VERSION ""

NS_ :

BS_:

BU_: MCTM_LS TIM_LS EOCM2cp_K2_LS EOCM2cp_K1_LS ADIMa_LS BCM_LS SAM_SR_LS SAM_SL_LS SAM_PR_LS SAM_PL_LS CGM3a_LS Dummy_LS VICM_LS ECC_LS PEPS_LS AOS_LS SDM_PR_LS AOS2_LS DLM_LS SCCM_2_LS SCCM_1_LS UPA_LS ADIMb_LS

BO_ 2150760448 Airbag_Impact_Data: 8 SDM_PR_LS
 SG_ NotiFrntLfPasSeatOccSta : 20|3@0+ (1,0) [0|7] ""  MCTM_LS,EOCM2cp_K2_LS,CGM3a_LS,ADIMa_LS,ADIMb_LS
 SG_ NotSndRwRtSeatStat : 13|2@0+ (1,0) [0|3] ""  ADIMa_LS,ADIMb_LS,CGM3a_LS,EOCM2cp_K2_LS
 SG_ NotSndRwMdlSeatStat : 11|2@0+ (1,0) [0|3] ""  ADIMa_LS,ADIMb_LS,CGM3a_LS,EOCM2cp_K2_LS
 SG_ NotSndRwLtSeatStat : 15|2@0+ (1,0) [0|3] ""  ADIMa_LS,ADIMb_LS,CGM3a_LS,EOCM2cp_K2_LS
 SG_ NotPsSeatStat : 5|2@0+ (1,0) [0|3] ""  ADIMa_LS,ADIMb_LS,CGM3a_LS,EOCM2cp_K2_LS
 SG_ NotDrvSeatStat : 7|2@0+ (1,0) [0|3] ""  ADIMa_LS,ADIMb_LS,CGM3a_LS,EOCM2cp_K2_LS
 SG_ NotSecRowRtSeaOccStat : 9|2@0+ (1,0) [0|3] ""  ADIMa_LS,ADIMb_LS,CGM3a_LS,EOCM2cp_K2_LS
 SG_ NotSecRowLeSeaOccStat : 25|2@0+ (1,0) [0|3] ""  ADIMa_LS,ADIMb_LS,CGM3a_LS,EOCM2cp_K2_LS
 SG_ NotSecRowCtSeaOccStat : 27|2@0+ (1,0) [0|3] ""  ADIMa_LS,ADIMb_LS,CGM3a_LS,EOCM2cp_K2_LS
 SG_ NotiFrntPasSeatOccSta : 34|3@0+ (1,0) [0|7] ""  ADIMa_LS,ADIMb_LS,CGM3a_LS,EOCM2cp_K2_LS
 SG_ NotEventStat : 17|2@0+ (1,0) [0|3] ""  ADIMa_LS,ADIMb_LS,CGM3a_LS,EOCM2cp_K2_LS,ECC_LS,BCM_LS
 SG_ NotiEventCount : 63|8@0+ (1,0) [0|255] ""  AOS2_LS,ADIMa_LS,ADIMb_LS,CGM3a_LS,EOCM2cp_K2_LS,AOS_LS
 SG_ NESSRoSevSt : 48|1@0+ (1,0) [0|1] ""  AOS2_LS,ADIMa_LS,ADIMb_LS,CGM3a_LS,EOCM2cp_K2_LS,ECC_LS,VICM_LS,BCM_LS,AOS_LS
 SG_ NESSRiSiSevSt : 49|1@0+ (1,0) [0|1] ""  AOS2_LS,ADIMa_LS,ADIMb_LS,CGM3a_LS,EOCM2cp_K2_LS,ECC_LS,VICM_LS,BCM_LS,AOS_LS
 SG_ NESSReImpSevSt : 50|1@0+ (1,0) [0|1] ""  AOS2_LS,ADIMa_LS,ADIMb_LS,CGM3a_LS,EOCM2cp_K2_LS,ECC_LS,VICM_LS,BCM_LS,AOS_LS
 SG_ NESSLeSiSevSt : 51|1@0+ (1,0) [0|1] ""  AOS2_LS,ADIMa_LS,ADIMb_LS,CGM3a_LS,EOCM2cp_K2_LS,ECC_LS,VICM_LS,BCM_LS,AOS_LS
 SG_ NESSFrImpSt2SevSt : 52|1@0+ (1,0) [0|1] ""  AOS2_LS,ADIMa_LS,ADIMb_LS,CGM3a_LS,EOCM2cp_K2_LS,ECC_LS,VICM_LS,BCM_LS,AOS_LS
 SG_ NESSFrImpSt1SevSt : 53|1@0+ (1,0) [0|1] ""  AOS2_LS,ADIMa_LS,ADIMb_LS,CGM3a_LS,EOCM2cp_K2_LS,ECC_LS,VICM_LS,BCM_LS,AOS_LS
 SG_ NESSFrImpPreSevSt : 54|1@0+ (1,0) [0|1] ""  AOS2_LS,ADIMa_LS,ADIMb_LS,CGM3a_LS,EOCM2cp_K2_LS,ECC_LS,VICM_LS,BCM_LS,AOS_LS
 SG_ NEDLSRtSdArbgDld : 41|1@0+ (1,0) [0|1] ""  ADIMa_LS,ADIMb_LS,CGM3a_LS,EOCM2cp_K2_LS
 SG_ NEDLSLtSdArbgDld : 42|1@0+ (1,0) [0|1] ""  ADIMa_LS,ADIMb_LS,CGM3a_LS,EOCM2cp_K2_LS
 SG_ NEDLSSdCrtnArbgDpld : 40|1@0+ (1,0) [0|1] ""  ADIMa_LS,ADIMb_LS,CGM3a_LS,EOCM2cp_K2_LS
 SG_ NEDLSPaFrSt2De : 43|1@0+ (1,0) [0|1] ""  ADIMa_LS,ADIMb_LS,CGM3a_LS,EOCM2cp_K2_LS
 SG_ NEDLSPaFrSt1De : 44|1@0+ (1,0) [0|1] ""  ADIMa_LS,ADIMb_LS,CGM3a_LS,EOCM2cp_K2_LS
 SG_ NEDLSDrFrSt2De : 45|1@0+ (1,0) [0|1] ""  ADIMa_LS,ADIMb_LS,CGM3a_LS,EOCM2cp_K2_LS
 SG_ NEDLSDrFrSt1De : 46|1@0+ (1,0) [0|1] ""  ADIMa_LS,ADIMb_LS,CGM3a_LS,EOCM2cp_K2_LS
 SG_ SIRDpl : 1|1@0+ (1,0) [0|1] ""  ADIMa_LS,ADIMb_LS,CGM3a_LS,EOCM2cp_K2_LS,VICM_LS,MCTM_LS,PEPS_LS,BCM_LS,ECC_LS

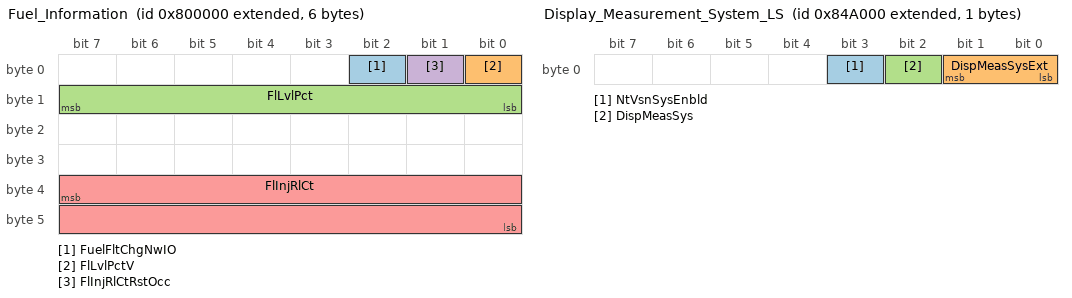
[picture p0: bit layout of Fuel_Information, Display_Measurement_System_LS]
BO_ 2155872256 Fuel_Information: 6 BCM_LS
 SG_ FuelFltChgNwIO : 2|1@0+ (1,0) [0|1] ""  CGM3a_LS
 SG_ FlLvlPctV : 0|1@0+ (1,0) [0|1] ""  CGM3a_LS
 SG_ FlLvlPct : 15|8@0+ (0.392157,0) [0|100.000035] "%"  CGM3a_LS
 SG_ FlInjRlCtRstOcc : 1|1@0+ (1,0) [0|1] ""  CGM3a_LS
 SG_ FlInjRlCt : 39|16@0+ (3.05176E-005,0) [0|1.999970916] "liters"  CGM3a_LS

BO_ 2156175360 Display_Measurement_System_LS: 1 CGM3a_LS
 SG_ NtVsnSysEnbld : 3|1@0+ (1,0) [0|1] ""  EOCM2cp_K1_LS
 SG_ DispMeasSysExt : 1|2@0+ (1,0) [0|3] ""  EOCM2cp_K1_LS,VICM_LS,ECC_LS
 SG_ DispMeasSys : 2|1@0+ (1,0) [0|1] ""  EOCM2cp_K1_LS,BCM_LS

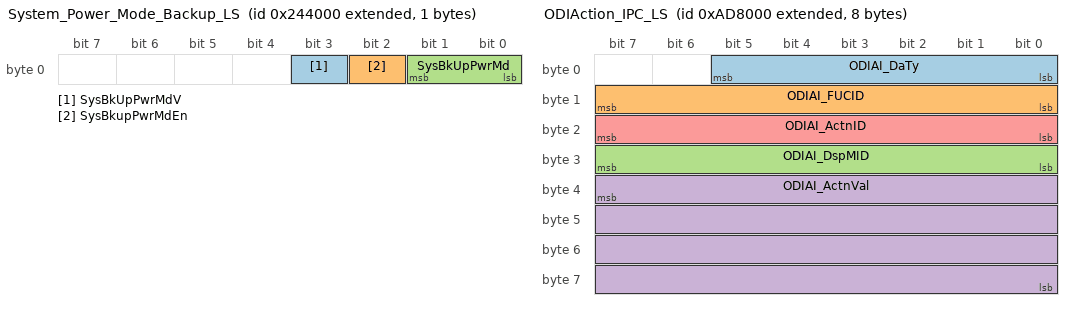
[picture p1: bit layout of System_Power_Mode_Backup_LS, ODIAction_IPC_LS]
BO_ 2149859328 System_Power_Mode_Backup_LS: 1 CGM3a_LS
 SG_ SysBkUpPwrMdV : 3|1@0+ (1,0) [0|1] ""  SAM_SR_LS,SAM_SL_LS,SAM_PR_LS,SAM_PL_LS,AOS2_LS,SCCM_2_LS,SCCM_1_LS,EOCM2cp_K2_LS,VICM_LS,TIM_LS,ECC_LS,PEPS_LS,AOS_LS,SDM_PR_LS,UPA_LS,BCM_LS
 SG_ SysBkupPwrMdEn : 2|1@0+ (1,0) [0|1] ""  SAM_SR_LS,SAM_SL_LS,SAM_PR_LS,SAM_PL_LS,AOS2_LS,SCCM_2_LS,SCCM_1_LS,MCTM_LS,EOCM2cp_K2_LS,VICM_LS,TIM_LS,ECC_LS,PEPS_LS,AOS_LS,SDM_PR_LS,UPA_LS,BCM_LS
 SG_ SysBkUpPwrMd : 1|2@0+ (1,0) [0|3] ""  SAM_SR_LS,SAM_SL_LS,SAM_PR_LS,SAM_PL_LS,AOS2_LS,SCCM_2_LS,SCCM_1_LS,MCTM_LS,EOCM2cp_K2_LS,VICM_LS,TIM_LS,ECC_LS,PEPS_LS,AOS_LS,SDM_PR_LS,UPA_LS,BCM_LS

BO_ 2158854144 ODIAction_IPC_LS: 8 CGM3a_LS
 SG_ ODIAI_DaTy : 5|6@0+ (1,0) [0|63] ""  EOCM2cp_K2_LS,UPA_LS,BCM_LS,ECC_LS
 SG_ ODIAI_FUCID : 15|8@0+ (1,0) [0|255] ""  EOCM2cp_K2_LS,UPA_LS,BCM_LS,ECC_LS
 SG_ ODIAI_DspMID : 31|8@0+ (1,0) [0|255] ""  EOCM2cp_K2_LS,UPA_LS,BCM_LS,ECC_LS
 SG_ ODIAI_ActnVal : 39|32@0+ (1,0) [0|4294967295] ""  EOCM2cp_K2_LS,UPA_LS,BCM_LS,ECC_LS
 SG_ ODIAI_ActnID : 23|8@0+ (1,0) [0|255] ""  EOCM2cp_K2_LS,UPA_LS,BCM_LS,ECC_LS

BO_ 2154561536 Vehicle_Odo_LS: 5 BCM_LS
 SG_ VehOdoV : 32|1@0+ (1,0) [0|1] ""  CGM3a_LS,VICM_LS
 SG_ VehOdo : 7|32@0+ (0.015625,0) [0|67108863.984375] "km"  CGM3a_LS,VICM_LS

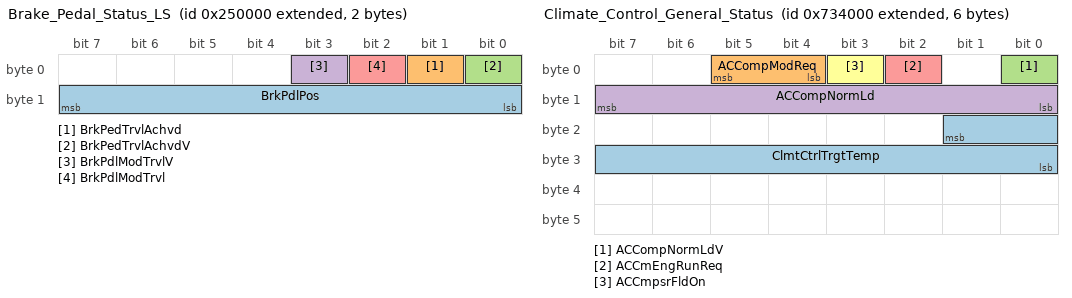
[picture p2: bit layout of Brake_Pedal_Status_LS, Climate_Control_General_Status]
BO_ 2149908480 Brake_Pedal_Status_LS: 2 BCM_LS
 SG_ BrkPdlPos : 15|8@0+ (0.392157,0) [0|100.000035] "% full"  CGM3a_LS
 SG_ BrkPedTrvlAchvd : 1|1@0+ (1,0) [0|1] ""  CGM3a_LS,SDM_PR_LS
 SG_ BrkPedTrvlAchvdV : 0|1@0+ (1,0) [0|1] ""  CGM3a_LS,SDM_PR_LS
 SG_ BrkPdlModTrvlV : 3|1@0+ (1,0) [0|1] ""  CGM3a_LS
 SG_ BrkPdlModTrvl : 2|1@0+ (1,0) [0|1] ""  CGM3a_LS

BO_ 2151268352 Column_Lock_Status: 1 BCM_LS
 SG_ ClmnLckTT : 1|2@0+ (1,0) [0|3] ""  CGM3a_LS

BO_ 2156920832 PassPhrase_Digits_1_to_8_LS: 8 CGM3a_LS
 SG_ WiFiPssPhrsDgts1to8 : 7|64@0+ (1,0) [0|0] ""  MCTM_LS

BO_ 2156937216 PassPhrase_Digits_17_to_24_LS: 8 CGM3a_LS
 SG_ WiFiPssPhrsDgts17to24 : 7|64@0+ (1,0) [0|0] ""  MCTM_LS

BO_ 2150604800 Right_Rear_Door_Status: 1 BCM_LS
 SG_ RRDoorAjarSwAct : 0|1@0+ (1,0) [0|1] ""  CGM3a_LS,MCTM_LS,BCM_LS,PEPS_LS,SDM_PR_LS

BO_ 2150588416 Passenger_Door_Status_LS: 1 BCM_LS
 SG_ PDAjrSwAtv : 0|1@0+ (1,0) [0|1] ""  MCTM_LS,CGM3a_LS,AOS_LS,PEPS_LS,SDM_PR_LS

BO_ 2150596608 Left_Rear_Door_Status: 1 BCM_LS
 SG_ RLDoorAjarSwAct : 0|1@0+ (1,0) [0|1] ""  CGM3a_LS,MCTM_LS,BCM_LS,PEPS_LS,SDM_PR_LS

BO_ 2155036672 Climate_Control_General_Status: 6 ECC_LS
 SG_ ClmtCtrlTrgtTemp : 17|10@0+ (0.1,-10) [-10|92.3] "deg C"  DLM_LS,CGM3a_LS,VICM_LS
 SG_ ACCompModReq : 5|2@0+ (1,0) [0|3] ""  CGM3a_LS,VICM_LS,BCM_LS
 SG_ ACCompNormLdV : 0|1@0+ (1,0) [0|1] ""  CGM3a_LS,BCM_LS
 SG_ ACCompNormLd : 15|8@0+ (0.1,0) [0|25.5] "l/min"  CGM3a_LS,BCM_LS
 SG_ ACCmEngRunReq : 2|1@0+ (1,0) [0|1] ""  CGM3a_LS,BCM_LS
 SG_ ACCmpsrFldOn : 3|1@0+ (1,0) [0|1] ""  CGM3a_LS,BCM_LS

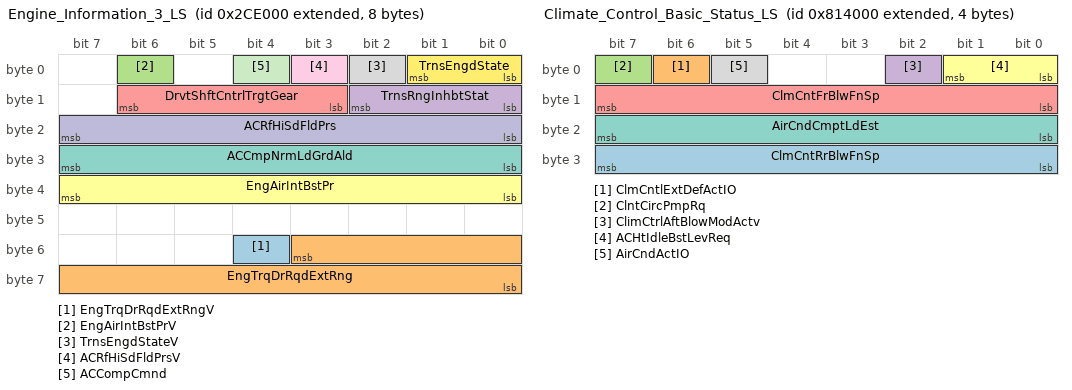
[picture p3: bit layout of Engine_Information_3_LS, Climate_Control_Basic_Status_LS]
BO_ 2150424576 Engine_Information_3_LS: 8 BCM_LS
 SG_ EngTrqDrRqdExtRngV : 52|1@0+ (1,0) [0|1] ""  CGM3a_LS
 SG_ EngTrqDrRqdExtRng : 51|12@0+ (0.5,-848) [-848|1199.5] "Nm"  CGM3a_LS
 SG_ EngAirIntBstPrV : 6|1@0+ (1,0) [0|1] ""  CGM3a_LS
 SG_ TrnsRngInhbtStat : 10|3@0+ (1,0) [0|7] ""  CGM3a_LS
 SG_ DrvtShftCntrlTrgtGear : 14|4@0+ (1,0) [0|15] ""  CGM3a_LS
 SG_ EngAirIntBstPr : 39|8@0- (1,0) [-128|127] "kPaG"  CGM3a_LS
 SG_ ACCmpNrmLdGrdAld : 31|8@0+ (0.1,0) [0|25.5] "dm3/m/s"  CGM3a_LS,ECC_LS
 SG_ TrnsEngdStateV : 2|1@0+ (1,0) [0|1] ""  CGM3a_LS
 SG_ ACRfHiSdFldPrsV : 3|1@0+ (1,0) [0|1] ""  CGM3a_LS,ECC_LS
 SG_ ACRfHiSdFldPrs : 23|8@0+ (14,0) [0|3570] "kPaG"  CGM3a_LS,ECC_LS
 SG_ ACCompCmnd : 4|1@0+ (1,0) [0|1] ""  CGM3a_LS,ECC_LS
 SG_ TrnsEngdState : 1|2@0+ (1,0) [0|3] ""  CGM3a_LS

BO_ 2150416384 Engine_Information_2_LS: 8 BCM_LS
 SG_ PTWrmgWtToShftIO : 5|1@0+ (1,0) [0|1] ""  SAM_SR_LS,SAM_SL_LS,SAM_PR_LS,SAM_PL_LS,CGM3a_LS
 SG_ EngTrqActExtRngV : 21|1@0+ (1,0) [0|1] ""  SAM_SR_LS,SAM_SL_LS,SAM_PR_LS,SAM_PL_LS,CGM3a_LS,SDM_PR_LS
 SG_ VehTopSpdLmtMdAct : 13|1@0+ (1,0) [0|1] ""  SAM_SR_LS,SAM_SL_LS,SAM_PR_LS,SAM_PL_LS,CGM3a_LS
 SG_ EngTrqActExtRng : 51|12@0+ (0.5,-848) [-848|1199.5] "Nm"  SAM_SR_LS,SAM_SL_LS,SAM_PR_LS,SAM_PL_LS,CGM3a_LS,SDM_PR_LS
 SG_ EngRunAtv : 8|1@0+ (1,0) [0|1] ""  SAM_SR_LS,SAM_SL_LS,SAM_PR_LS,SAM_PL_LS,AOS2_LS,SCCM_2_LS,SCCM_1_LS,CGM3a_LS,TIM_LS,AOS_LS,ECC_LS,SDM_PR_LS
 SG_ EngIdlAtv : 11|1@0+ (1,0) [0|1] ""  SAM_SR_LS,SAM_SL_LS,SAM_PR_LS,SAM_PL_LS,CGM3a_LS
 SG_ EngSpdStat : 53|2@0+ (1,0) [0|3] ""  SAM_SR_LS,SAM_SL_LS,SAM_PR_LS,SAM_PL_LS,CGM3a_LS,SDM_PR_LS
 SG_ VaccBoostFailure : 2|1@0+ (1,0) [0|1] ""  SAM_SR_LS,SAM_SL_LS,SAM_PR_LS,SAM_PL_LS,CGM3a_LS
 SG_ RmVhStrtEngRng : 54|1@0+ (1,0) [0|1] ""  SAM_SR_LS,SAM_SL_LS,SAM_PR_LS,SAM_PL_LS,CGM3a_LS,ECC_LS
 SG_ EngCoolFanSpd : 31|8@0+ (0.392157,0) [0|100.000035] "%"  SAM_SR_LS,SAM_SL_LS,SAM_PR_LS,SAM_PL_LS,CGM3a_LS,ECC_LS
 SG_ TrnsVDA : 23|1@0+ (1,0) [0|1] ""  SAM_SR_LS,SAM_SL_LS,SAM_PR_LS,SAM_PL_LS,CGM3a_LS,PEPS_LS,UPA_LS,ECC_LS,SDM_PR_LS
 SG_ GenFld : 3|1@0+ (1,0) [0|1] ""  SAM_SR_LS,SAM_SL_LS,SAM_PR_LS,SAM_PL_LS,CGM3a_LS
 SG_ EngSpdLmtnMdAct : 4|1@0+ (1,0) [0|1] ""  SAM_SR_LS,SAM_SL_LS,SAM_PR_LS,SAM_PL_LS,CGM3a_LS
 SG_ EngNEmsnsRelMalfAct : 6|1@0+ (1,0) [0|1] ""  SAM_SR_LS,SAM_SL_LS,SAM_PR_LS,SAM_PL_LS,CGM3a_LS
 SG_ EngCstFlCutAct : 7|1@0+ (1,0) [0|1] ""  SAM_SR_LS,SAM_SL_LS,SAM_PR_LS,SAM_PL_LS,CGM3a_LS,ECC_LS
 SG_ EngCylDeactMd : 15|2@0+ (1,0) [0|3] ""  SAM_SR_LS,SAM_SL_LS,SAM_PR_LS,SAM_PL_LS,CGM3a_LS
 SG_ EngBstPrsIndV : 0|1@0+ (1,0) [0|1] ""  SAM_SR_LS,SAM_SL_LS,SAM_PR_LS,SAM_PL_LS,CGM3a_LS
 SG_ EngBstPrsInd : 39|8@0+ (0.392157,0) [0|100.000035] "%"  SAM_SR_LS,SAM_SL_LS,SAM_PR_LS,SAM_PL_LS,CGM3a_LS
 SG_ TransEstGear : 19|4@0+ (1,0) [0|15] ""  SAM_SR_LS,SAM_SL_LS,SAM_PR_LS,SAM_PL_LS,SDM_PR_LS,CGM3a_LS,UPA_LS
 SG_ TransEstGearV : 20|1@0+ (1,0) [0|1] ""  SAM_SR_LS,SAM_SL_LS,SAM_PR_LS,SAM_PL_LS,SDM_PR_LS,CGM3a_LS,UPA_LS
 SG_ EngVDA : 22|1@0+ (1,0) [0|1] ""  SAM_SR_LS,SAM_SL_LS,SAM_PR_LS,SAM_PL_LS,CGM3a_LS,UPA_LS,PEPS_LS,SDM_PR_LS,ECC_LS
 SG_ TrnCrpMdAtv : 55|1@0+ (1,0) [0|1] ""  SAM_SR_LS,SAM_SL_LS,SAM_PR_LS,SAM_PL_LS,CGM3a_LS
 SG_ VehTopSpdLmtArbVal : 47|8@0+ (2,0) [0|510] "km / h"  SAM_SR_LS,SAM_SL_LS,SAM_PR_LS,SAM_PL_LS,CGM3a_LS

BO_ 2150408192 Engine_Information_1_LS: 8 BCM_LS
 SG_ ElcRngSelDrvAct : 5|1@0+ (1,0) [0|1] ""  SAM_SR_LS,SAM_SL_LS,SAM_PR_LS,SAM_PL_LS,CGM3a_LS
 SG_ TmpDrvrShftCtlAct : 6|1@0+ (1,0) [0|1] ""  SAM_SR_LS,SAM_SL_LS,SAM_PR_LS,SAM_PL_LS,CGM3a_LS
 SG_ EngRunng : 14|1@0+ (1,0) [0|1] ""  SAM_SR_LS,SAM_SL_LS,SAM_PR_LS,SAM_PL_LS,CGM3a_LS
 SG_ Eng12vStrtrMtrCmmdOn : 13|1@0+ (1,0) [0|1] ""  SAM_SR_LS,SAM_SL_LS,SAM_PR_LS,SAM_PL_LS,CGM3a_LS
 SG_ AccPdlOvrrdAtv : 7|1@0+ (1,0) [0|1] ""  SAM_SR_LS,SAM_SL_LS,SAM_PR_LS,SAM_PL_LS,CGM3a_LS
 SG_ TopTrvlCltchSwActV : 60|1@0+ (1,0) [0|1] ""  SAM_SR_LS,SAM_SL_LS,SAM_PR_LS,SAM_PL_LS,CGM3a_LS
 SG_ TopTrvlCltchSwAct : 59|1@0+ (1,0) [0|1] ""  SAM_SR_LS,SAM_SL_LS,SAM_PR_LS,SAM_PL_LS,CGM3a_LS
 SG_ CltStartSwAtvV : 58|1@0+ (1,0) [0|1] ""  SAM_SR_LS,SAM_SL_LS,SAM_PR_LS,SAM_PL_LS,CGM3a_LS
 SG_ CltStartSwAtv : 57|1@0+ (1,0) [0|1] ""  SAM_SR_LS,SAM_SL_LS,SAM_PR_LS,SAM_PL_LS,CGM3a_LS
 SG_ CrsCntEnbld : 56|1@0+ (1,0) [0|1] ""  SAM_SR_LS,SAM_SL_LS,SAM_PR_LS,SAM_PL_LS,CGM3a_LS
 SG_ AccActPosV : 4|1@0+ (1,0) [0|1] ""  SAM_SR_LS,SAM_SL_LS,SAM_PR_LS,SAM_PL_LS,CGM3a_LS,SDM_PR_LS
 SG_ TrnsShftLvrPosV : 15|1@0+ (1,0) [0|1] ""  SAM_SR_LS,SAM_SL_LS,SAM_PR_LS,SAM_PL_LS,CGM3a_LS,SDM_PR_LS,UPA_LS
 SG_ TrnsSftMdStat : 2|3@0+ (1,0) [0|7] ""  SAM_SR_LS,SAM_SL_LS,SAM_PR_LS,SAM_PL_LS,CGM3a_LS
 SG_ EngSpd : 23|16@0+ (0.25,0) [0|16383.75] "rpm"  SAM_SR_LS,SAM_SL_LS,SAM_PR_LS,SAM_PL_LS,CGM3a_LS,SDM_PR_LS,ECC_LS
 SG_ AutoTransComndGear : 55|4@0+ (1,0) [0|15] ""  SAM_SR_LS,SAM_SL_LS,SAM_PR_LS,SAM_PL_LS,CGM3a_LS
 SG_ TrnShftPtrnActStat : 10|3@0+ (1,0) [0|7] ""  SAM_SR_LS,SAM_SL_LS,SAM_PR_LS,SAM_PL_LS,CGM3a_LS
 SG_ TrnsShftLvrPos : 51|4@0+ (1,0) [0|15] ""  SAM_SR_LS,SAM_SL_LS,SAM_PR_LS,SAM_PL_LS,CGM3a_LS,SDM_PR_LS,UPA_LS
 SG_ AccActPos : 47|8@0+ (0.392157,0) [0|100.000035] "%"  SAM_SR_LS,SAM_SL_LS,SAM_PR_LS,SAM_PL_LS,CGM3a_LS,SDM_PR_LS
 SG_ ThrPosV : 3|1@0+ (1,0) [0|1] ""  SAM_SR_LS,SAM_SL_LS,SAM_PR_LS,SAM_PL_LS,CGM3a_LS,SDM_PR_LS
 SG_ TransTUDMdStat : 12|2@0+ (1,0) [0|3] ""  SAM_SR_LS,SAM_SL_LS,SAM_PR_LS,SAM_PL_LS,CGM3a_LS
 SG_ ThrPos : 39|8@0+ (0.392157,0) [0|100.000035] "%"  SAM_SR_LS,SAM_SL_LS,SAM_PR_LS,SAM_PL_LS,CGM3a_LS,SDM_PR_LS

BO_ 2155954176 Climate_Control_Basic_Status_LS: 4 ECC_LS
 SG_ ClmCntRrBlwFnSp : 31|8@0+ (0.392157,0) [0|100.000035] "%"  SAM_SR_LS,SAM_SL_LS,SAM_PR_LS,SAM_PL_LS,CGM3a_LS
 SG_ ClmCntlExtDefActIO : 6|1@0+ (1,0) [0|1] ""  SAM_SR_LS,SAM_SL_LS,SAM_PR_LS,SAM_PL_LS,CGM3a_LS
 SG_ ClntCircPmpRq : 7|1@0+ (1,0) [0|1] ""  SAM_SR_LS,SAM_SL_LS,SAM_PR_LS,SAM_PL_LS,CGM3a_LS,BCM_LS
 SG_ ClimCtrlAftBlowModActv : 2|1@0+ (1,0) [0|1] ""  SAM_SR_LS,SAM_SL_LS,SAM_PR_LS,SAM_PL_LS,CGM3a_LS,BCM_LS
 SG_ ClmCntFrBlwFnSp : 15|8@0+ (0.392157,0) [0|100.000035] "%"  SAM_SR_LS,SAM_SL_LS,SAM_PR_LS,SAM_PL_LS,DLM_LS,CGM3a_LS,VICM_LS,BCM_LS
 SG_ ACHtIdleBstLevReq : 1|2@0+ (1,0) [0|3] ""  SAM_SR_LS,SAM_SL_LS,SAM_PR_LS,SAM_PL_LS,CGM3a_LS,BCM_LS
 SG_ AirCndCmptLdEst : 23|8@0+ (0.392157,0) [0|100.000035] "%"  SAM_SR_LS,SAM_SL_LS,SAM_PR_LS,SAM_PL_LS,CGM3a_LS
 SG_ AirCndActIO : 5|1@0+ (1,0) [0|1] ""  SAM_SR_LS,SAM_SL_LS,SAM_PR_LS,SAM_PL_LS,CGM3a_LS

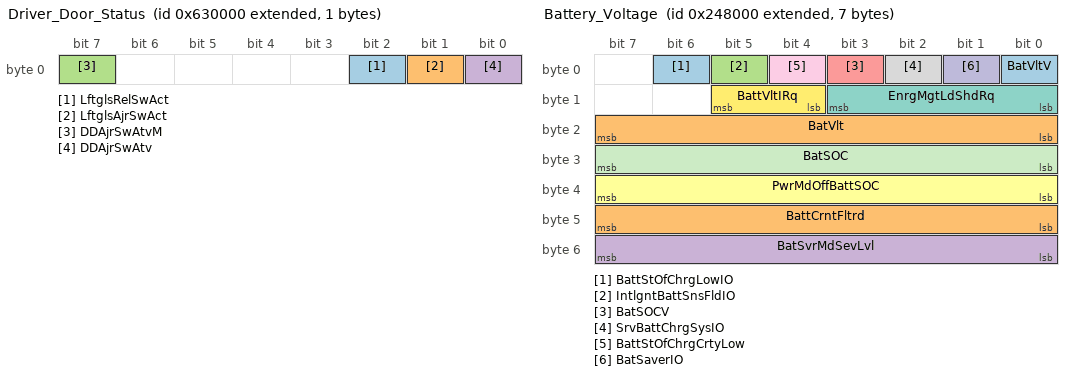
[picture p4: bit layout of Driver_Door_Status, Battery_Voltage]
BO_ 2153971712 Driver_Door_Status: 1 BCM_LS
 SG_ LftglsRelSwAct : 2|1@0+ (1,0) [0|1] ""  CGM3a_LS,PEPS_LS
 SG_ LftglsAjrSwAct : 1|1@0+ (1,0) [0|1] ""  CGM3a_LS
 SG_ DDAjrSwAtvM : 7|1@0+ (1,0) [0|1] ""  MCTM_LS,CGM3a_LS
 SG_ DDAjrSwAtv : 0|1@0+ (1,0) [0|1] ""  AOS2_LS,MCTM_LS,CGM3a_LS,VICM_LS,PEPS_LS,SDM_PR_LS

BO_ 2149875712 Battery_Voltage: 7 BCM_LS
 SG_ BattStOfChrgLowIO : 6|1@0+ (1,0) [0|1] ""  CGM3a_LS
 SG_ BattCrntFltrd : 47|8@0- (0.5,0) [-64|63.5] "A"  VICM_LS,CGM3a_LS,ECC_LS
 SG_ IntlgntBattSnsFldIO : 5|1@0+ (1,0) [0|1] ""  CGM3a_LS
 SG_ BatSvrMdSevLvl : 55|8@0+ (1,0) [0|255] ""  CGM3a_LS
 SG_ BatSOCV : 3|1@0+ (1,0) [0|1] ""  CGM3a_LS,ECC_LS
 SG_ PwrMdOffBattSOC : 39|8@0+ (0.392157,0) [0|100.000035] "%"  CGM3a_LS
 SG_ EnrgMgtLdShdRq : 11|4@0+ (1,0) [0|15] ""  SCCM_2_LS,SCCM_1_LS,CGM3a_LS,ECC_LS
 SG_ SrvBattChrgSysIO : 2|1@0+ (1,0) [0|1] ""  CGM3a_LS
 SG_ BattStOfChrgCrtyLow : 4|1@0+ (1,0) [0|1] ""  CGM3a_LS,ECC_LS
 SG_ BatSaverIO : 1|1@0+ (1,0) [0|1] ""  CGM3a_LS
 SG_ BatSOC : 31|8@0+ (0.392157,0) [0|100.000035] "%"  PEPS_LS,CGM3a_LS,ECC_LS
 SG_ BattVltIRq : 13|2@0+ (1,0) [0|3] ""  CGM3a_LS
 SG_ BatVltV : 0|1@0+ (1,0) [0|1] ""  SCCM_2_LS,SCCM_1_LS,CGM3a_LS,ECC_LS
 SG_ BatVlt : 23|8@0+ (0.1,3) [3|28.5] "volts"  SCCM_2_LS,SCCM_1_LS,CGM3a_LS,PEPS_LS,ECC_LS

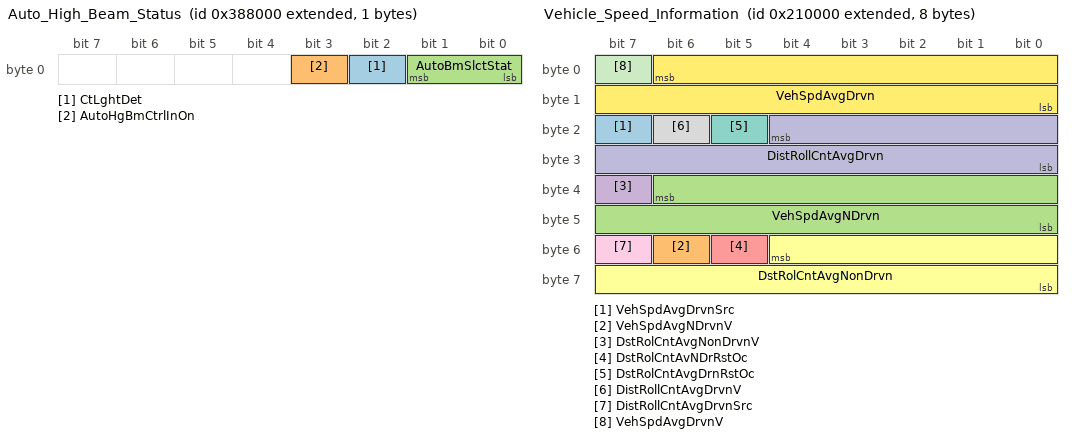
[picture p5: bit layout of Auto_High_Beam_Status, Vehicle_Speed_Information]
BO_ 2151186432 Auto_High_Beam_Status: 1 EOCM2cp_K2_LS
 SG_ CtLghtDet : 2|1@0+ (1,0) [0|1] ""  CGM3a_LS,BCM_LS
 SG_ AutoHgBmCtrlInOn : 3|1@0+ (1,0) [0|1] ""  CGM3a_LS
 SG_ AutoBmSlctStat : 1|2@0+ (1,0) [0|3] ""  CGM3a_LS,BCM_LS

BO_ 2149629952 Lighting_Status_LS: 5 BCM_LS
 SG_ FrFogLmpsAct : 7|1@0+ (1,0) [0|1] ""  ADIMa_LS,ADIMb_LS,CGM3a_LS,EOCM2cp_K1_LS
 SG_ HiBmReqd : 20|1@0+ (1,0) [0|1] ""  ADIMa_LS,ADIMb_LS,CGM3a_LS,EOCM2cp_K1_LS
 SG_ PrkLtRightOn : 22|1@0+ (1,0) [0|1] ""  ADIMa_LS,ADIMb_LS,CGM3a_LS,TIM_LS
 SG_ PrkLtLeftOn : 8|1@0+ (1,0) [0|1] ""  ADIMa_LS,ADIMb_LS,CGM3a_LS,TIM_LS
 SG_ TrnSwAct : 6|2@0+ (1,0) [0|3] ""  ADIMa_LS,ADIMb_LS,CGM3a_LS,EOCM2cp_K2_LS,EOCM2cp_K1_LS,UPA_LS
 SG_ PrkLtRightIO : 4|1@0+ (1,0) [0|1] ""  ADIMa_LS,ADIMb_LS,CGM3a_LS
 SG_ MainLghtSw : 31|2@0+ (1,0) [0|3] "N/A"  ADIMa_LS,ADIMb_LS,CGM3a_LS,EOCM2cp_K1_LS
 SG_ PrkLtLeftIO : 3|1@0+ (1,0) [0|1] ""  ADIMa_LS,ADIMb_LS,CGM3a_LS
 SG_ HazSwAtv : 2|1@0+ (1,0) [0|1] ""  ADIMa_LS,ADIMb_LS,CGM3a_LS,TIM_LS
 SG_ HiBmIO : 13|1@0+ (1,0) [0|1] ""  ADIMa_LS,ADIMb_LS,CGM3a_LS
 SG_ FrFgLtIO : 9|1@0+ (1,0) [0|1] ""  ADIMa_LS,ADIMb_LS,CGM3a_LS
 SG_ AutoLtsInactIO : 10|1@0+ (1,0) [0|1] ""  ADIMa_LS,ADIMb_LS,CGM3a_LS
 SG_ AutoLtsActIO : 11|1@0+ (1,0) [0|1] ""  ADIMa_LS,ADIMb_LS,CGM3a_LS
 SG_ LftTrnLmpAtv : 29|2@0+ (1,0) [0|3] ""  ADIMa_LS,ADIMb_LS,CGM3a_LS,EOCM2cp_K2_LS,EOCM2cp_K1_LS,UPA_LS,TIM_LS
 SG_ RtTrnLmpAtv : 25|2@0+ (1,0) [0|3] ""  ADIMa_LS,ADIMb_LS,CGM3a_LS,EOCM2cp_K2_LS,EOCM2cp_K1_LS,UPA_LS,TIM_LS
 SG_ RevLmpAtv : 17|1@0+ (1,0) [0|1] "N/A"  ADIMa_LS,ADIMb_LS,CGM3a_LS,TIM_LS
 SG_ HdlmpBmSelectStat : 33|2@0+ (1,0) [0|3] ""  ADIMa_LS,ADIMb_LS,CGM3a_LS,EOCM2cp_K1_LS
 SG_ SrvlnceMdAct : 23|1@0+ (1,0) [0|1] ""  ADIMa_LS,ADIMb_LS,CGM3a_LS,EOCM2cp_K1_LS
 SG_ RrFgLtIO : 12|1@0+ (1,0) [0|1] ""  ADIMa_LS,ADIMb_LS,CGM3a_LS
 SG_ PrkLtIO : 14|1@0+ (1,0) [0|1] ""  ADIMa_LS,ADIMb_LS,CGM3a_LS
 SG_ OtsdAmbtLtLvlStatV : 0|1@0+ (1,0) [0|1] ""  ADIMa_LS,ADIMb_LS,CGM3a_LS,EOCM2cp_K2_LS,EOCM2cp_K1_LS,UPA_LS
 SG_ OtsdAmbtLtLvlStat : 27|2@0+ (1,0) [0|3] ""  ADIMa_LS,ADIMb_LS,CGM3a_LS,EOCM2cp_K2_LS,EOCM2cp_K1_LS,UPA_LS
 SG_ RrFogLmpsAct : 19|1@0+ (1,0) [0|1] ""  ADIMa_LS,ADIMb_LS,CGM3a_LS,EOCM2cp_K1_LS,TIM_LS
 SG_ PrkngLtsAct : 18|1@0+ (1,0) [0|1] ""  ADIMa_LS,ADIMb_LS,CGM3a_LS,TIM_LS
 SG_ BrkLtsAtv : 15|1@0+ (1,0) [0|1] ""  ADIMa_LS,ADIMb_LS,CGM3a_LS,TIM_LS
 SG_ AutoBmSlctAllwd : 21|1@0+ (1,0) [0|1] ""  ADIMa_LS,ADIMb_LS,CGM3a_LS,EOCM2cp_K1_LS
 SG_ FlToPsSwAtv : 16|1@0+ (1,0) [0|1] ""  ADIMa_LS,ADIMb_LS,CGM3a_LS,EOCM2cp_K1_LS
 SG_ DRLAct : 1|1@0+ (1,0) [0|1] ""  ADIMa_LS,ADIMb_LS,CGM3a_LS

BO_ 2149646336 Vehicle_Speed_Information: 8 BCM_LS
 SG_ VehSpdAvgDrvnSrc : 23|1@0+ (1,0) [0|1] ""  SAM_SR_LS,SAM_SL_LS,SAM_PR_LS,SAM_PL_LS,CGM3a_LS
 SG_ VehSpdAvgNDrvnV : 54|1@0+ (1,0) [0|1] ""  SAM_SR_LS,SAM_SL_LS,SAM_PR_LS,SAM_PL_LS,CGM3a_LS,SDM_PR_LS,MCTM_LS,UPA_LS
 SG_ VehSpdAvgNDrvn : 38|15@0+ (0.015625,0) [0|511.984375] "km / h"  SAM_SR_LS,SAM_SL_LS,SAM_PR_LS,SAM_PL_LS,CGM3a_LS,SDM_PR_LS,MCTM_LS,UPA_LS
 SG_ DstRolCntAvgNonDrvnV : 39|1@0+ (1,0) [0|1] ""  SAM_SR_LS,SAM_SL_LS,SAM_PR_LS,SAM_PL_LS,CGM3a_LS
 SG_ DstRolCntAvNDrRstOc : 53|1@0+ (1,0) [0|1] ""  SAM_SR_LS,SAM_SL_LS,SAM_PR_LS,SAM_PL_LS,CGM3a_LS
 SG_ DstRolCntAvgNonDrvn : 52|13@0+ (0.125,0) [0|1023.875] "m"  SAM_SR_LS,SAM_SL_LS,SAM_PR_LS,SAM_PL_LS,CGM3a_LS
 SG_ DstRolCntAvgDrnRstOc : 21|1@0+ (1,0) [0|1] ""  SAM_SR_LS,SAM_SL_LS,SAM_PR_LS,SAM_PL_LS,CGM3a_LS
 SG_ DistRollCntAvgDrvnV : 22|1@0+ (1,0) [0|1] ""  SAM_SR_LS,SAM_SL_LS,SAM_PR_LS,SAM_PL_LS,CGM3a_LS,SDM_PR_LS
 SG_ DistRollCntAvgDrvnSrc : 55|1@0+ (1,0) [0|1] ""  SAM_SR_LS,SAM_SL_LS,SAM_PR_LS,SAM_PL_LS,CGM3a_LS
 SG_ DistRollCntAvgDrvn : 20|13@0+ (0.125,0) [0|1023.875] "m"  SAM_SR_LS,SAM_SL_LS,SAM_PR_LS,SAM_PL_LS,CGM3a_LS,SDM_PR_LS
 SG_ VehSpdAvgDrvnV : 7|1@0+ (1,0) [0|1] ""  SAM_SR_LS,SAM_SL_LS,SAM_PR_LS,SAM_PL_LS,SCCM_2_LS,SCCM_1_LS,CGM3a_LS,AOS2_LS,UPA_LS,TIM_LS,PEPS_LS,AOS_LS,SDM_PR_LS,ECC_LS
 SG_ VehSpdAvgDrvn : 6|15@0+ (0.015625,0) [0|511.984375] "km / h"  SAM_SR_LS,SAM_SL_LS,SAM_PR_LS,SAM_PL_LS,SCCM_2_LS,SCCM_1_LS,CGM3a_LS,AOS2_LS,TIM_LS,UPA_LS,PEPS_LS,AOS_LS,SDM_PR_LS,ECC_LS

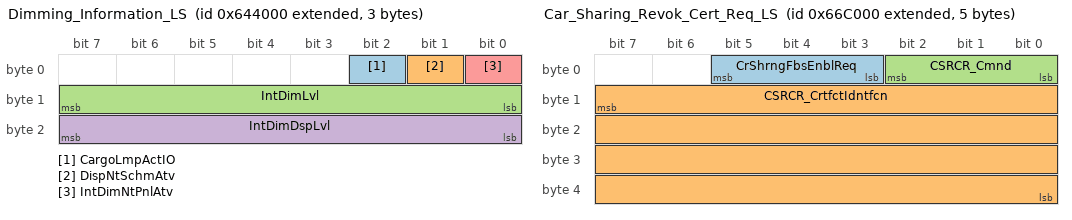
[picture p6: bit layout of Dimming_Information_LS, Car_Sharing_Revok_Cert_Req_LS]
BO_ 2154053632 Dimming_Information_LS: 3 BCM_LS
 SG_ CargoLmpActIO : 2|1@0+ (1,0) [0|1] ""  CGM3a_LS,EOCM2cp_K2_LS
 SG_ DispNtSchmAtv : 1|1@0+ (1,0) [0|1] ""  MCTM_LS,CGM3a_LS,EOCM2cp_K2_LS,ECC_LS,SDM_PR_LS
 SG_ IntDimLvl : 15|8@0+ (0.392157,0) [0|100.000035] "%"  CGM3a_LS,EOCM2cp_K2_LS,ECC_LS
 SG_ IntDimDspLvl : 23|8@0+ (0.392157,0) [0|100.000035] "%"  CGM3a_LS,EOCM2cp_K2_LS,SDM_PR_LS,ECC_LS
 SG_ IntDimNtPnlAtv : 0|1@0+ (1,0) [0|1] ""  CGM3a_LS,EOCM2cp_K2_LS,ECC_LS

BO_ 1623 USDT_Resp_From_ADIMa_LS: 8 ADIMa_LS
 SG_ DgnInf : 7|64@0+ (1,0) [0|1.84467440737096E+019] ""  CGM3a_LS

BO_ 2154217472 Car_Sharing_Revok_Cert_Req_LS: 5 CGM3a_LS
 SG_ CrShrngFbsEnblReq : 5|3@0+ (1,0) [0|7] ""  BCM_LS
 SG_ CSRCR_CrtfctIdntfcn : 15|32@0+ (1,0) [0|4294967295] ""  BCM_LS
 SG_ CSRCR_Cmnd : 2|3@0+ (1,0) [0|7] ""  BCM_LS

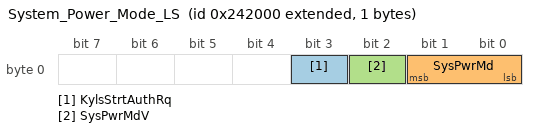
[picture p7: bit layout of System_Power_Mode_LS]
BO_ 2149851136 System_Power_Mode_LS: 1 BCM_LS
 SG_ KylsStrtAuthRq : 3|1@0+ (1,0) [0|1] ""  SAM_SR_LS,SAM_SL_LS,SAM_PR_LS,SAM_PL_LS,CGM3a_LS,PEPS_LS
 SG_ SysPwrMd : 1|2@0+ (1,0) [0|3] ""  SAM_SR_LS,SAM_SL_LS,SAM_PR_LS,SAM_PL_LS,SCCM_2_LS,SCCM_1_LS,AOS2_LS,CGM3a_LS,TIM_LS,ECC_LS,PEPS_LS,AOS_LS,SDM_PR_LS,UPA_LS,MCTM_LS
 SG_ SysPwrMdV : 2|1@0+ (1,0) [0|1] ""  SAM_SR_LS,SAM_SL_LS,SAM_PR_LS,SAM_PL_LS,SCCM_2_LS,SCCM_1_LS,AOS2_LS,CGM3a_LS,TIM_LS,ECC_LS,PEPS_LS,AOS_LS,SDM_PR_LS,UPA_LS

BO_ 2033 PCU_Req_to_SDM_LS: 8 BCM_LS
 SG_ PCUInfo : 7|64@0+ (1,0) [0|1.84467440737096E+019] ""  SDM_PR_LS

BO_ 587 USDT_Req_to_EOCM2cp_K2_LS: 8 CGM3a_LS
 SG_ DgnInf : 7|64@0+ (1,0) [0|1.84467440737096E+019] ""  CGM3a_LS,EOCM2cp_K2_LS

BO_ 2151530496 TPM_Display_Commands: 6 BCM_LS
 SG_ OfBrdHVCVhCsChRqRmt1 : 23|1@0+ (1,0) [0|1] ""  ADIMa_LS,ADIMb_LS,VICM_LS,CGM3a_LS
 SG_ PrtyChrgRqRmt1 : 22|2@0+ (1,0) [0|3] ""  ADIMa_LS,ADIMb_LS,CGM3a_LS,VICM_LS
 SG_ StTODChrgTmpOvrdRmt1 : 20|2@0+ (1,0) [0|3] ""  ADIMa_LS,ADIMb_LS,CGM3a_LS,VICM_LS
 SG_ HVChgSyChgLvPfStRmt1 : 18|3@0+ (1,0) [0|7] ""  ADIMa_LS,ADIMb_LS,VICM_LS,CGM3a_LS
 SG_ HVBatTmBsChgMdRqRmt1 : 31|3@0+ (1,0) [0|7] ""  ADIMa_LS,ADIMb_LS,VICM_LS,CGM3a_LS
 SG_ HVBTBDCSRR1_DChMHSRq : 45|6@0+ (1,0) [0|63] "min"  ADIMa_LS,ADIMb_LS,VICM_LS,CGM3a_LS
 SG_ HVBTBDCSRR1_DChSnSRq : 47|2@0+ (1,0) [0|3] ""  ADIMa_LS,ADIMb_LS,VICM_LS,CGM3a_LS
 SG_ HVBTBDCSRR1_DChSlSRq : 35|4@0+ (1,0) [0|15] ""  ADIMa_LS,ADIMb_LS,VICM_LS,CGM3a_LS
 SG_ HVBTBDCSRR1_DChDStRq : 39|4@0+ (1,0) [0|15] ""  ADIMa_LS,ADIMb_LS,VICM_LS,CGM3a_LS
 SG_ HVBTBDCSRR1_DChHStRq : 28|5@0+ (1,0) [0|31] "hr"  ADIMa_LS,ADIMb_LS,VICM_LS,CGM3a_LS
 SG_ TrPrsMntrTrLdStat : 3|2@0+ (1,0) [0|3] ""  ADIMa_LS,ADIMb_LS,CGM3a_LS
 SG_ TrPrsMntrAtLocFld : 1|1@0+ (1,0) [0|1] ""  ADIMa_LS,ADIMb_LS,CGM3a_LS
 SG_ TireLocatnWarnEn : 15|1@0+ (1,0) [0|1] ""  ADIMa_LS,ADIMb_LS,CGM3a_LS
 SG_ WintTrRecIndOn : 12|1@0+ (1,0) [0|1] ""  ADIMa_LS,ADIMb_LS,CGM3a_LS
 SG_ TrPrsMntrFld : 13|1@0+ (1,0) [0|1] ""  ADIMa_LS,ADIMb_LS,CGM3a_LS
 SG_ TrRrAxlPresStat : 11|2@0+ (1,0) [0|3] ""  ADIMa_LS,ADIMb_LS,CGM3a_LS
 SG_ TrFrntAxlPresStat : 9|2@0+ (1,0) [0|3] ""  ADIMa_LS,ADIMb_LS,CGM3a_LS
 SG_ TPMTrLrnMdCmplt : 0|1@0+ (1,0) [0|1] ""  ADIMa_LS,ADIMb_LS,CGM3a_LS

BO_ 1625 USDT_Resp_From_UPA_LS: 8 UPA_LS
 SG_ DgnInf : 7|64@0+ (1,0) [0|1.84467440737096E+019] ""  CGM3a_LS

BO_ 1349 UUDT_Resp_From_AOS_LS: 8 AOS_LS
 SG_ DgnInf_LS545 : 7|64@0+ (1,0) [0|1.84467440737096E+019] ""  CGM3a_LS

BO_ 1605 USDT_Resp_From_AOS_LS: 8 AOS_LS
 SG_ DgnInf : 7|64@0+ (1,0) [0|1.84467440737096E+019] ""  CGM3a_LS

BO_ 581 USDT_Req_to_AOS_LS: 8 CGM3a_LS
 SG_ DgnInf : 7|64@0+ (1,0) [0|1.84467440737096E+019] ""  CGM3a_LS,AOS_LS

BO_TX_BU_ 2155954176 : BCM_LS,ECC_LS;
CM_ BO_ 2158854144 "LAP: Signalerna är inte riktigt kodade!!!        ODI";
CM_ SG_ 2158854144 ODIAI_FUCID "ODI - Primary ID of Functional Unit in FU Database";
CM_ SG_ 2158854144 ODIAI_DspMID "ODI - ID that identifies the display requesting the data.  See detailed requirements in ODI GMLAN Protocol.";
CM_ SG_ 2158854144 ODIAI_ActnVal "ODI-Integer value for Actions with values.
FUDatabase definition of Action includes ActionDataType that defines whether or not Action has a value. 
For Actions without a value, this field is always sent as 0.";
CM_ SG_ 2158854144 ODIAI_ActnID "ODI-ActionId within the FUClass";
CM_ SG_ 2149908480 BrkPdlModTrvlV "Indicates that the brake pedal position has passed a threshold for brake torque management and some 2 channel Vehicle Dynamics Control systems.";
CM_ SG_ 2149908480 BrkPdlModTrvl "Indicates that the brake pedal position has passed a threshold for brake torque management and some 2 channel Vehicle Dynamics Control systems.";
CM_ SG_ 2150424576 ACCmpNrmLdGrdAld "dm3/m/s = dm3/minute/second";
CM_ SG_ 2150416384 EngRunAtv "Indication from powertrain that the engine is running (Has RPM > 0)";
CM_ SG_ 2150408192 TrnShftPtrnActStat "(PT = Powertrain)";
CM_ SG_ 2149629952 MainLghtSw "Operator selection for the main lighting switch";
CM_ SG_ 2149629952 RevLmpAtv "Indicates if backup lamps are active - Changed name to Reversing Lamps Active";
CM_ BO_ 2151530496 "LAP: Kolla oxå 0x3BA.         Imported from CA8.50 (5501)";
CM_ SG_ 2151530496 TrRrAxlPresStat "Not required for C100 DIC";
CM_ SG_ 2151530496 TrFrntAxlPresStat "Not required for C100 DIC";
BA_DEF_ SG_  "VNSigPrimaryTriggering" ENUM  "No","Yes";
BA_DEF_ SG_  "VNSigRemoteDiagnostics" ENUM  "No","Yes";
BA_DEF_ SG_  "VNSigInfotainment" ENUM  "No","Yes";
BA_DEF_ SG_  "VNSigParkedVehicle" ENUM  "No","Yes";
BA_DEF_ SG_  "VNSigIntermediate" ENUM  "No","Yes";
BA_DEF_ SG_  "VNSigUnused_4" ENUM  "No","Yes";
BA_DEF_ SG_  "SignalType" STRING ;
BA_DEF_ SG_  "PacketOrder" INT 0 65535;
BA_DEF_ SG_  "SignalLongName" STRING ;
BA_DEF_ SG_  "GenSigStartValue" INT 0 65535;
BA_DEF_ SG_  "VNSigDiagnostic" ENUM  "No","Yes";
BA_DEF_ SG_  "VNSigAllNodes" ENUM  "No","Yes";
BA_DEF_ SG_  "GenSigDeltaValue" INT 0 0;
BA_DEF_ SG_  "GenSigSendType" ENUM  "not used","not used","not used","not used","not used","not used","not used","NoSigSendType","not used","not used","OnAnyChange","OnChangeIfActive","OnDelta";
BA_DEF_ SG_  "GenSigSendOnInit" ENUM  "Not Initialized","Application","Handler";
BA_DEF_ BO_  "AppGenMsgCycleTime" INT 0 0;
BA_DEF_ BO_  "TpTxIndex" INT 0 99;
BA_DEF_ BO_  "GenMsgILSupport" ENUM  "No","Yes";
BA_DEF_ BO_  "TpApplType" STRING ;
BA_DEF_ BO_  "Prio" INT 0 7;
BA_DEF_ BO_  "MessageSubnet" ENUM  "LS","HS","CE","PE","HV","FO","LE","HE2","PHS","PCE","DLCLS","DLCHS","DLCCE","DLCFO";
BA_DEF_ BO_  "GenMsgMandatoryToSupervision" ENUM  "No","Yes";
BA_DEF_ BO_  "DiagState" ENUM  "No","Yes";
BA_DEF_ BO_  "GenMsgStartDelayTime" INT 0 100000;
BA_DEF_ BO_  "GenMsgDelayTime" INT 0 100000;
BA_DEF_ BO_  "GenMsgCycleTime" INT 0 100000;
BA_DEF_ BO_  "GenMsgCycleTimeFast" INT 0 100000;
BA_DEF_ BO_  "GenMsgSendType" ENUM  "cyclicX","spontanX","cyclicIfActiveX","spontanWithDelay","cyclicAndSpontanX","cyclicAndSpontanWithDelay","spontanWithRepitition","cyclicIfActiveAndSpontanWD";
BA_DEF_ BO_  "DiagResponse" ENUM  "No","Yes";
BA_DEF_ BO_  "DiagRequest" ENUM  "No","Yes";
BA_DEF_ BO_  "NmMessage" ENUM  "No","Yes";
BA_DEF_REL_ BU_SG_REL_  "GenSigSuprvRespComment" STRING ;
BA_DEF_REL_ BU_SG_REL_  "GenSigVBitResp" ENUM  "No","Yes";
BA_DEF_REL_ BU_SG_REL_  "GenSigVBitRespComment" STRING ;
BA_DEF_REL_ BU_SG_REL_  "GenSigVDAFailComment" STRING ;
BA_DEF_REL_ BU_SG_REL_  "GenSigVDAFailResp" ENUM  "No","Yes";
BA_DEF_REL_ BU_SG_REL_  "GenSigRxStartValue" STRING ;
BA_DEF_REL_ BU_SG_REL_  "GenSigSuprvRespSubValue" INT 0 65535;
BA_DEF_REL_ BU_SG_REL_  "GenSigSuprvResp" ENUM  "None","Notify App","Substitute Default";
BA_DEF_REL_ BU_SG_REL_  "GenSigTimeoutMsg" HEX 0 268435455;
BA_DEF_REL_ BU_SG_REL_  "GenSigTimeoutTime" INT 0 15000;
BA_DEF_DEF_  "VNSigPrimaryTriggering" "No";
BA_DEF_DEF_  "VNSigRemoteDiagnostics" "No";
BA_DEF_DEF_  "VNSigInfotainment" "No";
BA_DEF_DEF_  "VNSigParkedVehicle" "No";
BA_DEF_DEF_  "VNSigIntermediate" "No";
BA_DEF_DEF_  "VNSigUnused_4" "No";
BA_DEF_DEF_  "SignalType" "";
BA_DEF_DEF_  "PacketOrder" 0;
BA_DEF_DEF_  "SignalLongName" "";
BA_DEF_DEF_  "GenSigStartValue" 0;
BA_DEF_DEF_  "VNSigDiagnostic" "No";
BA_DEF_DEF_  "VNSigAllNodes" "No";
BA_DEF_DEF_  "GenSigDeltaValue" 0;
BA_DEF_DEF_  "GenSigSendType" "NoSigSendType";
BA_DEF_DEF_  "GenSigSendOnInit" "Not Initialized";
BA_DEF_DEF_  "AppGenMsgCycleTime" 0;
BA_DEF_DEF_  "TpTxIndex" 0;
BA_DEF_DEF_  "GenMsgILSupport" "Yes";
BA_DEF_DEF_  "TpApplType" "";
BA_DEF_DEF_  "Prio" 4;
BA_DEF_DEF_  "MessageSubnet" "LS";
BA_DEF_DEF_  "GenMsgMandatoryToSupervision" "No";
BA_DEF_DEF_  "DiagState" "No";
BA_DEF_DEF_  "GenMsgStartDelayTime" 0;
BA_DEF_DEF_  "GenMsgDelayTime" 0;
BA_DEF_DEF_  "GenMsgCycleTime" 0;
BA_DEF_DEF_  "GenMsgCycleTimeFast" 0;
BA_DEF_DEF_  "GenMsgSendType" "spontanX";
BA_DEF_DEF_  "DiagResponse" "No";
BA_DEF_DEF_  "DiagRequest" "No";
BA_DEF_DEF_  "NmMessage" "No";
BA_DEF_DEF_REL_ "GenSigSuprvRespComment" "";
BA_DEF_DEF_REL_ "GenSigVBitResp" "No";
BA_DEF_DEF_REL_ "GenSigVBitRespComment" "";
BA_DEF_DEF_REL_ "GenSigVDAFailComment" "";
BA_DEF_DEF_REL_ "GenSigVDAFailResp" "No";
BA_DEF_DEF_REL_ "GenSigRxStartValue" "";
BA_DEF_DEF_REL_ "GenSigSuprvRespSubValue" 0;
BA_DEF_DEF_REL_ "GenSigSuprvResp" "None";
BA_DEF_DEF_REL_ "GenSigTimeoutMsg" 0;
BA_DEF_DEF_REL_ "GenSigTimeoutTime" 0;
BA_ "GenMsgDelayTime" BO_ 2150760448 10;
BA_ "Prio" BO_ 2155872256 3;
BA_ "GenMsgStartDelayTime" BO_ 2155872256 190;
BA_ "GenMsgCycleTime" BO_ 2155872256 250;
BA_ "GenMsgSendType" BO_ 2155872256 0;
BA_ "GenMsgDelayTime" BO_ 2156175360 50;
BA_ "GenMsgMandatoryToSupervision" BO_ 2149859328 1;
BA_ "GenMsgDelayTime" BO_ 2149859328 100;
BA_ "GenMsgCycleTime" BO_ 2149859328 5000;
BA_ "GenMsgSendType" BO_ 2149859328 0;
BA_ "GenMsgDelayTime" BO_ 2158854144 20;
BA_ "GenMsgStartDelayTime" BO_ 2154561536 170;
BA_ "GenMsgCycleTime" BO_ 2154561536 1000;
BA_ "GenMsgSendType" BO_ 2154561536 0;
BA_ "GenMsgStartDelayTime" BO_ 2149908480 130;
BA_ "GenMsgDelayTime" BO_ 2149908480 100;
BA_ "GenMsgCycleTime" BO_ 2149908480 1000;
BA_ "GenMsgSendType" BO_ 2149908480 0;
BA_ "GenMsgDelayTime" BO_ 2151268352 100;
BA_ "GenMsgDelayTime" BO_ 2156920832 100;
BA_ "GenMsgDelayTime" BO_ 2156937216 100;
BA_ "Prio" BO_ 2150604800 3;
BA_ "GenMsgDelayTime" BO_ 2150604800 100;
BA_ "Prio" BO_ 2150588416 3;
BA_ "GenMsgDelayTime" BO_ 2150588416 100;
BA_ "Prio" BO_ 2150596608 3;
BA_ "GenMsgDelayTime" BO_ 2150596608 100;
BA_ "GenMsgDelayTime" BO_ 2155036672 100;
BA_ "GenMsgCycleTime" BO_ 2155036672 500;
BA_ "GenMsgSendType" BO_ 2155036672 0;
BA_ "GenMsgMandatoryToSupervision" BO_ 2150424576 1;
BA_ "GenMsgStartDelayTime" BO_ 2150424576 150;
BA_ "GenMsgCycleTime" BO_ 2150424576 250;
BA_ "GenMsgSendType" BO_ 2150424576 0;
BA_ "GenMsgStartDelayTime" BO_ 2150416384 140;
BA_ "GenMsgCycleTime" BO_ 2150416384 250;
BA_ "GenMsgSendType" BO_ 2150416384 0;
BA_ "GenMsgMandatoryToSupervision" BO_ 2150408192 1;
BA_ "GenMsgStartDelayTime" BO_ 2150408192 180;
BA_ "GenMsgCycleTime" BO_ 2150408192 100;
BA_ "GenMsgSendType" BO_ 2150408192 0;
BA_ "GenMsgDelayTime" BO_ 2155954176 100;
BA_ "GenMsgCycleTime" BO_ 2155954176 2500;
BA_ "GenMsgSendType" BO_ 2155954176 0;
BA_ "Prio" BO_ 2153971712 3;
BA_ "GenMsgDelayTime" BO_ 2153971712 100;
BA_ "GenMsgMandatoryToSupervision" BO_ 2149875712 1;
BA_ "GenMsgStartDelayTime" BO_ 2149875712 120;
BA_ "GenMsgCycleTime" BO_ 2149875712 500;
BA_ "GenMsgSendType" BO_ 2149875712 0;
BA_ "GenMsgDelayTime" BO_ 2151186432 100;
BA_ "GenMsgMandatoryToSupervision" BO_ 2149629952 1;
BA_ "GenMsgDelayTime" BO_ 2149629952 30;
BA_ "GenMsgMandatoryToSupervision" BO_ 2149646336 1;
BA_ "GenMsgStartDelayTime" BO_ 2149646336 110;
BA_ "GenMsgCycleTime" BO_ 2149646336 100;
BA_ "GenMsgSendType" BO_ 2149646336 0;
BA_ "GenMsgMandatoryToSupervision" BO_ 2154053632 1;
BA_ "GenMsgDelayTime" BO_ 2154053632 100;
BA_ "Prio" BO_ 1623 0;
BA_ "DiagResponse" BO_ 1623 1;
BA_ "GenMsgDelayTime" BO_ 2154217472 100;
BA_ "GenMsgStartDelayTime" BO_ 2149851136 120;
BA_ "GenMsgDelayTime" BO_ 2149851136 30;
BA_ "GenMsgCycleTime" BO_ 2149851136 5000;
BA_ "GenMsgSendType" BO_ 2149851136 0;
BA_ "Prio" BO_ 2033 0;
BA_ "GenMsgILSupport" BO_ 587 0;
BA_ "Prio" BO_ 587 0;
BA_ "DiagRequest" BO_ 587 1;
BA_ "GenMsgDelayTime" BO_ 2151530496 100;
BA_ "Prio" BO_ 1625 0;
BA_ "DiagResponse" BO_ 1625 1;
BA_ "GenMsgILSupport" BO_ 1349 0;
BA_ "TpApplType" BO_ 1349 "DiagUUDTResponse";
BA_ "Prio" BO_ 1349 0;
BA_ "Prio" BO_ 1605 0;
BA_ "DiagResponse" BO_ 1605 1;
BA_ "Prio" BO_ 581 0;
BA_ "DiagRequest" BO_ 581 1;
BA_ "VNSigPrimaryTriggering" SG_ 2150760448 NotiFrntLfPasSeatOccSta 1;
BA_ "SignalType" SG_ 2150760448 NotiFrntLfPasSeatOccSta "ENM";
BA_ "SignalLongName" SG_ 2150760448 NotiFrntLfPasSeatOccSta "Notification Front Left Passenger Seat Occupancy Status";
BA_ "VNSigAllNodes" SG_ 2150760448 NotiFrntLfPasSeatOccSta 1;
BA_ "GenSigSendType" SG_ 2150760448 NotSndRwRtSeatStat 10;
BA_ "SignalType" SG_ 2150760448 NotSndRwRtSeatStat "ENM";
BA_ "SignalLongName" SG_ 2150760448 NotSndRwRtSeatStat "Notification Second Row Right Seatbelt Status";
BA_ "VNSigAllNodes" SG_ 2150760448 NotSndRwRtSeatStat 1;
BA_ "GenSigSendType" SG_ 2150760448 NotSndRwMdlSeatStat 10;
BA_ "SignalType" SG_ 2150760448 NotSndRwMdlSeatStat "ENM";
BA_ "SignalLongName" SG_ 2150760448 NotSndRwMdlSeatStat "Notification Second Row Middle Seatbelt Status";
BA_ "VNSigAllNodes" SG_ 2150760448 NotSndRwMdlSeatStat 1;
BA_ "GenSigSendType" SG_ 2150760448 NotSndRwLtSeatStat 10;
BA_ "SignalType" SG_ 2150760448 NotSndRwLtSeatStat "ENM";
BA_ "SignalLongName" SG_ 2150760448 NotSndRwLtSeatStat "Notification Second Row Left Seatbelt Status";
BA_ "VNSigAllNodes" SG_ 2150760448 NotSndRwLtSeatStat 1;
BA_ "GenSigSendType" SG_ 2150760448 NotPsSeatStat 10;
BA_ "SignalType" SG_ 2150760448 NotPsSeatStat "ENM";
BA_ "SignalLongName" SG_ 2150760448 NotPsSeatStat "Notification Passenger Seatbelt Status";
BA_ "VNSigAllNodes" SG_ 2150760448 NotPsSeatStat 1;
BA_ "GenSigSendType" SG_ 2150760448 NotDrvSeatStat 10;
BA_ "SignalType" SG_ 2150760448 NotDrvSeatStat "ENM";
BA_ "SignalLongName" SG_ 2150760448 NotDrvSeatStat "Notification Driver Seatbelt Status";
BA_ "VNSigAllNodes" SG_ 2150760448 NotDrvSeatStat 1;
BA_ "GenSigSendType" SG_ 2150760448 NotSecRowRtSeaOccStat 10;
BA_ "VNSigPrimaryTriggering" SG_ 2150760448 NotSecRowRtSeaOccStat 1;
BA_ "SignalType" SG_ 2150760448 NotSecRowRtSeaOccStat "ENM";
BA_ "SignalLongName" SG_ 2150760448 NotSecRowRtSeaOccStat "Notification Second Row Right Seat Occupancy Status";
BA_ "VNSigAllNodes" SG_ 2150760448 NotSecRowRtSeaOccStat 1;
BA_ "GenSigSendType" SG_ 2150760448 NotSecRowLeSeaOccStat 10;
BA_ "VNSigPrimaryTriggering" SG_ 2150760448 NotSecRowLeSeaOccStat 1;
BA_ "SignalType" SG_ 2150760448 NotSecRowLeSeaOccStat "ENM";
BA_ "SignalLongName" SG_ 2150760448 NotSecRowLeSeaOccStat "Notification Second Row Left Seat Occupancy Status";
BA_ "VNSigAllNodes" SG_ 2150760448 NotSecRowLeSeaOccStat 1;
BA_ "GenSigSendType" SG_ 2150760448 NotSecRowCtSeaOccStat 10;
BA_ "VNSigPrimaryTriggering" SG_ 2150760448 NotSecRowCtSeaOccStat 1;
BA_ "SignalType" SG_ 2150760448 NotSecRowCtSeaOccStat "ENM";
BA_ "SignalLongName" SG_ 2150760448 NotSecRowCtSeaOccStat "Notification Second Row Center Seat Occupancy Status";
BA_ "VNSigAllNodes" SG_ 2150760448 NotSecRowCtSeaOccStat 1;
BA_ "GenSigSendType" SG_ 2150760448 NotiFrntPasSeatOccSta 10;
BA_ "VNSigPrimaryTriggering" SG_ 2150760448 NotiFrntPasSeatOccSta 1;
BA_ "SignalType" SG_ 2150760448 NotiFrntPasSeatOccSta "ENM";
BA_ "SignalLongName" SG_ 2150760448 NotiFrntPasSeatOccSta "Notification Front Passenger Seat Occupancy Status";
BA_ "VNSigAllNodes" SG_ 2150760448 NotiFrntPasSeatOccSta 1;
BA_ "GenSigSendType" SG_ 2150760448 NotEventStat 10;
BA_ "VNSigPrimaryTriggering" SG_ 2150760448 NotEventStat 1;
BA_ "SignalType" SG_ 2150760448 NotEventStat "ENM";
BA_ "SignalLongName" SG_ 2150760448 NotEventStat "Notification Event Status";
BA_ "VNSigAllNodes" SG_ 2150760448 NotEventStat 1;
BA_ "GenSigDeltaValue" SG_ 2150760448 NotiEventCount 1;
BA_ "GenSigSendType" SG_ 2150760448 NotiEventCount 12;
BA_ "VNSigPrimaryTriggering" SG_ 2150760448 NotiEventCount 1;
BA_ "SignalType" SG_ 2150760448 NotiEventCount "UNM";
BA_ "SignalLongName" SG_ 2150760448 NotiEventCount "Notification Event Counter";
BA_ "VNSigAllNodes" SG_ 2150760448 NotiEventCount 1;
BA_ "GenSigSendType" SG_ 2150760448 NESSRoSevSt 10;
BA_ "VNSigPrimaryTriggering" SG_ 2150760448 NESSRoSevSt 1;
BA_ "SignalType" SG_ 2150760448 NESSRoSevSt "BLN";
BA_ "PacketOrder" SG_ 2150760448 NESSRoSevSt 7;
BA_ "SignalLongName" SG_ 2150760448 NESSRoSevSt "Notification Event Severity Status : Rollover Severity Achieved";
BA_ "VNSigAllNodes" SG_ 2150760448 NESSRoSevSt 1;
BA_ "GenSigSendType" SG_ 2150760448 NESSRiSiSevSt 10;
BA_ "VNSigPrimaryTriggering" SG_ 2150760448 NESSRiSiSevSt 1;
BA_ "SignalType" SG_ 2150760448 NESSRiSiSevSt "BLN";
BA_ "PacketOrder" SG_ 2150760448 NESSRiSiSevSt 6;
BA_ "SignalLongName" SG_ 2150760448 NESSRiSiSevSt "Notification Event Severity Status : Right Side Severity Achieved";
BA_ "VNSigAllNodes" SG_ 2150760448 NESSRiSiSevSt 1;
BA_ "GenSigSendType" SG_ 2150760448 NESSReImpSevSt 10;
BA_ "VNSigPrimaryTriggering" SG_ 2150760448 NESSReImpSevSt 1;
BA_ "SignalType" SG_ 2150760448 NESSReImpSevSt "BLN";
BA_ "PacketOrder" SG_ 2150760448 NESSReImpSevSt 5;
BA_ "SignalLongName" SG_ 2150760448 NESSReImpSevSt "Notification Event Severity Status : Rear Impact Severity Achieved";
BA_ "VNSigAllNodes" SG_ 2150760448 NESSReImpSevSt 1;
BA_ "GenSigSendType" SG_ 2150760448 NESSLeSiSevSt 10;
BA_ "VNSigPrimaryTriggering" SG_ 2150760448 NESSLeSiSevSt 1;
BA_ "SignalType" SG_ 2150760448 NESSLeSiSevSt "BLN";
BA_ "PacketOrder" SG_ 2150760448 NESSLeSiSevSt 4;
BA_ "SignalLongName" SG_ 2150760448 NESSLeSiSevSt "Notification Event Severity Status : Left Side Severity Achieved";
BA_ "VNSigAllNodes" SG_ 2150760448 NESSLeSiSevSt 1;
BA_ "GenSigSendType" SG_ 2150760448 NESSFrImpSt2SevSt 10;
BA_ "VNSigPrimaryTriggering" SG_ 2150760448 NESSFrImpSt2SevSt 1;
BA_ "SignalType" SG_ 2150760448 NESSFrImpSt2SevSt "BLN";
BA_ "PacketOrder" SG_ 2150760448 NESSFrImpSt2SevSt 3;
BA_ "SignalLongName" SG_ 2150760448 NESSFrImpSt2SevSt "Notification Event Severity Status : Frontal Impact Stage 2 Severity Achieved";
BA_ "VNSigAllNodes" SG_ 2150760448 NESSFrImpSt2SevSt 1;
BA_ "GenSigSendType" SG_ 2150760448 NESSFrImpSt1SevSt 10;
BA_ "VNSigPrimaryTriggering" SG_ 2150760448 NESSFrImpSt1SevSt 1;
BA_ "SignalType" SG_ 2150760448 NESSFrImpSt1SevSt "BLN";
BA_ "PacketOrder" SG_ 2150760448 NESSFrImpSt1SevSt 2;
BA_ "SignalLongName" SG_ 2150760448 NESSFrImpSt1SevSt "Notification Event Severity Status : Frontal Impact Stage 1 Severity Achieved";
BA_ "VNSigAllNodes" SG_ 2150760448 NESSFrImpSt1SevSt 1;
BA_ "GenSigSendType" SG_ 2150760448 NESSFrImpPreSevSt 10;
BA_ "VNSigPrimaryTriggering" SG_ 2150760448 NESSFrImpPreSevSt 1;
BA_ "SignalType" SG_ 2150760448 NESSFrImpPreSevSt "BLN";
BA_ "PacketOrder" SG_ 2150760448 NESSFrImpPreSevSt 1;
BA_ "SignalLongName" SG_ 2150760448 NESSFrImpPreSevSt "Notification Event Severity Status : Frontal Impact Pretensioner Severity Achieved";
BA_ "VNSigAllNodes" SG_ 2150760448 NESSFrImpPreSevSt 1;
BA_ "GenSigSendType" SG_ 2150760448 NEDLSRtSdArbgDld 10;
BA_ "VNSigPrimaryTriggering" SG_ 2150760448 NEDLSRtSdArbgDld 1;
BA_ "SignalType" SG_ 2150760448 NEDLSRtSdArbgDld "BLN";
BA_ "PacketOrder" SG_ 2150760448 NEDLSRtSdArbgDld 6;
BA_ "SignalLongName" SG_ 2150760448 NEDLSRtSdArbgDld "Notification Event Deployed Loop Status : Right Side Airbag Deployed";
BA_ "VNSigAllNodes" SG_ 2150760448 NEDLSRtSdArbgDld 1;
BA_ "GenSigSendType" SG_ 2150760448 NEDLSLtSdArbgDld 10;
BA_ "VNSigPrimaryTriggering" SG_ 2150760448 NEDLSLtSdArbgDld 1;
BA_ "SignalType" SG_ 2150760448 NEDLSLtSdArbgDld "BLN";
BA_ "PacketOrder" SG_ 2150760448 NEDLSLtSdArbgDld 5;
BA_ "SignalLongName" SG_ 2150760448 NEDLSLtSdArbgDld "Notification Event Deployed Loop Status : Left Side Airbag Deployed";
BA_ "VNSigAllNodes" SG_ 2150760448 NEDLSLtSdArbgDld 1;
BA_ "GenSigSendType" SG_ 2150760448 NEDLSSdCrtnArbgDpld 10;
BA_ "VNSigPrimaryTriggering" SG_ 2150760448 NEDLSSdCrtnArbgDpld 1;
BA_ "SignalType" SG_ 2150760448 NEDLSSdCrtnArbgDpld "BLN";
BA_ "PacketOrder" SG_ 2150760448 NEDLSSdCrtnArbgDpld 7;
BA_ "SignalLongName" SG_ 2150760448 NEDLSSdCrtnArbgDpld "Notification Event Deployed Loop Status : Side Curtain Airbag Deployed";
BA_ "VNSigAllNodes" SG_ 2150760448 NEDLSSdCrtnArbgDpld 1;
BA_ "GenSigSendType" SG_ 2150760448 NEDLSPaFrSt2De 10;
BA_ "VNSigPrimaryTriggering" SG_ 2150760448 NEDLSPaFrSt2De 1;
BA_ "SignalType" SG_ 2150760448 NEDLSPaFrSt2De "BLN";
BA_ "PacketOrder" SG_ 2150760448 NEDLSPaFrSt2De 4;
BA_ "SignalLongName" SG_ 2150760448 NEDLSPaFrSt2De "Notification Event Deployed Loop Status : Passenger Front Stage 2 Deployed";
BA_ "VNSigAllNodes" SG_ 2150760448 NEDLSPaFrSt2De 1;
BA_ "GenSigSendType" SG_ 2150760448 NEDLSPaFrSt1De 10;
BA_ "VNSigPrimaryTriggering" SG_ 2150760448 NEDLSPaFrSt1De 1;
BA_ "SignalType" SG_ 2150760448 NEDLSPaFrSt1De "BLN";
BA_ "PacketOrder" SG_ 2150760448 NEDLSPaFrSt1De 3;
BA_ "SignalLongName" SG_ 2150760448 NEDLSPaFrSt1De "Notification Event Deployed Loop Status : Passenger Front Stage 1 Deployed";
BA_ "VNSigAllNodes" SG_ 2150760448 NEDLSPaFrSt1De 1;
BA_ "GenSigSendType" SG_ 2150760448 NEDLSDrFrSt2De 10;
BA_ "VNSigPrimaryTriggering" SG_ 2150760448 NEDLSDrFrSt2De 1;
BA_ "SignalType" SG_ 2150760448 NEDLSDrFrSt2De "BLN";
BA_ "PacketOrder" SG_ 2150760448 NEDLSDrFrSt2De 2;
BA_ "SignalLongName" SG_ 2150760448 NEDLSDrFrSt2De "Notification Event Deployed Loop Status : Driver Front Stage 2 Deployed";
BA_ "VNSigAllNodes" SG_ 2150760448 NEDLSDrFrSt2De 1;
BA_ "GenSigSendType" SG_ 2150760448 NEDLSDrFrSt1De 10;
BA_ "VNSigPrimaryTriggering" SG_ 2150760448 NEDLSDrFrSt1De 1;
BA_ "SignalType" SG_ 2150760448 NEDLSDrFrSt1De "BLN";
BA_ "PacketOrder" SG_ 2150760448 NEDLSDrFrSt1De 1;
BA_ "SignalLongName" SG_ 2150760448 NEDLSDrFrSt1De "Notification Event Deployed Loop Status : Driver Front Stage 1 Deployed";
BA_ "VNSigAllNodes" SG_ 2150760448 NEDLSDrFrSt1De 1;
BA_ "GenSigSendType" SG_ 2150760448 SIRDpl 10;
BA_ "GenSigSendOnInit" SG_ 2150760448 SIRDpl 2;
BA_ "VNSigPrimaryTriggering" SG_ 2150760448 SIRDpl 1;
BA_ "SignalType" SG_ 2150760448 SIRDpl "BLN";
BA_ "SignalLongName" SG_ 2150760448 SIRDpl "Airbag Deployed";
BA_ "VNSigAllNodes" SG_ 2150760448 SIRDpl 1;
BA_ "SignalType" SG_ 2155872256 FuelFltChgNwIO "BLN";
BA_ "SignalLongName" SG_ 2155872256 FuelFltChgNwIO "Fuel Filter Change Now Indication On";
BA_ "VNSigAllNodes" SG_ 2155872256 FuelFltChgNwIO 1;
BA_ "GenSigSendOnInit" SG_ 2155872256 FlLvlPctV 1;
BA_ "SignalType" SG_ 2155872256 FlLvlPctV "ENM";
BA_ "SignalLongName" SG_ 2155872256 FlLvlPctV "Fuel Level Percent Validity";
BA_ "VNSigAllNodes" SG_ 2155872256 FlLvlPctV 1;
BA_ "GenSigDeltaValue" SG_ 2155872256 FlLvlPct 2;
BA_ "GenSigSendOnInit" SG_ 2155872256 FlLvlPct 1;
BA_ "SignalType" SG_ 2155872256 FlLvlPct "UNM";
BA_ "SignalLongName" SG_ 2155872256 FlLvlPct "Fuel Level Percent";
BA_ "VNSigAllNodes" SG_ 2155872256 FlLvlPct 1;
BA_ "SignalType" SG_ 2155872256 FlInjRlCtRstOcc "BLN";
BA_ "SignalLongName" SG_ 2155872256 FlInjRlCtRstOcc "Fuel Injected Rolling Count Reset Occurred";
BA_ "VNSigAllNodes" SG_ 2155872256 FlInjRlCtRstOcc 1;
BA_ "SignalType" SG_ 2155872256 FlInjRlCt "UNM";
BA_ "SignalLongName" SG_ 2155872256 FlInjRlCt "Fuel Injected Rolling Count";
BA_ "VNSigAllNodes" SG_ 2155872256 FlInjRlCt 1;
BA_ "GenSigSendType" SG_ 2156175360 NtVsnSysEnbld 10;
BA_ "SignalType" SG_ 2156175360 NtVsnSysEnbld "BLN";
BA_ "SignalLongName" SG_ 2156175360 NtVsnSysEnbld "Night Vision System Enabled";
BA_ "VNSigAllNodes" SG_ 2156175360 NtVsnSysEnbld 1;
BA_ "GenSigSendType" SG_ 2156175360 DispMeasSysExt 10;
BA_ "GenSigSendOnInit" SG_ 2156175360 DispMeasSysExt 1;
BA_ "VNSigInfotainment" SG_ 2156175360 DispMeasSysExt 1;
BA_ "SignalType" SG_ 2156175360 DispMeasSysExt "ENM";
BA_ "SignalLongName" SG_ 2156175360 DispMeasSysExt "Display Measurement System Extended";
BA_ "VNSigAllNodes" SG_ 2156175360 DispMeasSysExt 1;
BA_ "GenSigSendType" SG_ 2156175360 DispMeasSys 10;
BA_ "GenSigSendOnInit" SG_ 2156175360 DispMeasSys 1;
BA_ "SignalType" SG_ 2156175360 DispMeasSys "ENM";
BA_ "SignalLongName" SG_ 2156175360 DispMeasSys "Display Measurement System";
BA_ "VNSigAllNodes" SG_ 2156175360 DispMeasSys 1;
BA_ "GenSigSendType" SG_ 2149859328 SysBkUpPwrMdV 10;
BA_ "VNSigInfotainment" SG_ 2149859328 SysBkUpPwrMdV 1;
BA_ "VNSigParkedVehicle" SG_ 2149859328 SysBkUpPwrMdV 1;
BA_ "VNSigIntermediate" SG_ 2149859328 SysBkUpPwrMdV 1;
BA_ "SignalType" SG_ 2149859328 SysBkUpPwrMdV "ENM";
BA_ "SignalLongName" SG_ 2149859328 SysBkUpPwrMdV "System Backup Power Mode Validity";
BA_ "VNSigAllNodes" SG_ 2149859328 SysBkUpPwrMdV 1;
BA_ "GenSigSendType" SG_ 2149859328 SysBkupPwrMdEn 10;
BA_ "GenSigSendOnInit" SG_ 2149859328 SysBkupPwrMdEn 1;
BA_ "VNSigInfotainment" SG_ 2149859328 SysBkupPwrMdEn 1;
BA_ "VNSigParkedVehicle" SG_ 2149859328 SysBkupPwrMdEn 1;
BA_ "VNSigIntermediate" SG_ 2149859328 SysBkupPwrMdEn 1;
BA_ "SignalType" SG_ 2149859328 SysBkupPwrMdEn "BLN";
BA_ "SignalLongName" SG_ 2149859328 SysBkupPwrMdEn "System Backup Power Mode Enabled";
BA_ "VNSigAllNodes" SG_ 2149859328 SysBkupPwrMdEn 1;
BA_ "GenSigSendType" SG_ 2149859328 SysBkUpPwrMd 10;
BA_ "GenSigSendOnInit" SG_ 2149859328 SysBkUpPwrMd 1;
BA_ "VNSigInfotainment" SG_ 2149859328 SysBkUpPwrMd 1;
BA_ "VNSigParkedVehicle" SG_ 2149859328 SysBkUpPwrMd 1;
BA_ "VNSigIntermediate" SG_ 2149859328 SysBkUpPwrMd 1;
BA_ "SignalType" SG_ 2149859328 SysBkUpPwrMd "ENM";
BA_ "SignalLongName" SG_ 2149859328 SysBkUpPwrMd "System Backup Power Mode";
BA_ "VNSigAllNodes" SG_ 2149859328 SysBkUpPwrMd 1;
BA_ "GenSigDeltaValue" SG_ 2158854144 ODIAI_DaTy 1;
BA_ "GenSigSendType" SG_ 2158854144 ODIAI_DaTy 10;
BA_ "VNSigInfotainment" SG_ 2158854144 ODIAI_DaTy 1;
BA_ "SignalType" SG_ 2158854144 ODIAI_DaTy "ENM";
BA_ "PacketOrder" SG_ 2158854144 ODIAI_DaTy 1;
BA_ "SignalLongName" SG_ 2158854144 ODIAI_DaTy "Open Display Interface Action IPC : DataType";
BA_ "VNSigAllNodes" SG_ 2158854144 ODIAI_DaTy 1;
BA_ "GenSigDeltaValue" SG_ 2158854144 ODIAI_FUCID 1;
BA_ "GenSigSendType" SG_ 2158854144 ODIAI_FUCID 12;
BA_ "VNSigInfotainment" SG_ 2158854144 ODIAI_FUCID 1;
BA_ "SignalType" SG_ 2158854144 ODIAI_FUCID "UNM";
BA_ "PacketOrder" SG_ 2158854144 ODIAI_FUCID 2;
BA_ "SignalLongName" SG_ 2158854144 ODIAI_FUCID "Open Display Interface Action IPC : FU Class ID";
BA_ "VNSigAllNodes" SG_ 2158854144 ODIAI_FUCID 1;
BA_ "GenSigSendType" SG_ 2158854144 ODIAI_DspMID 10;
BA_ "VNSigInfotainment" SG_ 2158854144 ODIAI_DspMID 1;
BA_ "SignalType" SG_ 2158854144 ODIAI_DspMID "ENM";
BA_ "PacketOrder" SG_ 2158854144 ODIAI_DspMID 4;
BA_ "SignalLongName" SG_ 2158854144 ODIAI_DspMID "Open Display Interface Action IPC : Display Mask ID";
BA_ "VNSigAllNodes" SG_ 2158854144 ODIAI_DspMID 1;
BA_ "GenSigDeltaValue" SG_ 2158854144 ODIAI_ActnVal 1;
BA_ "GenSigSendType" SG_ 2158854144 ODIAI_ActnVal 12;
BA_ "VNSigInfotainment" SG_ 2158854144 ODIAI_ActnVal 1;
BA_ "SignalType" SG_ 2158854144 ODIAI_ActnVal "UNM";
BA_ "PacketOrder" SG_ 2158854144 ODIAI_ActnVal 5;
BA_ "SignalLongName" SG_ 2158854144 ODIAI_ActnVal "Open Display Interface Action IPC : Action Value";
BA_ "VNSigAllNodes" SG_ 2158854144 ODIAI_ActnVal 1;
BA_ "GenSigDeltaValue" SG_ 2158854144 ODIAI_ActnID 1;
BA_ "GenSigSendType" SG_ 2158854144 ODIAI_ActnID 12;
BA_ "VNSigInfotainment" SG_ 2158854144 ODIAI_ActnID 1;
BA_ "SignalType" SG_ 2158854144 ODIAI_ActnID "UNM";
BA_ "PacketOrder" SG_ 2158854144 ODIAI_ActnID 3;
BA_ "SignalLongName" SG_ 2158854144 ODIAI_ActnID "Open Display Interface Action IPC : Action ID";
BA_ "VNSigAllNodes" SG_ 2158854144 ODIAI_ActnID 1;
BA_ "SignalType" SG_ 2154561536 VehOdoV "ENM";
BA_ "SignalLongName" SG_ 2154561536 VehOdoV "Vehicle Odometer Validity";
BA_ "VNSigAllNodes" SG_ 2154561536 VehOdoV 1;
BA_ "SignalType" SG_ 2154561536 VehOdo "UNM";
BA_ "SignalLongName" SG_ 2154561536 VehOdo "Vehicle Odometer";
BA_ "VNSigAllNodes" SG_ 2154561536 VehOdo 1;
BA_ "GenSigDeltaValue" SG_ 2149908480 BrkPdlPos 1;
BA_ "GenSigSendType" SG_ 2149908480 BrkPdlPos 12;
BA_ "GenSigSendOnInit" SG_ 2149908480 BrkPdlPos 1;
BA_ "SignalType" SG_ 2149908480 BrkPdlPos "UNM";
BA_ "SignalLongName" SG_ 2149908480 BrkPdlPos "Brake Pedal Position";
BA_ "VNSigAllNodes" SG_ 2149908480 BrkPdlPos 1;
BA_ "GenSigSendType" SG_ 2149908480 BrkPedTrvlAchvd 10;
BA_ "SignalType" SG_ 2149908480 BrkPedTrvlAchvd "BLN";
BA_ "PacketOrder" SG_ 2149908480 BrkPedTrvlAchvd 1;
BA_ "SignalLongName" SG_ 2149908480 BrkPedTrvlAchvd "Brake Pedal Initial Travel Achieved Status : Brake Pedal Initial Travel Achieved";
BA_ "VNSigAllNodes" SG_ 2149908480 BrkPedTrvlAchvd 1;
BA_ "GenSigSendType" SG_ 2149908480 BrkPedTrvlAchvdV 10;
BA_ "SignalType" SG_ 2149908480 BrkPedTrvlAchvdV "ENM";
BA_ "PacketOrder" SG_ 2149908480 BrkPedTrvlAchvdV 2;
BA_ "SignalLongName" SG_ 2149908480 BrkPedTrvlAchvdV "Brake Pedal Initial Travel Achieved Status : Brake Pedal Initial Travel Achieved Validity";
BA_ "VNSigAllNodes" SG_ 2149908480 BrkPedTrvlAchvdV 1;
BA_ "GenSigSendType" SG_ 2149908480 BrkPdlModTrvlV 10;
BA_ "SignalType" SG_ 2149908480 BrkPdlModTrvlV "ENM";
BA_ "SignalLongName" SG_ 2149908480 BrkPdlModTrvlV "Brake Pedal Moderate Travel Achieved Validity";
BA_ "VNSigAllNodes" SG_ 2149908480 BrkPdlModTrvlV 1;
BA_ "GenSigSendType" SG_ 2149908480 BrkPdlModTrvl 10;
BA_ "SignalType" SG_ 2149908480 BrkPdlModTrvl "BLN";
BA_ "SignalLongName" SG_ 2149908480 BrkPdlModTrvl "Brake Pedal Moderate Travel Achieved";
BA_ "VNSigAllNodes" SG_ 2149908480 BrkPdlModTrvl 1;
BA_ "GenSigSendType" SG_ 2151268352 ClmnLckTT 10;
BA_ "GenSigSendOnInit" SG_ 2151268352 ClmnLckTT 1;
BA_ "SignalType" SG_ 2151268352 ClmnLckTT "ENM";
BA_ "SignalLongName" SG_ 2151268352 ClmnLckTT "Column Lock Telltale";
BA_ "VNSigAllNodes" SG_ 2151268352 ClmnLckTT 1;
BA_ "SignalType" SG_ 2156920832 WiFiPssPhrsDgts1to8 "ASC";
BA_ "SignalLongName" SG_ 2156920832 WiFiPssPhrsDgts1to8 "WiFi Pass Phrase Digits 1 to 8";
BA_ "VNSigAllNodes" SG_ 2156920832 WiFiPssPhrsDgts1to8 1;
BA_ "SignalType" SG_ 2156937216 WiFiPssPhrsDgts17to24 "ASC";
BA_ "SignalLongName" SG_ 2156937216 WiFiPssPhrsDgts17to24 "WiFi Pass Phrase Digits 17 to 24";
BA_ "VNSigAllNodes" SG_ 2156937216 WiFiPssPhrsDgts17to24 1;
BA_ "GenSigSendType" SG_ 2150604800 RRDoorAjarSwAct 10;
BA_ "GenSigSendOnInit" SG_ 2150604800 RRDoorAjarSwAct 2;
BA_ "VNSigInfotainment" SG_ 2150604800 RRDoorAjarSwAct 1;
BA_ "SignalType" SG_ 2150604800 RRDoorAjarSwAct "BLN";
BA_ "SignalLongName" SG_ 2150604800 RRDoorAjarSwAct "Rear Right Door Ajar Switch Active";
BA_ "VNSigAllNodes" SG_ 2150604800 RRDoorAjarSwAct 1;
BA_ "GenSigSendType" SG_ 2150588416 PDAjrSwAtv 10;
BA_ "GenSigSendOnInit" SG_ 2150588416 PDAjrSwAtv 2;
BA_ "VNSigInfotainment" SG_ 2150588416 PDAjrSwAtv 1;
BA_ "SignalType" SG_ 2150588416 PDAjrSwAtv "BLN";
BA_ "SignalLongName" SG_ 2150588416 PDAjrSwAtv "Passenger Door Ajar Switch Active";
BA_ "VNSigAllNodes" SG_ 2150588416 PDAjrSwAtv 1;
BA_ "GenSigSendType" SG_ 2150596608 RLDoorAjarSwAct 10;
BA_ "GenSigSendOnInit" SG_ 2150596608 RLDoorAjarSwAct 2;
BA_ "VNSigInfotainment" SG_ 2150596608 RLDoorAjarSwAct 1;
BA_ "SignalType" SG_ 2150596608 RLDoorAjarSwAct "BLN";
BA_ "SignalLongName" SG_ 2150596608 RLDoorAjarSwAct "Rear Left Door Ajar Switch Active";
BA_ "VNSigAllNodes" SG_ 2150596608 RLDoorAjarSwAct 1;
BA_ "GenSigDeltaValue" SG_ 2155036672 ClmtCtrlTrgtTemp 1;
BA_ "GenSigSendType" SG_ 2155036672 ClmtCtrlTrgtTemp 12;
BA_ "SignalType" SG_ 2155036672 ClmtCtrlTrgtTemp "UNM";
BA_ "SignalLongName" SG_ 2155036672 ClmtCtrlTrgtTemp "Climate Control Target Temperature";
BA_ "VNSigAllNodes" SG_ 2155036672 ClmtCtrlTrgtTemp 1;
BA_ "GenSigSendType" SG_ 2155036672 ACCompModReq 10;
BA_ "GenSigSendOnInit" SG_ 2155036672 ACCompModReq 2;
BA_ "SignalType" SG_ 2155036672 ACCompModReq "ENM";
BA_ "SignalLongName" SG_ 2155036672 ACCompModReq "Air Conditioning Compressor Mode Request";
BA_ "VNSigAllNodes" SG_ 2155036672 ACCompModReq 1;
BA_ "GenSigSendType" SG_ 2155036672 ACCompNormLdV 10;
BA_ "GenSigSendOnInit" SG_ 2155036672 ACCompNormLdV 1;
BA_ "SignalType" SG_ 2155036672 ACCompNormLdV "ENM";
BA_ "SignalLongName" SG_ 2155036672 ACCompNormLdV "Air Conditioning Compressor Normalized Load Validity";
BA_ "VNSigAllNodes" SG_ 2155036672 ACCompNormLdV 1;
BA_ "GenSigDeltaValue" SG_ 2155036672 ACCompNormLd 1;
BA_ "GenSigSendType" SG_ 2155036672 ACCompNormLd 12;
BA_ "GenSigSendOnInit" SG_ 2155036672 ACCompNormLd 1;
BA_ "SignalType" SG_ 2155036672 ACCompNormLd "UNM";
BA_ "SignalLongName" SG_ 2155036672 ACCompNormLd "Air Conditioning Compressor Normalized Load";
BA_ "VNSigAllNodes" SG_ 2155036672 ACCompNormLd 1;
BA_ "GenSigSendType" SG_ 2155036672 ACCmEngRunReq 10;
BA_ "SignalType" SG_ 2155036672 ACCmEngRunReq "ENM";
BA_ "SignalLongName" SG_ 2155036672 ACCmEngRunReq "Air Conditioning Compressor Engine Run Request";
BA_ "VNSigAllNodes" SG_ 2155036672 ACCmEngRunReq 1;
BA_ "GenSigSendType" SG_ 2155036672 ACCmpsrFldOn 10;
BA_ "SignalType" SG_ 2155036672 ACCmpsrFldOn "BLN";
BA_ "SignalLongName" SG_ 2155036672 ACCmpsrFldOn "Air Conditioning Compressor Failed On";
BA_ "VNSigAllNodes" SG_ 2155036672 ACCmpsrFldOn 1;
BA_ "SignalType" SG_ 2150424576 EngTrqDrRqdExtRngV "ENM";
BA_ "SignalLongName" SG_ 2150424576 EngTrqDrRqdExtRngV "Engine Torque Driver Requested Extended Range Validity";
BA_ "VNSigAllNodes" SG_ 2150424576 EngTrqDrRqdExtRngV 1;
BA_ "SignalType" SG_ 2150424576 EngTrqDrRqdExtRng "UNM";
BA_ "SignalLongName" SG_ 2150424576 EngTrqDrRqdExtRng "Engine Torque Driver Requested Extended Range";
BA_ "GenSigStartValue" SG_ 2150424576 EngTrqDrRqdExtRng 1696;
BA_ "VNSigAllNodes" SG_ 2150424576 EngTrqDrRqdExtRng 1;
BA_ "SignalType" SG_ 2150424576 EngAirIntBstPrV "ENM";
BA_ "SignalLongName" SG_ 2150424576 EngAirIntBstPrV "Engine Intake Air Boost Pressure Validity";
BA_ "VNSigAllNodes" SG_ 2150424576 EngAirIntBstPrV 1;
BA_ "SignalType" SG_ 2150424576 TrnsRngInhbtStat "ENM";
BA_ "SignalLongName" SG_ 2150424576 TrnsRngInhbtStat "Transmission Range Inhibit Status";
BA_ "VNSigAllNodes" SG_ 2150424576 TrnsRngInhbtStat 1;
BA_ "SignalType" SG_ 2150424576 DrvtShftCntrlTrgtGear "ENM";
BA_ "SignalLongName" SG_ 2150424576 DrvtShftCntrlTrgtGear "Driver Shift Control Target Gear";
BA_ "VNSigAllNodes" SG_ 2150424576 DrvtShftCntrlTrgtGear 1;
BA_ "SignalType" SG_ 2150424576 EngAirIntBstPr "SNM";
BA_ "SignalLongName" SG_ 2150424576 EngAirIntBstPr "Engine Intake Air Boost Pressure";
BA_ "VNSigAllNodes" SG_ 2150424576 EngAirIntBstPr 1;
BA_ "SignalType" SG_ 2150424576 ACCmpNrmLdGrdAld "UNM";
BA_ "SignalLongName" SG_ 2150424576 ACCmpNrmLdGrdAld "Air Conditioning Compressor Normalized Load Gradient Allowed";
BA_ "VNSigAllNodes" SG_ 2150424576 ACCmpNrmLdGrdAld 1;
BA_ "SignalType" SG_ 2150424576 TrnsEngdStateV "ENM";
BA_ "SignalLongName" SG_ 2150424576 TrnsEngdStateV "Transmission Engaged State Validity";
BA_ "VNSigAllNodes" SG_ 2150424576 TrnsEngdStateV 1;
BA_ "SignalType" SG_ 2150424576 ACRfHiSdFldPrsV "ENM";
BA_ "SignalLongName" SG_ 2150424576 ACRfHiSdFldPrsV "Air Conditioning Refrigerant High Side Fluid Pressure Validity";
BA_ "VNSigAllNodes" SG_ 2150424576 ACRfHiSdFldPrsV 1;
BA_ "SignalType" SG_ 2150424576 ACRfHiSdFldPrs "UNM";
BA_ "SignalLongName" SG_ 2150424576 ACRfHiSdFldPrs "Air Conditioning Refrigerant High Side Fluid Pressure";
BA_ "VNSigAllNodes" SG_ 2150424576 ACRfHiSdFldPrs 1;
BA_ "SignalType" SG_ 2150424576 ACCompCmnd "ENM";
BA_ "SignalLongName" SG_ 2150424576 ACCompCmnd "Air Conditioning Compressor Command";
BA_ "VNSigAllNodes" SG_ 2150424576 ACCompCmnd 1;
BA_ "SignalType" SG_ 2150424576 TrnsEngdState "ENM";
BA_ "SignalLongName" SG_ 2150424576 TrnsEngdState "Transmission Engaged State";
BA_ "VNSigAllNodes" SG_ 2150424576 TrnsEngdState 1;
BA_ "SignalType" SG_ 2150416384 PTWrmgWtToShftIO "BLN";
BA_ "SignalLongName" SG_ 2150416384 PTWrmgWtToShftIO "Powertrain Warming Wait To Shift Indication On";
BA_ "VNSigAllNodes" SG_ 2150416384 PTWrmgWtToShftIO 1;
BA_ "SignalType" SG_ 2150416384 EngTrqActExtRngV "ENM";
BA_ "SignalLongName" SG_ 2150416384 EngTrqActExtRngV "Engine Torque Actual Extended Range Validity";
BA_ "VNSigAllNodes" SG_ 2150416384 EngTrqActExtRngV 1;
BA_ "SignalType" SG_ 2150416384 VehTopSpdLmtMdAct "BLN";
BA_ "SignalLongName" SG_ 2150416384 VehTopSpdLmtMdAct "Vehicle Top Speed Limit Mode Active";
BA_ "VNSigAllNodes" SG_ 2150416384 VehTopSpdLmtMdAct 1;
BA_ "SignalType" SG_ 2150416384 EngTrqActExtRng "UNM";
BA_ "SignalLongName" SG_ 2150416384 EngTrqActExtRng "Engine Torque Actual Extended Range";
BA_ "GenSigStartValue" SG_ 2150416384 EngTrqActExtRng 1696;
BA_ "VNSigAllNodes" SG_ 2150416384 EngTrqActExtRng 1;
BA_ "SignalType" SG_ 2150416384 EngRunAtv "BLN";
BA_ "SignalLongName" SG_ 2150416384 EngRunAtv "Engine Run Active";
BA_ "VNSigAllNodes" SG_ 2150416384 EngRunAtv 1;
BA_ "SignalType" SG_ 2150416384 EngIdlAtv "BLN";
BA_ "SignalLongName" SG_ 2150416384 EngIdlAtv "Engine Idle Active";
BA_ "VNSigAllNodes" SG_ 2150416384 EngIdlAtv 1;
BA_ "SignalType" SG_ 2150416384 EngSpdStat "ENM";
BA_ "SignalLongName" SG_ 2150416384 EngSpdStat "Engine Speed Status";
BA_ "VNSigAllNodes" SG_ 2150416384 EngSpdStat 1;
BA_ "SignalType" SG_ 2150416384 VaccBoostFailure "BLN";
BA_ "SignalLongName" SG_ 2150416384 VaccBoostFailure "Vaccum Boost Failure";
BA_ "VNSigAllNodes" SG_ 2150416384 VaccBoostFailure 1;
BA_ "SignalType" SG_ 2150416384 RmVhStrtEngRng "BLN";
BA_ "SignalLongName" SG_ 2150416384 RmVhStrtEngRng "Remote Vehicle Start Engine Running";
BA_ "VNSigAllNodes" SG_ 2150416384 RmVhStrtEngRng 1;
BA_ "SignalType" SG_ 2150416384 EngCoolFanSpd "UNM";
BA_ "SignalLongName" SG_ 2150416384 EngCoolFanSpd "Engine Cooling Fan Speed";
BA_ "VNSigAllNodes" SG_ 2150416384 EngCoolFanSpd 1;
BA_ "SignalType" SG_ 2150416384 TrnsVDA "ENM";
BA_ "SignalLongName" SG_ 2150416384 TrnsVDA "Transmission Virtual Device Availability";
BA_ "GenSigStartValue" SG_ 2150416384 TrnsVDA 1;
BA_ "VNSigAllNodes" SG_ 2150416384 TrnsVDA 1;
BA_ "SignalType" SG_ 2150416384 GenFld "BLN";
BA_ "SignalLongName" SG_ 2150416384 GenFld "Generator Failed";
BA_ "VNSigAllNodes" SG_ 2150416384 GenFld 1;
BA_ "SignalType" SG_ 2150416384 EngSpdLmtnMdAct "BLN";
BA_ "SignalLongName" SG_ 2150416384 EngSpdLmtnMdAct "Engine Speed Limitation Mode Active";
BA_ "VNSigAllNodes" SG_ 2150416384 EngSpdLmtnMdAct 1;
BA_ "SignalType" SG_ 2150416384 EngNEmsnsRelMalfAct "BLN";
BA_ "SignalLongName" SG_ 2150416384 EngNEmsnsRelMalfAct "Engine Non Emissions Related Malfunction Active";
BA_ "VNSigAllNodes" SG_ 2150416384 EngNEmsnsRelMalfAct 1;
BA_ "SignalType" SG_ 2150416384 EngCstFlCutAct "BLN";
BA_ "SignalLongName" SG_ 2150416384 EngCstFlCutAct "Engine Coast Fuel Cut Off Active";
BA_ "VNSigAllNodes" SG_ 2150416384 EngCstFlCutAct 1;
BA_ "SignalType" SG_ 2150416384 EngCylDeactMd "ENM";
BA_ "SignalLongName" SG_ 2150416384 EngCylDeactMd "Engine Cylinder Deactivation Mode";
BA_ "VNSigAllNodes" SG_ 2150416384 EngCylDeactMd 1;
BA_ "SignalType" SG_ 2150416384 EngBstPrsIndV "ENM";
BA_ "SignalLongName" SG_ 2150416384 EngBstPrsIndV "Engine Boost Pressure Indication Validity";
BA_ "VNSigAllNodes" SG_ 2150416384 EngBstPrsIndV 1;
BA_ "SignalType" SG_ 2150416384 EngBstPrsInd "UNM";
BA_ "SignalLongName" SG_ 2150416384 EngBstPrsInd "Engine Boost Pressure Indication";
BA_ "VNSigAllNodes" SG_ 2150416384 EngBstPrsInd 1;
BA_ "SignalType" SG_ 2150416384 TransEstGear "ENM";
BA_ "SignalLongName" SG_ 2150416384 TransEstGear "Transmission Estimated Gear";
BA_ "GenSigStartValue" SG_ 2150416384 TransEstGear 15;
BA_ "VNSigAllNodes" SG_ 2150416384 TransEstGear 1;
BA_ "SignalType" SG_ 2150416384 TransEstGearV "ENM";
BA_ "SignalLongName" SG_ 2150416384 TransEstGearV "Transmission Estimated Gear Validity";
BA_ "VNSigAllNodes" SG_ 2150416384 TransEstGearV 1;
BA_ "SignalType" SG_ 2150416384 EngVDA "ENM";
BA_ "SignalLongName" SG_ 2150416384 EngVDA "Engine Virtual Device Availability";
BA_ "GenSigStartValue" SG_ 2150416384 EngVDA 1;
BA_ "VNSigAllNodes" SG_ 2150416384 EngVDA 1;
BA_ "SignalType" SG_ 2150416384 TrnCrpMdAtv "BLN";
BA_ "SignalLongName" SG_ 2150416384 TrnCrpMdAtv "Transmission Creep Mode Active";
BA_ "VNSigAllNodes" SG_ 2150416384 TrnCrpMdAtv 1;
BA_ "SignalType" SG_ 2150416384 VehTopSpdLmtArbVal "UNM";
BA_ "SignalLongName" SG_ 2150416384 VehTopSpdLmtArbVal "Vehicle Top Speed Limit Arbitrated Value";
BA_ "VNSigAllNodes" SG_ 2150416384 VehTopSpdLmtArbVal 1;
BA_ "SignalType" SG_ 2150408192 ElcRngSelDrvAct "BLN";
BA_ "SignalLongName" SG_ 2150408192 ElcRngSelDrvAct "Electronic Range Selection In Drive Active";
BA_ "VNSigAllNodes" SG_ 2150408192 ElcRngSelDrvAct 1;
BA_ "SignalType" SG_ 2150408192 TmpDrvrShftCtlAct "BLN";
BA_ "SignalLongName" SG_ 2150408192 TmpDrvrShftCtlAct "Temporary Driver Shift Control Active";
BA_ "VNSigAllNodes" SG_ 2150408192 TmpDrvrShftCtlAct 1;
BA_ "SignalType" SG_ 2150408192 EngRunng "BLN";
BA_ "SignalLongName" SG_ 2150408192 EngRunng "Engine Running";
BA_ "VNSigAllNodes" SG_ 2150408192 EngRunng 1;
BA_ "SignalType" SG_ 2150408192 Eng12vStrtrMtrCmmdOn "BLN";
BA_ "SignalLongName" SG_ 2150408192 Eng12vStrtrMtrCmmdOn "Engine 12 Volt Starter Motor Commanded On";
BA_ "VNSigAllNodes" SG_ 2150408192 Eng12vStrtrMtrCmmdOn 1;
BA_ "SignalType" SG_ 2150408192 AccPdlOvrrdAtv "BLN";
BA_ "SignalLongName" SG_ 2150408192 AccPdlOvrrdAtv "Accelerator Pedal Override Active";
BA_ "VNSigAllNodes" SG_ 2150408192 AccPdlOvrrdAtv 1;
BA_ "SignalType" SG_ 2150408192 TopTrvlCltchSwActV "ENM";
BA_ "SignalLongName" SG_ 2150408192 TopTrvlCltchSwActV "Top of Travel Clutch Switch Active Validity";
BA_ "VNSigAllNodes" SG_ 2150408192 TopTrvlCltchSwActV 1;
BA_ "SignalType" SG_ 2150408192 TopTrvlCltchSwAct "BLN";
BA_ "SignalLongName" SG_ 2150408192 TopTrvlCltchSwAct "Top of Travel Clutch Switch Active";
BA_ "VNSigAllNodes" SG_ 2150408192 TopTrvlCltchSwAct 1;
BA_ "SignalType" SG_ 2150408192 CltStartSwAtvV "ENM";
BA_ "SignalLongName" SG_ 2150408192 CltStartSwAtvV "Clutch Start Switch Active Validity";
BA_ "VNSigAllNodes" SG_ 2150408192 CltStartSwAtvV 1;
BA_ "SignalType" SG_ 2150408192 CltStartSwAtv "BLN";
BA_ "SignalLongName" SG_ 2150408192 CltStartSwAtv "Clutch Start Switch Active";
BA_ "GenSigStartValue" SG_ 2150408192 CltStartSwAtv 1;
BA_ "VNSigAllNodes" SG_ 2150408192 CltStartSwAtv 1;
BA_ "GenSigSendOnInit" SG_ 2150408192 CrsCntEnbld 1;
BA_ "SignalType" SG_ 2150408192 CrsCntEnbld "BLN";
BA_ "SignalLongName" SG_ 2150408192 CrsCntEnbld "Cruise Control Enabled";
BA_ "VNSigAllNodes" SG_ 2150408192 CrsCntEnbld 1;
BA_ "SignalType" SG_ 2150408192 AccActPosV "ENM";
BA_ "SignalLongName" SG_ 2150408192 AccActPosV "Accelerator Actual Position Validity";
BA_ "VNSigAllNodes" SG_ 2150408192 AccActPosV 1;
BA_ "SignalType" SG_ 2150408192 TrnsShftLvrPosV "ENM";
BA_ "SignalLongName" SG_ 2150408192 TrnsShftLvrPosV "Transmission Shift Lever Position Validity";
BA_ "VNSigAllNodes" SG_ 2150408192 TrnsShftLvrPosV 1;
BA_ "SignalType" SG_ 2150408192 TrnsSftMdStat "ENM";
BA_ "SignalLongName" SG_ 2150408192 TrnsSftMdStat "Transmission Shift Mode Status";
BA_ "VNSigAllNodes" SG_ 2150408192 TrnsSftMdStat 1;
BA_ "SignalType" SG_ 2150408192 EngSpd "UNM";
BA_ "SignalLongName" SG_ 2150408192 EngSpd "Engine Speed";
BA_ "VNSigAllNodes" SG_ 2150408192 EngSpd 1;
BA_ "SignalType" SG_ 2150408192 AutoTransComndGear "ENM";
BA_ "SignalLongName" SG_ 2150408192 AutoTransComndGear "Automatic Transmission Commanded Gear";
BA_ "GenSigStartValue" SG_ 2150408192 AutoTransComndGear 15;
BA_ "VNSigAllNodes" SG_ 2150408192 AutoTransComndGear 1;
BA_ "SignalType" SG_ 2150408192 TrnShftPtrnActStat "ENM";
BA_ "SignalLongName" SG_ 2150408192 TrnShftPtrnActStat "Transmission Shift Pattern Active Status";
BA_ "VNSigAllNodes" SG_ 2150408192 TrnShftPtrnActStat 1;
BA_ "SignalType" SG_ 2150408192 TrnsShftLvrPos "ENM";
BA_ "SignalLongName" SG_ 2150408192 TrnsShftLvrPos "Transmission Shift Lever Position";
BA_ "VNSigAllNodes" SG_ 2150408192 TrnsShftLvrPos 1;
BA_ "SignalType" SG_ 2150408192 AccActPos "UNM";
BA_ "SignalLongName" SG_ 2150408192 AccActPos "Accelerator Actual Position";
BA_ "VNSigAllNodes" SG_ 2150408192 AccActPos 1;
BA_ "SignalType" SG_ 2150408192 ThrPosV "ENM";
BA_ "SignalLongName" SG_ 2150408192 ThrPosV "Throttle Position Validity";
BA_ "VNSigAllNodes" SG_ 2150408192 ThrPosV 1;
BA_ "SignalType" SG_ 2150408192 TransTUDMdStat "ENM";
BA_ "SignalLongName" SG_ 2150408192 TransTUDMdStat "Transmission Tap Up/Tap Down Mode Status";
BA_ "VNSigAllNodes" SG_ 2150408192 TransTUDMdStat 1;
BA_ "SignalType" SG_ 2150408192 ThrPos "UNM";
BA_ "SignalLongName" SG_ 2150408192 ThrPos "Throttle Position";
BA_ "VNSigAllNodes" SG_ 2150408192 ThrPos 1;
BA_ "GenSigDeltaValue" SG_ 2155954176 ClmCntRrBlwFnSp 1;
BA_ "GenSigSendType" SG_ 2155954176 ClmCntRrBlwFnSp 12;
BA_ "GenSigSendOnInit" SG_ 2155954176 ClmCntRrBlwFnSp 2;
BA_ "SignalType" SG_ 2155954176 ClmCntRrBlwFnSp "UNM";
BA_ "SignalLongName" SG_ 2155954176 ClmCntRrBlwFnSp "Climate Control Rear Blower Fan Speed";
BA_ "VNSigAllNodes" SG_ 2155954176 ClmCntRrBlwFnSp 1;
BA_ "GenSigSendType" SG_ 2155954176 ClmCntlExtDefActIO 10;
BA_ "GenSigSendOnInit" SG_ 2155954176 ClmCntlExtDefActIO 2;
BA_ "SignalType" SG_ 2155954176 ClmCntlExtDefActIO "BLN";
BA_ "SignalLongName" SG_ 2155954176 ClmCntlExtDefActIO "Climate Control Extended Defrost Active Indication On";
BA_ "VNSigAllNodes" SG_ 2155954176 ClmCntlExtDefActIO 1;
BA_ "GenSigSendType" SG_ 2155954176 ClntCircPmpRq 10;
BA_ "GenSigSendOnInit" SG_ 2155954176 ClntCircPmpRq 2;
BA_ "VNSigIntermediate" SG_ 2155954176 ClntCircPmpRq 1;
BA_ "SignalType" SG_ 2155954176 ClntCircPmpRq "ENM";
BA_ "SignalLongName" SG_ 2155954176 ClntCircPmpRq "Coolant Circulation Pump Request";
BA_ "VNSigAllNodes" SG_ 2155954176 ClntCircPmpRq 1;
BA_ "GenSigSendType" SG_ 2155954176 ClimCtrlAftBlowModActv 10;
BA_ "GenSigSendOnInit" SG_ 2155954176 ClimCtrlAftBlowModActv 1;
BA_ "VNSigIntermediate" SG_ 2155954176 ClimCtrlAftBlowModActv 1;
BA_ "SignalType" SG_ 2155954176 ClimCtrlAftBlowModActv "BLN";
BA_ "SignalLongName" SG_ 2155954176 ClimCtrlAftBlowModActv "Climate Control Afterblow Mode Active";
BA_ "VNSigAllNodes" SG_ 2155954176 ClimCtrlAftBlowModActv 1;
BA_ "GenSigDeltaValue" SG_ 2155954176 ClmCntFrBlwFnSp 13;
BA_ "GenSigSendType" SG_ 2155954176 ClmCntFrBlwFnSp 12;
BA_ "GenSigSendOnInit" SG_ 2155954176 ClmCntFrBlwFnSp 2;
BA_ "VNSigIntermediate" SG_ 2155954176 ClmCntFrBlwFnSp 1;
BA_ "SignalType" SG_ 2155954176 ClmCntFrBlwFnSp "UNM";
BA_ "SignalLongName" SG_ 2155954176 ClmCntFrBlwFnSp "Climate Control Front Blower Fan Speed";
BA_ "VNSigAllNodes" SG_ 2155954176 ClmCntFrBlwFnSp 1;
BA_ "GenSigSendType" SG_ 2155954176 ACHtIdleBstLevReq 10;
BA_ "GenSigSendOnInit" SG_ 2155954176 ACHtIdleBstLevReq 1;
BA_ "SignalType" SG_ 2155954176 ACHtIdleBstLevReq "ENM";
BA_ "SignalLongName" SG_ 2155954176 ACHtIdleBstLevReq "Air Conditioning and Heating Idle Boost Level Request";
BA_ "VNSigAllNodes" SG_ 2155954176 ACHtIdleBstLevReq 1;
BA_ "GenSigDeltaValue" SG_ 2155954176 AirCndCmptLdEst 1;
BA_ "GenSigSendType" SG_ 2155954176 AirCndCmptLdEst 12;
BA_ "GenSigSendOnInit" SG_ 2155954176 AirCndCmptLdEst 2;
BA_ "SignalType" SG_ 2155954176 AirCndCmptLdEst "UNM";
BA_ "SignalLongName" SG_ 2155954176 AirCndCmptLdEst "Air Conditioning Compartment Load Estimated";
BA_ "VNSigAllNodes" SG_ 2155954176 AirCndCmptLdEst 1;
BA_ "GenSigSendType" SG_ 2155954176 AirCndActIO 10;
BA_ "GenSigSendOnInit" SG_ 2155954176 AirCndActIO 2;
BA_ "SignalType" SG_ 2155954176 AirCndActIO "BLN";
BA_ "SignalLongName" SG_ 2155954176 AirCndActIO "Air Conditioning Active Indication On";
BA_ "VNSigAllNodes" SG_ 2155954176 AirCndActIO 1;
BA_ "GenSigSendType" SG_ 2153971712 LftglsRelSwAct 10;
BA_ "GenSigSendOnInit" SG_ 2153971712 LftglsRelSwAct 2;
BA_ "SignalType" SG_ 2153971712 LftglsRelSwAct "BLN";
BA_ "SignalLongName" SG_ 2153971712 LftglsRelSwAct "Liftglass Release Switch Active";
BA_ "VNSigAllNodes" SG_ 2153971712 LftglsRelSwAct 1;
BA_ "GenSigSendType" SG_ 2153971712 LftglsAjrSwAct 10;
BA_ "GenSigSendOnInit" SG_ 2153971712 LftglsAjrSwAct 2;
BA_ "SignalType" SG_ 2153971712 LftglsAjrSwAct "BLN";
BA_ "SignalLongName" SG_ 2153971712 LftglsAjrSwAct "Liftglass Ajar Switch Active";
BA_ "VNSigAllNodes" SG_ 2153971712 LftglsAjrSwAct 1;
BA_ "SignalType" SG_ 2153971712 DDAjrSwAtvM "ENM";
BA_ "SignalLongName" SG_ 2153971712 DDAjrSwAtvM "Driver Door Ajar Switch Active Mask";
BA_ "VNSigAllNodes" SG_ 2153971712 DDAjrSwAtvM 1;
BA_ "GenSigSendType" SG_ 2153971712 DDAjrSwAtv 10;
BA_ "GenSigSendOnInit" SG_ 2153971712 DDAjrSwAtv 2;
BA_ "VNSigInfotainment" SG_ 2153971712 DDAjrSwAtv 1;
BA_ "VNSigIntermediate" SG_ 2153971712 DDAjrSwAtv 1;
BA_ "SignalType" SG_ 2153971712 DDAjrSwAtv "BLN";
BA_ "SignalLongName" SG_ 2153971712 DDAjrSwAtv "Driver Door Ajar Switch Active";
BA_ "VNSigAllNodes" SG_ 2153971712 DDAjrSwAtv 1;
BA_ "SignalType" SG_ 2149875712 BattStOfChrgLowIO "BLN";
BA_ "SignalLongName" SG_ 2149875712 BattStOfChrgLowIO "Battery State of Charge Low Indication On";
BA_ "VNSigAllNodes" SG_ 2149875712 BattStOfChrgLowIO 1;
BA_ "SignalType" SG_ 2149875712 BattCrntFltrd "SNM";
BA_ "SignalLongName" SG_ 2149875712 BattCrntFltrd "Battery Current Filtered";
BA_ "VNSigAllNodes" SG_ 2149875712 BattCrntFltrd 1;
BA_ "SignalType" SG_ 2149875712 IntlgntBattSnsFldIO "BLN";
BA_ "SignalLongName" SG_ 2149875712 IntlgntBattSnsFldIO "Intelligent Battery Sensor Failed Indication On";
BA_ "VNSigAllNodes" SG_ 2149875712 IntlgntBattSnsFldIO 1;
BA_ "SignalType" SG_ 2149875712 BatSvrMdSevLvl "UNM";
BA_ "SignalLongName" SG_ 2149875712 BatSvrMdSevLvl "Battery Saver Mode Severity Level";
BA_ "VNSigAllNodes" SG_ 2149875712 BatSvrMdSevLvl 1;
BA_ "SignalType" SG_ 2149875712 BatSOCV "ENM";
BA_ "SignalLongName" SG_ 2149875712 BatSOCV "Battery State of Charge Validity";
BA_ "VNSigAllNodes" SG_ 2149875712 BatSOCV 1;
BA_ "SignalType" SG_ 2149875712 PwrMdOffBattSOC "UNM";
BA_ "SignalLongName" SG_ 2149875712 PwrMdOffBattSOC "Power Mode Off Battery State Of Charge";
BA_ "VNSigAllNodes" SG_ 2149875712 PwrMdOffBattSOC 1;
BA_ "SignalType" SG_ 2149875712 EnrgMgtLdShdRq "ENM";
BA_ "SignalLongName" SG_ 2149875712 EnrgMgtLdShdRq "Energy Management Load Shedding Request";
BA_ "VNSigAllNodes" SG_ 2149875712 EnrgMgtLdShdRq 1;
BA_ "VNSigInfotainment" SG_ 2149875712 SrvBattChrgSysIO 1;
BA_ "SignalType" SG_ 2149875712 SrvBattChrgSysIO "BLN";
BA_ "SignalLongName" SG_ 2149875712 SrvBattChrgSysIO "Service Battery Charging System Indication On";
BA_ "VNSigAllNodes" SG_ 2149875712 SrvBattChrgSysIO 1;
BA_ "VNSigInfotainment" SG_ 2149875712 BattStOfChrgCrtyLow 1;
BA_ "VNSigIntermediate" SG_ 2149875712 BattStOfChrgCrtyLow 1;
BA_ "SignalType" SG_ 2149875712 BattStOfChrgCrtyLow "BLN";
BA_ "SignalLongName" SG_ 2149875712 BattStOfChrgCrtyLow "Battery State of Charge Critically Low";
BA_ "VNSigAllNodes" SG_ 2149875712 BattStOfChrgCrtyLow 1;
BA_ "VNSigInfotainment" SG_ 2149875712 BatSaverIO 1;
BA_ "SignalType" SG_ 2149875712 BatSaverIO "BLN";
BA_ "SignalLongName" SG_ 2149875712 BatSaverIO "Battery Saver Indication On";
BA_ "VNSigAllNodes" SG_ 2149875712 BatSaverIO 1;
BA_ "VNSigInfotainment" SG_ 2149875712 BatSOC 1;
BA_ "SignalType" SG_ 2149875712 BatSOC "UNM";
BA_ "SignalLongName" SG_ 2149875712 BatSOC "Battery State of Charge";
BA_ "VNSigAllNodes" SG_ 2149875712 BatSOC 1;
BA_ "SignalType" SG_ 2149875712 BattVltIRq "ENM";
BA_ "SignalLongName" SG_ 2149875712 BattVltIRq "Battery Voltage Indication Request";
BA_ "VNSigAllNodes" SG_ 2149875712 BattVltIRq 1;
BA_ "VNSigInfotainment" SG_ 2149875712 BatVltV 1;
BA_ "SignalType" SG_ 2149875712 BatVltV "ENM";
BA_ "SignalLongName" SG_ 2149875712 BatVltV "Battery Voltage Validity";
BA_ "VNSigAllNodes" SG_ 2149875712 BatVltV 1;
BA_ "VNSigInfotainment" SG_ 2149875712 BatVlt 1;
BA_ "SignalType" SG_ 2149875712 BatVlt "UNM";
BA_ "SignalLongName" SG_ 2149875712 BatVlt "Battery Voltage";
BA_ "VNSigAllNodes" SG_ 2149875712 BatVlt 1;
BA_ "GenSigSendType" SG_ 2151186432 CtLghtDet 10;
BA_ "GenSigSendOnInit" SG_ 2151186432 CtLghtDet 2;
BA_ "SignalType" SG_ 2151186432 CtLghtDet "BLN";
BA_ "SignalLongName" SG_ 2151186432 CtLghtDet "City Light Detected";
BA_ "VNSigAllNodes" SG_ 2151186432 CtLghtDet 1;
BA_ "GenSigSendType" SG_ 2151186432 AutoHgBmCtrlInOn 10;
BA_ "SignalType" SG_ 2151186432 AutoHgBmCtrlInOn "BLN";
BA_ "SignalLongName" SG_ 2151186432 AutoHgBmCtrlInOn "Auto High Beam Control Indication On";
BA_ "VNSigAllNodes" SG_ 2151186432 AutoHgBmCtrlInOn 1;
BA_ "GenSigSendType" SG_ 2151186432 AutoBmSlctStat 10;
BA_ "GenSigSendOnInit" SG_ 2151186432 AutoBmSlctStat 2;
BA_ "SignalType" SG_ 2151186432 AutoBmSlctStat "ENM";
BA_ "SignalLongName" SG_ 2151186432 AutoBmSlctStat "Automatic Beam Select Status";
BA_ "VNSigAllNodes" SG_ 2151186432 AutoBmSlctStat 1;
BA_ "GenSigSendType" SG_ 2149629952 FrFogLmpsAct 10;
BA_ "GenSigSendOnInit" SG_ 2149629952 FrFogLmpsAct 1;
BA_ "SignalType" SG_ 2149629952 FrFogLmpsAct "BLN";
BA_ "SignalLongName" SG_ 2149629952 FrFogLmpsAct "Front Fog Lamps Active";
BA_ "VNSigAllNodes" SG_ 2149629952 FrFogLmpsAct 1;
BA_ "GenSigSendType" SG_ 2149629952 HiBmReqd 10;
BA_ "SignalType" SG_ 2149629952 HiBmReqd "BLN";
BA_ "SignalLongName" SG_ 2149629952 HiBmReqd "High Beam Requested";
BA_ "VNSigAllNodes" SG_ 2149629952 HiBmReqd 1;
BA_ "GenSigSendType" SG_ 2149629952 PrkLtRightOn 10;
BA_ "GenSigSendOnInit" SG_ 2149629952 PrkLtRightOn 2;
BA_ "VNSigParkedVehicle" SG_ 2149629952 PrkLtRightOn 1;
BA_ "SignalType" SG_ 2149629952 PrkLtRightOn "BLN";
BA_ "SignalLongName" SG_ 2149629952 PrkLtRightOn "Park Light Right On";
BA_ "VNSigAllNodes" SG_ 2149629952 PrkLtRightOn 1;
BA_ "GenSigSendType" SG_ 2149629952 PrkLtLeftOn 10;
BA_ "GenSigSendOnInit" SG_ 2149629952 PrkLtLeftOn 2;
BA_ "VNSigParkedVehicle" SG_ 2149629952 PrkLtLeftOn 1;
BA_ "SignalType" SG_ 2149629952 PrkLtLeftOn "BLN";
BA_ "SignalLongName" SG_ 2149629952 PrkLtLeftOn "Park Light Left On";
BA_ "VNSigAllNodes" SG_ 2149629952 PrkLtLeftOn 1;
BA_ "GenSigSendType" SG_ 2149629952 TrnSwAct 10;
BA_ "GenSigSendOnInit" SG_ 2149629952 TrnSwAct 1;
BA_ "SignalType" SG_ 2149629952 TrnSwAct "ENM";
BA_ "SignalLongName" SG_ 2149629952 TrnSwAct "Turn Switch Activation";
BA_ "VNSigAllNodes" SG_ 2149629952 TrnSwAct 1;
BA_ "GenSigSendType" SG_ 2149629952 PrkLtRightIO 10;
BA_ "GenSigSendOnInit" SG_ 2149629952 PrkLtRightIO 2;
BA_ "VNSigParkedVehicle" SG_ 2149629952 PrkLtRightIO 1;
BA_ "SignalType" SG_ 2149629952 PrkLtRightIO "BLN";
BA_ "SignalLongName" SG_ 2149629952 PrkLtRightIO "Park Light Right Indication On";
BA_ "VNSigAllNodes" SG_ 2149629952 PrkLtRightIO 1;
BA_ "GenSigSendType" SG_ 2149629952 MainLghtSw 10;
BA_ "GenSigSendOnInit" SG_ 2149629952 MainLghtSw 1;
BA_ "SignalType" SG_ 2149629952 MainLghtSw "ENM";
BA_ "SignalLongName" SG_ 2149629952 MainLghtSw "Main Light Switch";
BA_ "VNSigAllNodes" SG_ 2149629952 MainLghtSw 1;
BA_ "GenSigSendType" SG_ 2149629952 PrkLtLeftIO 10;
BA_ "GenSigSendOnInit" SG_ 2149629952 PrkLtLeftIO 2;
BA_ "VNSigParkedVehicle" SG_ 2149629952 PrkLtLeftIO 1;
BA_ "SignalType" SG_ 2149629952 PrkLtLeftIO "BLN";
BA_ "SignalLongName" SG_ 2149629952 PrkLtLeftIO "Park Light Left Indication On";
BA_ "VNSigAllNodes" SG_ 2149629952 PrkLtLeftIO 1;
BA_ "GenSigSendType" SG_ 2149629952 HazSwAtv 10;
BA_ "GenSigSendOnInit" SG_ 2149629952 HazSwAtv 1;
BA_ "VNSigParkedVehicle" SG_ 2149629952 HazSwAtv 1;
BA_ "SignalType" SG_ 2149629952 HazSwAtv "BLN";
BA_ "SignalLongName" SG_ 2149629952 HazSwAtv "Hazard Switch Active";
BA_ "VNSigAllNodes" SG_ 2149629952 HazSwAtv 1;
BA_ "GenSigSendType" SG_ 2149629952 HiBmIO 10;
BA_ "GenSigSendOnInit" SG_ 2149629952 HiBmIO 1;
BA_ "SignalType" SG_ 2149629952 HiBmIO "BLN";
BA_ "SignalLongName" SG_ 2149629952 HiBmIO "High Beam Indication On";
BA_ "VNSigAllNodes" SG_ 2149629952 HiBmIO 1;
BA_ "GenSigSendType" SG_ 2149629952 FrFgLtIO 10;
BA_ "GenSigSendOnInit" SG_ 2149629952 FrFgLtIO 1;
BA_ "SignalType" SG_ 2149629952 FrFgLtIO "BLN";
BA_ "SignalLongName" SG_ 2149629952 FrFgLtIO "Front Fog Light Indication On";
BA_ "VNSigAllNodes" SG_ 2149629952 FrFgLtIO 1;
BA_ "GenSigSendType" SG_ 2149629952 AutoLtsInactIO 10;
BA_ "SignalType" SG_ 2149629952 AutoLtsInactIO "BLN";
BA_ "SignalLongName" SG_ 2149629952 AutoLtsInactIO "Automatic Lights Inactive Indication On";
BA_ "VNSigAllNodes" SG_ 2149629952 AutoLtsInactIO 1;
BA_ "GenSigSendType" SG_ 2149629952 AutoLtsActIO 10;
BA_ "SignalType" SG_ 2149629952 AutoLtsActIO "BLN";
BA_ "SignalLongName" SG_ 2149629952 AutoLtsActIO "Automatic Lights Active Indication On";
BA_ "VNSigAllNodes" SG_ 2149629952 AutoLtsActIO 1;
BA_ "GenSigSendType" SG_ 2149629952 LftTrnLmpAtv 10;
BA_ "GenSigSendOnInit" SG_ 2149629952 LftTrnLmpAtv 1;
BA_ "VNSigParkedVehicle" SG_ 2149629952 LftTrnLmpAtv 1;
BA_ "SignalType" SG_ 2149629952 LftTrnLmpAtv "ENM";
BA_ "SignalLongName" SG_ 2149629952 LftTrnLmpAtv "Left Turn Lamp Active";
BA_ "VNSigAllNodes" SG_ 2149629952 LftTrnLmpAtv 1;
BA_ "GenSigSendType" SG_ 2149629952 RtTrnLmpAtv 10;
BA_ "GenSigSendOnInit" SG_ 2149629952 RtTrnLmpAtv 1;
BA_ "VNSigParkedVehicle" SG_ 2149629952 RtTrnLmpAtv 1;
BA_ "SignalType" SG_ 2149629952 RtTrnLmpAtv "ENM";
BA_ "SignalLongName" SG_ 2149629952 RtTrnLmpAtv "Right Turn Lamp Active";
BA_ "VNSigAllNodes" SG_ 2149629952 RtTrnLmpAtv 1;
BA_ "GenSigSendType" SG_ 2149629952 RevLmpAtv 10;
BA_ "GenSigSendOnInit" SG_ 2149629952 RevLmpAtv 1;
BA_ "SignalType" SG_ 2149629952 RevLmpAtv "BLN";
BA_ "SignalLongName" SG_ 2149629952 RevLmpAtv "Reversing Lamp";
BA_ "VNSigAllNodes" SG_ 2149629952 RevLmpAtv 1;
BA_ "GenSigSendType" SG_ 2149629952 HdlmpBmSelectStat 10;
BA_ "GenSigSendOnInit" SG_ 2149629952 HdlmpBmSelectStat 1;
BA_ "SignalType" SG_ 2149629952 HdlmpBmSelectStat "ENM";
BA_ "SignalLongName" SG_ 2149629952 HdlmpBmSelectStat "Headlamp Beam Select Status";
BA_ "VNSigAllNodes" SG_ 2149629952 HdlmpBmSelectStat 1;
BA_ "GenSigSendType" SG_ 2149629952 SrvlnceMdAct 10;
BA_ "SignalType" SG_ 2149629952 SrvlnceMdAct "BLN";
BA_ "SignalLongName" SG_ 2149629952 SrvlnceMdAct "Surveillance Mode Active";
BA_ "VNSigAllNodes" SG_ 2149629952 SrvlnceMdAct 1;
BA_ "GenSigSendType" SG_ 2149629952 RrFgLtIO 10;
BA_ "SignalType" SG_ 2149629952 RrFgLtIO "BLN";
BA_ "SignalLongName" SG_ 2149629952 RrFgLtIO "Rear Fog Light Indication On";
BA_ "VNSigAllNodes" SG_ 2149629952 RrFgLtIO 1;
BA_ "GenSigSendType" SG_ 2149629952 PrkLtIO 10;
BA_ "GenSigSendOnInit" SG_ 2149629952 PrkLtIO 2;
BA_ "VNSigParkedVehicle" SG_ 2149629952 PrkLtIO 1;
BA_ "SignalType" SG_ 2149629952 PrkLtIO "BLN";
BA_ "SignalLongName" SG_ 2149629952 PrkLtIO "Park Light Indication On";
BA_ "VNSigAllNodes" SG_ 2149629952 PrkLtIO 1;
BA_ "GenSigSendType" SG_ 2149629952 OtsdAmbtLtLvlStatV 10;
BA_ "SignalType" SG_ 2149629952 OtsdAmbtLtLvlStatV "ENM";
BA_ "SignalLongName" SG_ 2149629952 OtsdAmbtLtLvlStatV "Outside Ambient Light Level Status Validity";
BA_ "VNSigAllNodes" SG_ 2149629952 OtsdAmbtLtLvlStatV 1;
BA_ "GenSigSendType" SG_ 2149629952 OtsdAmbtLtLvlStat 10;
BA_ "SignalType" SG_ 2149629952 OtsdAmbtLtLvlStat "ENM";
BA_ "SignalLongName" SG_ 2149629952 OtsdAmbtLtLvlStat "Outside Ambient Light Level Status";
BA_ "VNSigAllNodes" SG_ 2149629952 OtsdAmbtLtLvlStat 1;
BA_ "GenSigSendType" SG_ 2149629952 RrFogLmpsAct 10;
BA_ "GenSigSendOnInit" SG_ 2149629952 RrFogLmpsAct 1;
BA_ "SignalType" SG_ 2149629952 RrFogLmpsAct "BLN";
BA_ "SignalLongName" SG_ 2149629952 RrFogLmpsAct "Rear Fog Lamps Active";
BA_ "VNSigAllNodes" SG_ 2149629952 RrFogLmpsAct 1;
BA_ "GenSigSendType" SG_ 2149629952 PrkngLtsAct 10;
BA_ "GenSigSendOnInit" SG_ 2149629952 PrkngLtsAct 1;
BA_ "VNSigParkedVehicle" SG_ 2149629952 PrkngLtsAct 1;
BA_ "SignalType" SG_ 2149629952 PrkngLtsAct "BLN";
BA_ "SignalLongName" SG_ 2149629952 PrkngLtsAct "Parking Lights Active";
BA_ "VNSigAllNodes" SG_ 2149629952 PrkngLtsAct 1;
BA_ "GenSigSendType" SG_ 2149629952 BrkLtsAtv 10;
BA_ "GenSigSendOnInit" SG_ 2149629952 BrkLtsAtv 1;
BA_ "SignalType" SG_ 2149629952 BrkLtsAtv "BLN";
BA_ "SignalLongName" SG_ 2149629952 BrkLtsAtv "Brake Lights Active";
BA_ "VNSigAllNodes" SG_ 2149629952 BrkLtsAtv 1;
BA_ "GenSigSendType" SG_ 2149629952 AutoBmSlctAllwd 10;
BA_ "GenSigSendOnInit" SG_ 2149629952 AutoBmSlctAllwd 2;
BA_ "SignalType" SG_ 2149629952 AutoBmSlctAllwd "BLN";
BA_ "SignalLongName" SG_ 2149629952 AutoBmSlctAllwd "Automatic Beam Select Allowed";
BA_ "VNSigAllNodes" SG_ 2149629952 AutoBmSlctAllwd 1;
BA_ "GenSigSendType" SG_ 2149629952 FlToPsSwAtv 10;
BA_ "SignalType" SG_ 2149629952 FlToPsSwAtv "BLN";
BA_ "SignalLongName" SG_ 2149629952 FlToPsSwAtv "Flash To Pass Switch Active";
BA_ "VNSigAllNodes" SG_ 2149629952 FlToPsSwAtv 1;
BA_ "GenSigSendType" SG_ 2149629952 DRLAct 10;
BA_ "SignalType" SG_ 2149629952 DRLAct "BLN";
BA_ "SignalLongName" SG_ 2149629952 DRLAct "Daytime Running Lamps Active";
BA_ "VNSigAllNodes" SG_ 2149629952 DRLAct 1;
BA_ "SignalType" SG_ 2149646336 VehSpdAvgDrvnSrc "ENM";
BA_ "SignalLongName" SG_ 2149646336 VehSpdAvgDrvnSrc "Vehicle Speed Average Driven Source";
BA_ "VNSigAllNodes" SG_ 2149646336 VehSpdAvgDrvnSrc 1;
BA_ "SignalType" SG_ 2149646336 VehSpdAvgNDrvnV "ENM";
BA_ "SignalLongName" SG_ 2149646336 VehSpdAvgNDrvnV "Vehicle Speed Average Non Driven Validity";
BA_ "VNSigAllNodes" SG_ 2149646336 VehSpdAvgNDrvnV 1;
BA_ "GenSigSendOnInit" SG_ 2149646336 VehSpdAvgNDrvn 1;
BA_ "SignalType" SG_ 2149646336 VehSpdAvgNDrvn "UNM";
BA_ "SignalLongName" SG_ 2149646336 VehSpdAvgNDrvn "Vehicle Speed Average Non Driven";
BA_ "VNSigAllNodes" SG_ 2149646336 VehSpdAvgNDrvn 1;
BA_ "SignalType" SG_ 2149646336 DstRolCntAvgNonDrvnV "ENM";
BA_ "SignalLongName" SG_ 2149646336 DstRolCntAvgNonDrvnV "Distance Rolling Count Average Non Driven Validity";
BA_ "VNSigAllNodes" SG_ 2149646336 DstRolCntAvgNonDrvnV 1;
BA_ "SignalType" SG_ 2149646336 DstRolCntAvNDrRstOc "BLN";
BA_ "SignalLongName" SG_ 2149646336 DstRolCntAvNDrRstOc "Distance Rolling Count Average Non Driven Reset Occurred";
BA_ "VNSigAllNodes" SG_ 2149646336 DstRolCntAvNDrRstOc 1;
BA_ "SignalType" SG_ 2149646336 DstRolCntAvgNonDrvn "UNM";
BA_ "SignalLongName" SG_ 2149646336 DstRolCntAvgNonDrvn "Distance Rolling Count Average Non Driven";
BA_ "VNSigAllNodes" SG_ 2149646336 DstRolCntAvgNonDrvn 1;
BA_ "SignalType" SG_ 2149646336 DstRolCntAvgDrnRstOc "BLN";
BA_ "SignalLongName" SG_ 2149646336 DstRolCntAvgDrnRstOc "Distance Rolling Count Average Driven Reset Occurred";
BA_ "VNSigAllNodes" SG_ 2149646336 DstRolCntAvgDrnRstOc 1;
BA_ "SignalType" SG_ 2149646336 DistRollCntAvgDrvnV "ENM";
BA_ "SignalLongName" SG_ 2149646336 DistRollCntAvgDrvnV "Distance Rolling Count Average Driven Validity";
BA_ "VNSigAllNodes" SG_ 2149646336 DistRollCntAvgDrvnV 1;
BA_ "SignalType" SG_ 2149646336 DistRollCntAvgDrvnSrc "ENM";
BA_ "SignalLongName" SG_ 2149646336 DistRollCntAvgDrvnSrc "Distance Rolling Count Average Driven Source";
BA_ "VNSigAllNodes" SG_ 2149646336 DistRollCntAvgDrvnSrc 1;
BA_ "SignalType" SG_ 2149646336 DistRollCntAvgDrvn "UNM";
BA_ "SignalLongName" SG_ 2149646336 DistRollCntAvgDrvn "Distance Rolling Count Average Driven";
BA_ "VNSigAllNodes" SG_ 2149646336 DistRollCntAvgDrvn 1;
BA_ "SignalType" SG_ 2149646336 VehSpdAvgDrvnV "ENM";
BA_ "SignalLongName" SG_ 2149646336 VehSpdAvgDrvnV "Vehicle Speed Average Driven Validity";
BA_ "VNSigAllNodes" SG_ 2149646336 VehSpdAvgDrvnV 1;
BA_ "SignalType" SG_ 2149646336 VehSpdAvgDrvn "UNM";
BA_ "SignalLongName" SG_ 2149646336 VehSpdAvgDrvn "Vehicle Speed Average Driven";
BA_ "VNSigAllNodes" SG_ 2149646336 VehSpdAvgDrvn 1;
BA_ "GenSigSendType" SG_ 2154053632 CargoLmpActIO 10;
BA_ "SignalType" SG_ 2154053632 CargoLmpActIO "BLN";
BA_ "SignalLongName" SG_ 2154053632 CargoLmpActIO "Cargo Lamp Active Indication On";
BA_ "VNSigAllNodes" SG_ 2154053632 CargoLmpActIO 1;
BA_ "GenSigSendType" SG_ 2154053632 DispNtSchmAtv 10;
BA_ "GenSigSendOnInit" SG_ 2154053632 DispNtSchmAtv 2;
BA_ "VNSigInfotainment" SG_ 2154053632 DispNtSchmAtv 1;
BA_ "SignalType" SG_ 2154053632 DispNtSchmAtv "BLN";
BA_ "SignalLongName" SG_ 2154053632 DispNtSchmAtv "Display Night Scheme Active";
BA_ "VNSigAllNodes" SG_ 2154053632 DispNtSchmAtv 1;
BA_ "GenSigDeltaValue" SG_ 2154053632 IntDimLvl 1;
BA_ "GenSigSendType" SG_ 2154053632 IntDimLvl 12;
BA_ "GenSigSendOnInit" SG_ 2154053632 IntDimLvl 2;
BA_ "VNSigInfotainment" SG_ 2154053632 IntDimLvl 1;
BA_ "SignalType" SG_ 2154053632 IntDimLvl "UNM";
BA_ "SignalLongName" SG_ 2154053632 IntDimLvl "Interior Dimming Level";
BA_ "VNSigAllNodes" SG_ 2154053632 IntDimLvl 1;
BA_ "GenSigDeltaValue" SG_ 2154053632 IntDimDspLvl 1;
BA_ "GenSigSendType" SG_ 2154053632 IntDimDspLvl 12;
BA_ "GenSigSendOnInit" SG_ 2154053632 IntDimDspLvl 2;
BA_ "VNSigInfotainment" SG_ 2154053632 IntDimDspLvl 1;
BA_ "SignalType" SG_ 2154053632 IntDimDspLvl "UNM";
BA_ "SignalLongName" SG_ 2154053632 IntDimDspLvl "Interior Dimming Display Level";
BA_ "VNSigAllNodes" SG_ 2154053632 IntDimDspLvl 1;
BA_ "GenSigSendType" SG_ 2154053632 IntDimNtPnlAtv 10;
BA_ "VNSigInfotainment" SG_ 2154053632 IntDimNtPnlAtv 1;
BA_ "SignalType" SG_ 2154053632 IntDimNtPnlAtv "BLN";
BA_ "SignalLongName" SG_ 2154053632 IntDimNtPnlAtv "Interior Dimming Night Panel Active";
BA_ "VNSigAllNodes" SG_ 2154053632 IntDimNtPnlAtv 1;
BA_ "SignalType" SG_ 1623 DgnInf "UNM";
BA_ "SignalLongName" SG_ 1623 DgnInf "Diagnostic Information";
BA_ "VNSigDiagnostic" SG_ 1623 DgnInf 1;
BA_ "VNSigAllNodes" SG_ 1623 DgnInf 1;
BA_ "GenSigSendType" SG_ 2154217472 CrShrngFbsEnblReq 10;
BA_ "VNSigIntermediate" SG_ 2154217472 CrShrngFbsEnblReq 1;
BA_ "SignalType" SG_ 2154217472 CrShrngFbsEnblReq "ENM";
BA_ "SignalLongName" SG_ 2154217472 CrShrngFbsEnblReq "Car Sharing Fobs Enable Request";
BA_ "GenSigSendType" SG_ 2154217472 CSRCR_CrtfctIdntfcn 10;
BA_ "VNSigIntermediate" SG_ 2154217472 CSRCR_CrtfctIdntfcn 1;
BA_ "SignalType" SG_ 2154217472 CSRCR_CrtfctIdntfcn "UNM";
BA_ "PacketOrder" SG_ 2154217472 CSRCR_CrtfctIdntfcn 3;
BA_ "SignalLongName" SG_ 2154217472 CSRCR_CrtfctIdntfcn "Car Sharing Revoke Certificate Request : Certificate Identification";
BA_ "GenSigSendType" SG_ 2154217472 CSRCR_Cmnd 10;
BA_ "VNSigIntermediate" SG_ 2154217472 CSRCR_Cmnd 1;
BA_ "SignalType" SG_ 2154217472 CSRCR_Cmnd "ENM";
BA_ "PacketOrder" SG_ 2154217472 CSRCR_Cmnd 1;
BA_ "SignalLongName" SG_ 2154217472 CSRCR_Cmnd "Car Sharing Revoke Certificate Request  : Command";
BA_ "GenSigSendType" SG_ 2149851136 KylsStrtAuthRq 10;
BA_ "SignalType" SG_ 2149851136 KylsStrtAuthRq "BLN";
BA_ "SignalLongName" SG_ 2149851136 KylsStrtAuthRq "Keyless Start Authentication Requested";
BA_ "VNSigAllNodes" SG_ 2149851136 KylsStrtAuthRq 1;
BA_ "GenSigSendType" SG_ 2149851136 SysPwrMd 10;
BA_ "GenSigSendOnInit" SG_ 2149851136 SysPwrMd 2;
BA_ "VNSigInfotainment" SG_ 2149851136 SysPwrMd 1;
BA_ "VNSigParkedVehicle" SG_ 2149851136 SysPwrMd 1;
BA_ "VNSigIntermediate" SG_ 2149851136 SysPwrMd 1;
BA_ "SignalType" SG_ 2149851136 SysPwrMd "ENM";
BA_ "SignalLongName" SG_ 2149851136 SysPwrMd "System Power Mode";
BA_ "VNSigAllNodes" SG_ 2149851136 SysPwrMd 1;
BA_ "GenSigSendType" SG_ 2149851136 SysPwrMdV 10;
BA_ "VNSigInfotainment" SG_ 2149851136 SysPwrMdV 1;
BA_ "VNSigParkedVehicle" SG_ 2149851136 SysPwrMdV 1;
BA_ "VNSigIntermediate" SG_ 2149851136 SysPwrMdV 1;
BA_ "SignalType" SG_ 2149851136 SysPwrMdV "ENM";
BA_ "SignalLongName" SG_ 2149851136 SysPwrMdV "System Power Mode Validity";
BA_ "VNSigAllNodes" SG_ 2149851136 SysPwrMdV 1;
BA_ "GenSigDeltaValue" SG_ 2033 PCUInfo 1;
BA_ "GenSigSendType" SG_ 2033 PCUInfo 12;
BA_ "SignalType" SG_ 2033 PCUInfo "UNM";
BA_ "SignalLongName" SG_ 2033 PCUInfo "Pyrotechnical Control Unit Information";
BA_ "VNSigAllNodes" SG_ 2033 PCUInfo 1;
BA_ "SignalType" SG_ 587 DgnInf "UNM";
BA_ "SignalLongName" SG_ 587 DgnInf "Diagnostic Information";
BA_ "VNSigDiagnostic" SG_ 587 DgnInf 1;
BA_ "VNSigAllNodes" SG_ 587 DgnInf 1;
BA_ "GenSigSendType" SG_ 2151530496 OfBrdHVCVhCsChRqRmt1 10;
BA_ "VNSigInfotainment" SG_ 2151530496 OfBrdHVCVhCsChRqRmt1 1;
BA_ "SignalType" SG_ 2151530496 OfBrdHVCVhCsChRqRmt1 "BLN";
BA_ "SignalLongName" SG_ 2151530496 OfBrdHVCVhCsChRqRmt1 "Off Board High Voltage Charging Vehicle Cease Charging Requested Remote 1";
BA_ "VNSigAllNodes" SG_ 2151530496 OfBrdHVCVhCsChRqRmt1 1;
BA_ "GenSigSendType" SG_ 2151530496 PrtyChrgRqRmt1 10;
BA_ "VNSigInfotainment" SG_ 2151530496 PrtyChrgRqRmt1 1;
BA_ "SignalType" SG_ 2151530496 PrtyChrgRqRmt1 "ENM";
BA_ "SignalLongName" SG_ 2151530496 PrtyChrgRqRmt1 "Priority Charging Request Remote 1";
BA_ "VNSigAllNodes" SG_ 2151530496 PrtyChrgRqRmt1 1;
BA_ "GenSigSendType" SG_ 2151530496 StTODChrgTmpOvrdRmt1 10;
BA_ "VNSigInfotainment" SG_ 2151530496 StTODChrgTmpOvrdRmt1 1;
BA_ "SignalType" SG_ 2151530496 StTODChrgTmpOvrdRmt1 "ENM";
BA_ "SignalLongName" SG_ 2151530496 StTODChrgTmpOvrdRmt1 "Set Time of Day Charge Temporary Override Remote 1";
BA_ "VNSigAllNodes" SG_ 2151530496 StTODChrgTmpOvrdRmt1 1;
BA_ "GenSigSendType" SG_ 2151530496 HVChgSyChgLvPfStRmt1 10;
BA_ "VNSigInfotainment" SG_ 2151530496 HVChgSyChgLvPfStRmt1 1;
BA_ "SignalType" SG_ 2151530496 HVChgSyChgLvPfStRmt1 "ENM";
BA_ "SignalLongName" SG_ 2151530496 HVChgSyChgLvPfStRmt1 "High Voltage Charging System Charge Level Preference Setting Remote 1";
BA_ "VNSigAllNodes" SG_ 2151530496 HVChgSyChgLvPfStRmt1 1;
BA_ "GenSigSendType" SG_ 2151530496 HVBatTmBsChgMdRqRmt1 10;
BA_ "VNSigInfotainment" SG_ 2151530496 HVBatTmBsChgMdRqRmt1 1;
BA_ "SignalType" SG_ 2151530496 HVBatTmBsChgMdRqRmt1 "ENM";
BA_ "SignalLongName" SG_ 2151530496 HVBatTmBsChgMdRqRmt1 "High Voltage Battery Time Based Charging Mode Request Remote 1";
BA_ "VNSigAllNodes" SG_ 2151530496 HVBatTmBsChgMdRqRmt1 1;
BA_ "GenSigDeltaValue" SG_ 2151530496 HVBTBDCSRR1_DChMHSRq 1;
BA_ "GenSigSendType" SG_ 2151530496 HVBTBDCSRR1_DChMHSRq 12;
BA_ "VNSigInfotainment" SG_ 2151530496 HVBTBDCSRR1_DChMHSRq 1;
BA_ "SignalType" SG_ 2151530496 HVBTBDCSRR1_DChMHSRq "UNM";
BA_ "PacketOrder" SG_ 2151530496 HVBTBDCSRR1_DChMHSRq 5;
BA_ "SignalLongName" SG_ 2151530496 HVBTBDCSRR1_DChMHSRq "High Voltage Battery Time Based Delayed Charging Set Request Remote 1 : Delayed Charging Minute of Hour Set Request";
BA_ "VNSigAllNodes" SG_ 2151530496 HVBTBDCSRR1_DChMHSRq 1;
BA_ "GenSigSendType" SG_ 2151530496 HVBTBDCSRR1_DChSnSRq 10;
BA_ "VNSigInfotainment" SG_ 2151530496 HVBTBDCSRR1_DChSnSRq 1;
BA_ "SignalType" SG_ 2151530496 HVBTBDCSRR1_DChSnSRq "ENM";
BA_ "PacketOrder" SG_ 2151530496 HVBTBDCSRR1_DChSnSRq 4;
BA_ "SignalLongName" SG_ 2151530496 HVBTBDCSRR1_DChSnSRq "High Voltage Battery Time Based Delayed Charging Set Request Remote 1 : Delayed Charging Season Set Request";
BA_ "VNSigAllNodes" SG_ 2151530496 HVBTBDCSRR1_DChSnSRq 1;
BA_ "GenSigSendType" SG_ 2151530496 HVBTBDCSRR1_DChSlSRq 10;
BA_ "VNSigInfotainment" SG_ 2151530496 HVBTBDCSRR1_DChSlSRq 1;
BA_ "SignalType" SG_ 2151530496 HVBTBDCSRR1_DChSlSRq "ENM";
BA_ "PacketOrder" SG_ 2151530496 HVBTBDCSRR1_DChSlSRq 3;
BA_ "SignalLongName" SG_ 2151530496 HVBTBDCSRR1_DChSlSRq "High Voltage Battery Time Based Delayed Charging Set Request Remote 1 : Delayed Charging Selected Set Request";
BA_ "VNSigAllNodes" SG_ 2151530496 HVBTBDCSRR1_DChSlSRq 1;
BA_ "GenSigSendType" SG_ 2151530496 HVBTBDCSRR1_DChDStRq 10;
BA_ "VNSigInfotainment" SG_ 2151530496 HVBTBDCSRR1_DChDStRq 1;
BA_ "SignalType" SG_ 2151530496 HVBTBDCSRR1_DChDStRq "ENM";
BA_ "PacketOrder" SG_ 2151530496 HVBTBDCSRR1_DChDStRq 2;
BA_ "SignalLongName" SG_ 2151530496 HVBTBDCSRR1_DChDStRq "High Voltage Battery Time Based Delayed Charging Set Request Remote 1 : Delayed Charging Day Set Request";
BA_ "VNSigAllNodes" SG_ 2151530496 HVBTBDCSRR1_DChDStRq 1;
BA_ "GenSigDeltaValue" SG_ 2151530496 HVBTBDCSRR1_DChHStRq 1;
BA_ "GenSigSendType" SG_ 2151530496 HVBTBDCSRR1_DChHStRq 12;
BA_ "VNSigInfotainment" SG_ 2151530496 HVBTBDCSRR1_DChHStRq 1;
BA_ "SignalType" SG_ 2151530496 HVBTBDCSRR1_DChHStRq "UNM";
BA_ "PacketOrder" SG_ 2151530496 HVBTBDCSRR1_DChHStRq 1;
BA_ "SignalLongName" SG_ 2151530496 HVBTBDCSRR1_DChHStRq "High Voltage Battery Time Based Delayed Charging Set Request Remote 1 : Delayed Charging Hour Set Request";
BA_ "VNSigAllNodes" SG_ 2151530496 HVBTBDCSRR1_DChHStRq 1;
BA_ "GenSigSendType" SG_ 2151530496 TrPrsMntrTrLdStat 10;
BA_ "SignalType" SG_ 2151530496 TrPrsMntrTrLdStat "ENM";
BA_ "SignalLongName" SG_ 2151530496 TrPrsMntrTrLdStat "Tire Pressure Monitoring Tire Loading Status";
BA_ "VNSigAllNodes" SG_ 2151530496 TrPrsMntrTrLdStat 1;
BA_ "GenSigSendType" SG_ 2151530496 TrPrsMntrAtLocFld 10;
BA_ "SignalType" SG_ 2151530496 TrPrsMntrAtLocFld "BLN";
BA_ "SignalLongName" SG_ 2151530496 TrPrsMntrAtLocFld "Tire Pressure Monitoring Autolocation System Failed";
BA_ "VNSigAllNodes" SG_ 2151530496 TrPrsMntrAtLocFld 1;
BA_ "GenSigSendType" SG_ 2151530496 TireLocatnWarnEn 10;
BA_ "SignalType" SG_ 2151530496 TireLocatnWarnEn "BLN";
BA_ "SignalLongName" SG_ 2151530496 TireLocatnWarnEn "Tire Location Warnings Enabled";
BA_ "VNSigAllNodes" SG_ 2151530496 TireLocatnWarnEn 1;
BA_ "GenSigSendType" SG_ 2151530496 WintTrRecIndOn 10;
BA_ "SignalType" SG_ 2151530496 WintTrRecIndOn "BLN";
BA_ "SignalLongName" SG_ 2151530496 WintTrRecIndOn "Winter Tire Recognition Indication On";
BA_ "VNSigAllNodes" SG_ 2151530496 WintTrRecIndOn 1;
BA_ "GenSigSendType" SG_ 2151530496 TrPrsMntrFld 10;
BA_ "SignalType" SG_ 2151530496 TrPrsMntrFld "BLN";
BA_ "SignalLongName" SG_ 2151530496 TrPrsMntrFld "Tire Pressure Monitoring System Failed";
BA_ "VNSigAllNodes" SG_ 2151530496 TrPrsMntrFld 1;
BA_ "GenSigSendType" SG_ 2151530496 TrRrAxlPresStat 10;
BA_ "SignalType" SG_ 2151530496 TrRrAxlPresStat "ENM";
BA_ "SignalLongName" SG_ 2151530496 TrRrAxlPresStat "Tire Rear Axle Pressure Status";
BA_ "VNSigAllNodes" SG_ 2151530496 TrRrAxlPresStat 1;
BA_ "GenSigSendType" SG_ 2151530496 TrFrntAxlPresStat 10;
BA_ "SignalType" SG_ 2151530496 TrFrntAxlPresStat "ENM";
BA_ "SignalLongName" SG_ 2151530496 TrFrntAxlPresStat "Tire Front Axle Pressure Status";
BA_ "VNSigAllNodes" SG_ 2151530496 TrFrntAxlPresStat 1;
BA_ "GenSigSendType" SG_ 2151530496 TPMTrLrnMdCmplt 10;
BA_ "GenSigSendOnInit" SG_ 2151530496 TPMTrLrnMdCmplt 2;
BA_ "SignalType" SG_ 2151530496 TPMTrLrnMdCmplt "BLN";
BA_ "SignalLongName" SG_ 2151530496 TPMTrLrnMdCmplt "Tire Pressure Monitoring Tire Learn Mode Complete";
BA_ "GenSigStartValue" SG_ 2151530496 TPMTrLrnMdCmplt 1;
BA_ "VNSigAllNodes" SG_ 2151530496 TPMTrLrnMdCmplt 1;
BA_ "SignalType" SG_ 1625 DgnInf "UNM";
BA_ "SignalLongName" SG_ 1625 DgnInf "Diagnostic Information";
BA_ "VNSigDiagnostic" SG_ 1625 DgnInf 1;
BA_ "VNSigAllNodes" SG_ 1625 DgnInf 1;
BA_ "SignalType" SG_ 1349 DgnInf_LS545 "UNM";
BA_ "SignalLongName" SG_ 1349 DgnInf_LS545 "Diagnostic Information LS545";
BA_ "VNSigDiagnostic" SG_ 1349 DgnInf_LS545 1;
BA_ "VNSigAllNodes" SG_ 1349 DgnInf_LS545 1;
BA_ "SignalType" SG_ 1605 DgnInf "UNM";
BA_ "SignalLongName" SG_ 1605 DgnInf "Diagnostic Information";
BA_ "VNSigDiagnostic" SG_ 1605 DgnInf 1;
BA_ "VNSigAllNodes" SG_ 1605 DgnInf 1;
BA_ "SignalType" SG_ 581 DgnInf "UNM";
BA_ "SignalLongName" SG_ 581 DgnInf "Diagnostic Information";
BA_ "VNSigDiagnostic" SG_ 581 DgnInf 1;
BA_ "VNSigAllNodes" SG_ 581 DgnInf 1;
BA_REL_ "GenSigSuprvResp" BU_SG_REL_ EOCM2cp_K2_LS SG_ 2150760448 NotSndRwRtSeatStat 1;
BA_REL_ "GenSigSuprvResp" BU_SG_REL_ EOCM2cp_K2_LS SG_ 2150760448 NotSndRwMdlSeatStat 1;
BA_REL_ "GenSigSuprvResp" BU_SG_REL_ EOCM2cp_K2_LS SG_ 2150760448 NotSndRwLtSeatStat 1;
BA_REL_ "GenSigSuprvResp" BU_SG_REL_ EOCM2cp_K2_LS SG_ 2150760448 NotPsSeatStat 1;
BA_REL_ "GenSigSuprvResp" BU_SG_REL_ EOCM2cp_K2_LS SG_ 2150760448 NotDrvSeatStat 1;
BA_REL_ "GenSigSuprvResp" BU_SG_REL_ EOCM2cp_K2_LS SG_ 2150760448 NotSecRowRtSeaOccStat 1;
BA_REL_ "GenSigSuprvResp" BU_SG_REL_ EOCM2cp_K2_LS SG_ 2150760448 NotSecRowLeSeaOccStat 1;
BA_REL_ "GenSigSuprvResp" BU_SG_REL_ EOCM2cp_K2_LS SG_ 2150760448 NotSecRowCtSeaOccStat 1;
BA_REL_ "GenSigSuprvResp" BU_SG_REL_ EOCM2cp_K2_LS SG_ 2150760448 NotiFrntPasSeatOccSta 1;
BA_REL_ "GenSigSuprvResp" BU_SG_REL_ EOCM2cp_K2_LS SG_ 2150760448 NotEventStat 1;
BA_REL_ "GenSigRxStartValue" BU_SG_REL_ BCM_LS SG_ 2150760448 NotEventStat "0";
BA_REL_ "GenSigSuprvResp" BU_SG_REL_ EOCM2cp_K2_LS SG_ 2150760448 NotiEventCount 1;
BA_REL_ "GenSigSuprvResp" BU_SG_REL_ EOCM2cp_K2_LS SG_ 2150760448 NESSRoSevSt 1;
BA_REL_ "GenSigSuprvResp" BU_SG_REL_ EOCM2cp_K2_LS SG_ 2150760448 NESSRiSiSevSt 1;
BA_REL_ "GenSigSuprvResp" BU_SG_REL_ EOCM2cp_K2_LS SG_ 2150760448 NESSReImpSevSt 1;
BA_REL_ "GenSigSuprvResp" BU_SG_REL_ EOCM2cp_K2_LS SG_ 2150760448 NESSLeSiSevSt 1;
BA_REL_ "GenSigSuprvResp" BU_SG_REL_ EOCM2cp_K2_LS SG_ 2150760448 NESSFrImpSt2SevSt 1;
BA_REL_ "GenSigSuprvResp" BU_SG_REL_ EOCM2cp_K2_LS SG_ 2150760448 NESSFrImpSt1SevSt 1;
BA_REL_ "GenSigSuprvResp" BU_SG_REL_ EOCM2cp_K2_LS SG_ 2150760448 NESSFrImpPreSevSt 1;
BA_REL_ "GenSigSuprvResp" BU_SG_REL_ EOCM2cp_K2_LS SG_ 2150760448 NEDLSRtSdArbgDld 1;
BA_REL_ "GenSigSuprvResp" BU_SG_REL_ EOCM2cp_K2_LS SG_ 2150760448 NEDLSLtSdArbgDld 1;
BA_REL_ "GenSigSuprvResp" BU_SG_REL_ EOCM2cp_K2_LS SG_ 2150760448 NEDLSSdCrtnArbgDpld 1;
BA_REL_ "GenSigSuprvResp" BU_SG_REL_ EOCM2cp_K2_LS SG_ 2150760448 NEDLSPaFrSt2De 1;
BA_REL_ "GenSigSuprvResp" BU_SG_REL_ EOCM2cp_K2_LS SG_ 2150760448 NEDLSPaFrSt1De 1;
BA_REL_ "GenSigSuprvResp" BU_SG_REL_ EOCM2cp_K2_LS SG_ 2150760448 NEDLSDrFrSt2De 1;
BA_REL_ "GenSigSuprvResp" BU_SG_REL_ EOCM2cp_K2_LS SG_ 2150760448 NEDLSDrFrSt1De 1;
BA_REL_ "GenSigSuprvResp" BU_SG_REL_ EOCM2cp_K2_LS SG_ 2150760448 SIRDpl 1;
BA_REL_ "GenSigSuprvResp" BU_SG_REL_ MCTM_LS SG_ 2150760448 SIRDpl 1;
BA_REL_ "GenSigSuprvResp" BU_SG_REL_ PEPS_LS SG_ 2150760448 SIRDpl 1;
BA_REL_ "GenSigSuprvResp" BU_SG_REL_ BCM_LS SG_ 2150760448 SIRDpl 1;
BA_REL_ "GenSigRxStartValue" BU_SG_REL_ BCM_LS SG_ 2150760448 SIRDpl "False";
BA_REL_ "GenSigSuprvResp" BU_SG_REL_ BCM_LS SG_ 2150760448 SIRDpl 1;
BA_REL_ "GenSigSuprvResp" BU_SG_REL_ BCM_LS SG_ 2150760448 SIRDpl 1;
BA_REL_ "GenSigSuprvResp" BU_SG_REL_ BCM_LS SG_ 2150760448 SIRDpl 1;
BA_REL_ "GenSigRxStartValue" BU_SG_REL_ BCM_LS SG_ 2150760448 SIRDpl "False";
BA_REL_ "GenSigSuprvResp" BU_SG_REL_ BCM_LS SG_ 2150760448 SIRDpl 1;
BA_REL_ "GenSigRxStartValue" BU_SG_REL_ BCM_LS SG_ 2150760448 SIRDpl "False";
BA_REL_ "GenSigSuprvResp" BU_SG_REL_ BCM_LS SG_ 2150760448 SIRDpl 1;
BA_REL_ "GenSigSuprvResp" BU_SG_REL_ ECC_LS SG_ 2150760448 SIRDpl 1;
BA_REL_ "GenSigSuprvResp" BU_SG_REL_ ECC_LS SG_ 2150760448 SIRDpl 1;
BA_REL_ "GenSigSuprvResp" BU_SG_REL_ EOCM2cp_K1_LS SG_ 2156175360 NtVsnSysEnbld 1;
BA_REL_ "GenSigSuprvResp" BU_SG_REL_ EOCM2cp_K1_LS SG_ 2156175360 DispMeasSysExt 1;
BA_REL_ "GenSigSuprvResp" BU_SG_REL_ EOCM2cp_K1_LS SG_ 2156175360 DispMeasSys 1;
BA_REL_ "GenSigSuprvResp" BU_SG_REL_ BCM_LS SG_ 2156175360 DispMeasSys 1;
BA_REL_ "GenSigRxStartValue" BU_SG_REL_ SCCM_2_LS SG_ 2149859328 SysBkUpPwrMdV "Valid";
BA_REL_ "GenSigRxStartValue" BU_SG_REL_ SCCM_1_LS SG_ 2149859328 SysBkUpPwrMdV "Valid";
BA_REL_ "GenSigSuprvResp" BU_SG_REL_ EOCM2cp_K2_LS SG_ 2149859328 SysBkUpPwrMdV 1;
BA_REL_ "GenSigRxStartValue" BU_SG_REL_ TIM_LS SG_ 2149859328 SysBkUpPwrMdV "1";
BA_REL_ "GenSigRxStartValue" BU_SG_REL_ ECC_LS SG_ 2149859328 SysBkUpPwrMdV "1";
BA_REL_ "GenSigRxStartValue" BU_SG_REL_ PEPS_LS SG_ 2149859328 SysBkUpPwrMdV "1";
BA_REL_ "GenSigRxStartValue" BU_SG_REL_ AOS_LS SG_ 2149859328 SysBkUpPwrMdV "1";
BA_REL_ "GenSigRxStartValue" BU_SG_REL_ SDM_PR_LS SG_ 2149859328 SysBkUpPwrMdV "1";
BA_REL_ "GenSigRxStartValue" BU_SG_REL_ UPA_LS SG_ 2149859328 SysBkUpPwrMdV "1";
BA_REL_ "GenSigRxStartValue" BU_SG_REL_ SCCM_2_LS SG_ 2149859328 SysBkupPwrMdEn "False";
BA_REL_ "GenSigSuprvResp" BU_SG_REL_ SCCM_2_LS SG_ 2149859328 SysBkupPwrMdEn 1;
BA_REL_ "GenSigRxStartValue" BU_SG_REL_ SCCM_1_LS SG_ 2149859328 SysBkupPwrMdEn "False";
BA_REL_ "GenSigSuprvResp" BU_SG_REL_ SCCM_1_LS SG_ 2149859328 SysBkupPwrMdEn 1;
BA_REL_ "GenSigSuprvResp" BU_SG_REL_ MCTM_LS SG_ 2149859328 SysBkupPwrMdEn 1;
BA_REL_ "GenSigSuprvResp" BU_SG_REL_ EOCM2cp_K2_LS SG_ 2149859328 SysBkupPwrMdEn 1;
BA_REL_ "GenSigSuprvResp" BU_SG_REL_ VICM_LS SG_ 2149859328 SysBkupPwrMdEn 1;
BA_REL_ "GenSigRxStartValue" BU_SG_REL_ TIM_LS SG_ 2149859328 SysBkupPwrMdEn "0";
BA_REL_ "GenSigSuprvResp" BU_SG_REL_ TIM_LS SG_ 2149859328 SysBkupPwrMdEn 1;
BA_REL_ "GenSigSuprvResp" BU_SG_REL_ ECC_LS SG_ 2149859328 SysBkupPwrMdEn 1;
BA_REL_ "GenSigRxStartValue" BU_SG_REL_ ECC_LS SG_ 2149859328 SysBkupPwrMdEn "0";
BA_REL_ "GenSigSuprvResp" BU_SG_REL_ ECC_LS SG_ 2149859328 SysBkupPwrMdEn 1;
BA_REL_ "GenSigRxStartValue" BU_SG_REL_ PEPS_LS SG_ 2149859328 SysBkupPwrMdEn "0";
BA_REL_ "GenSigSuprvResp" BU_SG_REL_ PEPS_LS SG_ 2149859328 SysBkupPwrMdEn 1;
BA_REL_ "GenSigRxStartValue" BU_SG_REL_ AOS_LS SG_ 2149859328 SysBkupPwrMdEn "0";
BA_REL_ "GenSigSuprvResp" BU_SG_REL_ AOS_LS SG_ 2149859328 SysBkupPwrMdEn 1;
BA_REL_ "GenSigRxStartValue" BU_SG_REL_ SDM_PR_LS SG_ 2149859328 SysBkupPwrMdEn "0";
BA_REL_ "GenSigSuprvResp" BU_SG_REL_ SDM_PR_LS SG_ 2149859328 SysBkupPwrMdEn 1;
BA_REL_ "GenSigRxStartValue" BU_SG_REL_ UPA_LS SG_ 2149859328 SysBkupPwrMdEn "0";
BA_REL_ "GenSigSuprvResp" BU_SG_REL_ UPA_LS SG_ 2149859328 SysBkupPwrMdEn 1;
BA_REL_ "GenSigSuprvResp" BU_SG_REL_ BCM_LS SG_ 2149859328 SysBkupPwrMdEn 1;
BA_REL_ "GenSigVBitResp" BU_SG_REL_ SCCM_2_LS SG_ 2149859328 SysBkUpPwrMd 1;
BA_REL_ "GenSigRxStartValue" BU_SG_REL_ SCCM_2_LS SG_ 2149859328 SysBkUpPwrMd "Off";
BA_REL_ "GenSigSuprvResp" BU_SG_REL_ SCCM_2_LS SG_ 2149859328 SysBkUpPwrMd 1;
BA_REL_ "GenSigVBitResp" BU_SG_REL_ SCCM_1_LS SG_ 2149859328 SysBkUpPwrMd 1;
BA_REL_ "GenSigRxStartValue" BU_SG_REL_ SCCM_1_LS SG_ 2149859328 SysBkUpPwrMd "Off";
BA_REL_ "GenSigSuprvResp" BU_SG_REL_ SCCM_1_LS SG_ 2149859328 SysBkUpPwrMd 1;
BA_REL_ "GenSigSuprvResp" BU_SG_REL_ MCTM_LS SG_ 2149859328 SysBkUpPwrMd 1;
BA_REL_ "GenSigVBitResp" BU_SG_REL_ EOCM2cp_K2_LS SG_ 2149859328 SysBkUpPwrMd 1;
BA_REL_ "GenSigSuprvResp" BU_SG_REL_ EOCM2cp_K2_LS SG_ 2149859328 SysBkUpPwrMd 1;
BA_REL_ "GenSigSuprvResp" BU_SG_REL_ VICM_LS SG_ 2149859328 SysBkUpPwrMd 1;
BA_REL_ "GenSigVBitResp" BU_SG_REL_ TIM_LS SG_ 2149859328 SysBkUpPwrMd 1;
BA_REL_ "GenSigSuprvResp" BU_SG_REL_ TIM_LS SG_ 2149859328 SysBkUpPwrMd 1;
BA_REL_ "GenSigSuprvResp" BU_SG_REL_ ECC_LS SG_ 2149859328 SysBkUpPwrMd 1;
BA_REL_ "GenSigVBitResp" BU_SG_REL_ ECC_LS SG_ 2149859328 SysBkUpPwrMd 1;
BA_REL_ "GenSigSuprvResp" BU_SG_REL_ ECC_LS SG_ 2149859328 SysBkUpPwrMd 1;
BA_REL_ "GenSigVBitResp" BU_SG_REL_ PEPS_LS SG_ 2149859328 SysBkUpPwrMd 1;
BA_REL_ "GenSigSuprvResp" BU_SG_REL_ PEPS_LS SG_ 2149859328 SysBkUpPwrMd 1;
BA_REL_ "GenSigVBitResp" BU_SG_REL_ AOS_LS SG_ 2149859328 SysBkUpPwrMd 1;
BA_REL_ "GenSigSuprvResp" BU_SG_REL_ AOS_LS SG_ 2149859328 SysBkUpPwrMd 1;
BA_REL_ "GenSigVBitResp" BU_SG_REL_ SDM_PR_LS SG_ 2149859328 SysBkUpPwrMd 1;
BA_REL_ "GenSigSuprvResp" BU_SG_REL_ SDM_PR_LS SG_ 2149859328 SysBkUpPwrMd 1;
BA_REL_ "GenSigVBitResp" BU_SG_REL_ UPA_LS SG_ 2149859328 SysBkUpPwrMd 1;
BA_REL_ "GenSigSuprvResp" BU_SG_REL_ UPA_LS SG_ 2149859328 SysBkUpPwrMd 1;
BA_REL_ "GenSigVBitResp" BU_SG_REL_ BCM_LS SG_ 2149859328 SysBkUpPwrMd 1;
BA_REL_ "GenSigSuprvResp" BU_SG_REL_ BCM_LS SG_ 2149859328 SysBkUpPwrMd 1;
BA_REL_ "GenSigSuprvResp" BU_SG_REL_ EOCM2cp_K2_LS SG_ 2158854144 ODIAI_DaTy 1;
BA_REL_ "GenSigSuprvResp" BU_SG_REL_ UPA_LS SG_ 2158854144 ODIAI_DaTy 1;
BA_REL_ "GenSigSuprvResp" BU_SG_REL_ EOCM2cp_K2_LS SG_ 2158854144 ODIAI_FUCID 1;
BA_REL_ "GenSigSuprvResp" BU_SG_REL_ UPA_LS SG_ 2158854144 ODIAI_FUCID 1;
BA_REL_ "GenSigSuprvResp" BU_SG_REL_ EOCM2cp_K2_LS SG_ 2158854144 ODIAI_DspMID 1;
BA_REL_ "GenSigSuprvResp" BU_SG_REL_ UPA_LS SG_ 2158854144 ODIAI_DspMID 1;
BA_REL_ "GenSigSuprvResp" BU_SG_REL_ EOCM2cp_K2_LS SG_ 2158854144 ODIAI_ActnVal 1;
BA_REL_ "GenSigSuprvResp" BU_SG_REL_ UPA_LS SG_ 2158854144 ODIAI_ActnVal 1;
BA_REL_ "GenSigSuprvResp" BU_SG_REL_ EOCM2cp_K2_LS SG_ 2158854144 ODIAI_ActnID 1;
BA_REL_ "GenSigSuprvResp" BU_SG_REL_ UPA_LS SG_ 2158854144 ODIAI_ActnID 1;
BA_REL_ "GenSigSuprvResp" BU_SG_REL_ SDM_PR_LS SG_ 2149908480 BrkPedTrvlAchvd 1;
BA_REL_ "GenSigSuprvResp" BU_SG_REL_ SDM_PR_LS SG_ 2149908480 BrkPedTrvlAchvdV 1;
BA_REL_ "GenSigSuprvResp" BU_SG_REL_ MCTM_LS SG_ 2156920832 WiFiPssPhrsDgts1to8 1;
BA_REL_ "GenSigSuprvResp" BU_SG_REL_ MCTM_LS SG_ 2156937216 WiFiPssPhrsDgts17to24 1;
BA_REL_ "GenSigSuprvResp" BU_SG_REL_ MCTM_LS SG_ 2150604800 RRDoorAjarSwAct 1;
BA_REL_ "GenSigRxStartValue" BU_SG_REL_ BCM_LS SG_ 2150604800 RRDoorAjarSwAct "False";
BA_REL_ "GenSigRxStartValue" BU_SG_REL_ BCM_LS SG_ 2150604800 RRDoorAjarSwAct "False";
BA_REL_ "GenSigRxStartValue" BU_SG_REL_ BCM_LS SG_ 2150604800 RRDoorAjarSwAct "False";
BA_REL_ "GenSigSuprvResp" BU_SG_REL_ PEPS_LS SG_ 2150604800 RRDoorAjarSwAct 2;
BA_REL_ "GenSigRxStartValue" BU_SG_REL_ SDM_PR_LS SG_ 2150604800 RRDoorAjarSwAct "0";
BA_REL_ "GenSigSuprvResp" BU_SG_REL_ SDM_PR_LS SG_ 2150604800 RRDoorAjarSwAct 1;
BA_REL_ "GenSigSuprvResp" BU_SG_REL_ MCTM_LS SG_ 2150588416 PDAjrSwAtv 1;
BA_REL_ "GenSigSuprvResp" BU_SG_REL_ PEPS_LS SG_ 2150588416 PDAjrSwAtv 2;
BA_REL_ "GenSigRxStartValue" BU_SG_REL_ SDM_PR_LS SG_ 2150588416 PDAjrSwAtv "0";
BA_REL_ "GenSigSuprvResp" BU_SG_REL_ SDM_PR_LS SG_ 2150588416 PDAjrSwAtv 1;
BA_REL_ "GenSigSuprvResp" BU_SG_REL_ MCTM_LS SG_ 2150596608 RLDoorAjarSwAct 1;
BA_REL_ "GenSigRxStartValue" BU_SG_REL_ BCM_LS SG_ 2150596608 RLDoorAjarSwAct "False";
BA_REL_ "GenSigRxStartValue" BU_SG_REL_ BCM_LS SG_ 2150596608 RLDoorAjarSwAct "False";
BA_REL_ "GenSigRxStartValue" BU_SG_REL_ BCM_LS SG_ 2150596608 RLDoorAjarSwAct "False";
BA_REL_ "GenSigSuprvResp" BU_SG_REL_ PEPS_LS SG_ 2150596608 RLDoorAjarSwAct 2;
BA_REL_ "GenSigRxStartValue" BU_SG_REL_ SDM_PR_LS SG_ 2150596608 RLDoorAjarSwAct "0";
BA_REL_ "GenSigSuprvResp" BU_SG_REL_ SDM_PR_LS SG_ 2150596608 RLDoorAjarSwAct 1;
BA_REL_ "GenSigRxStartValue" BU_SG_REL_ DLM_LS SG_ 2155036672 ClmtCtrlTrgtTemp "-10";
BA_REL_ "GenSigSuprvResp" BU_SG_REL_ BCM_LS SG_ 2155036672 ACCompModReq 1;
BA_REL_ "GenSigVBitResp" BU_SG_REL_ BCM_LS SG_ 2155036672 ACCompNormLd 1;
BA_REL_ "GenSigSuprvResp" BU_SG_REL_ BCM_LS SG_ 2155036672 ACCompNormLd 1;
BA_REL_ "GenSigVDAFailComment" BU_SG_REL_ SDM_PR_LS SG_ 2150416384 EngTrqActExtRngV "Engine Virtual Device Availability";
BA_REL_ "GenSigVDAFailResp" BU_SG_REL_ SDM_PR_LS SG_ 2150416384 EngTrqActExtRngV 1;
BA_REL_ "GenSigVBitResp" BU_SG_REL_ SDM_PR_LS SG_ 2150416384 EngTrqActExtRng 1;
BA_REL_ "GenSigVDAFailComment" BU_SG_REL_ SDM_PR_LS SG_ 2150416384 EngTrqActExtRng "Engine Virtual Device Availability";
BA_REL_ "GenSigVDAFailResp" BU_SG_REL_ SDM_PR_LS SG_ 2150416384 EngTrqActExtRng 1;
BA_REL_ "GenSigSuprvResp" BU_SG_REL_ SDM_PR_LS SG_ 2150416384 EngTrqActExtRng 1;
BA_REL_ "GenSigRxStartValue" BU_SG_REL_ SCCM_2_LS SG_ 2150416384 EngRunAtv "False";
BA_REL_ "GenSigSuprvResp" BU_SG_REL_ SCCM_2_LS SG_ 2150416384 EngRunAtv 1;
BA_REL_ "GenSigRxStartValue" BU_SG_REL_ SCCM_1_LS SG_ 2150416384 EngRunAtv "False";
BA_REL_ "GenSigSuprvResp" BU_SG_REL_ SCCM_1_LS SG_ 2150416384 EngRunAtv 1;
BA_REL_ "GenSigSuprvResp" BU_SG_REL_ TIM_LS SG_ 2150416384 EngRunAtv 1;
BA_REL_ "GenSigSuprvResp" BU_SG_REL_ ECC_LS SG_ 2150416384 EngRunAtv 1;
BA_REL_ "GenSigSuprvResp" BU_SG_REL_ ECC_LS SG_ 2150416384 EngRunAtv 1;
BA_REL_ "GenSigSuprvResp" BU_SG_REL_ ECC_LS SG_ 2150416384 EngRunAtv 1;
BA_REL_ "GenSigSuprvResp" BU_SG_REL_ ECC_LS SG_ 2150416384 EngRunAtv 1;
BA_REL_ "GenSigSuprvResp" BU_SG_REL_ ECC_LS SG_ 2150416384 EngRunAtv 1;
BA_REL_ "GenSigSuprvResp" BU_SG_REL_ ECC_LS SG_ 2150416384 EngRunAtv 1;
BA_REL_ "GenSigSuprvResp" BU_SG_REL_ ECC_LS SG_ 2150416384 EngRunAtv 1;
BA_REL_ "GenSigSuprvResp" BU_SG_REL_ ECC_LS SG_ 2150416384 EngRunAtv 1;
BA_REL_ "GenSigVDAFailComment" BU_SG_REL_ SDM_PR_LS SG_ 2150416384 EngRunAtv "Engine Virtual Device Availability";
BA_REL_ "GenSigVDAFailResp" BU_SG_REL_ SDM_PR_LS SG_ 2150416384 EngRunAtv 1;
BA_REL_ "GenSigSuprvResp" BU_SG_REL_ SDM_PR_LS SG_ 2150416384 EngRunAtv 1;
BA_REL_ "GenSigVDAFailComment" BU_SG_REL_ SDM_PR_LS SG_ 2150416384 EngRunAtv "Engine Virtual Device Availability";
BA_REL_ "GenSigVDAFailResp" BU_SG_REL_ SDM_PR_LS SG_ 2150416384 EngRunAtv 1;
BA_REL_ "GenSigSuprvResp" BU_SG_REL_ SDM_PR_LS SG_ 2150416384 EngRunAtv 1;
BA_REL_ "GenSigVDAFailComment" BU_SG_REL_ SDM_PR_LS SG_ 2150416384 EngSpdStat "EngVDA";
BA_REL_ "GenSigVDAFailResp" BU_SG_REL_ SDM_PR_LS SG_ 2150416384 EngSpdStat 1;
BA_REL_ "GenSigSuprvResp" BU_SG_REL_ SDM_PR_LS SG_ 2150416384 EngSpdStat 1;
BA_REL_ "GenSigRxStartValue" BU_SG_REL_ SDM_PR_LS SG_ 2150416384 TrnsVDA "1";
BA_REL_ "GenSigSuprvResp" BU_SG_REL_ SDM_PR_LS SG_ 2150416384 TrnsVDA 1;
BA_REL_ "GenSigSuprvResp" BU_SG_REL_ SDM_PR_LS SG_ 2150416384 TransEstGear 1;
BA_REL_ "GenSigSuprvResp" BU_SG_REL_ SDM_PR_LS SG_ 2150416384 EngVDA 1;
BA_REL_ "GenSigRxStartValue" BU_SG_REL_ SDM_PR_LS SG_ 2150416384 EngVDA "1";
BA_REL_ "GenSigSuprvResp" BU_SG_REL_ SDM_PR_LS SG_ 2150416384 EngVDA 1;
BA_REL_ "GenSigVDAFailComment" BU_SG_REL_ SDM_PR_LS SG_ 2150408192 AccActPosV "Engine Virtual Device Availability";
BA_REL_ "GenSigVDAFailResp" BU_SG_REL_ SDM_PR_LS SG_ 2150408192 AccActPosV 1;
BA_REL_ "GenSigVDAFailComment" BU_SG_REL_ SDM_PR_LS SG_ 2150408192 EngSpd "Engine Virtual Device Availability";
BA_REL_ "GenSigVDAFailResp" BU_SG_REL_ SDM_PR_LS SG_ 2150408192 EngSpd 1;
BA_REL_ "GenSigSuprvResp" BU_SG_REL_ SDM_PR_LS SG_ 2150408192 EngSpd 1;
BA_REL_ "GenSigSuprvResp" BU_SG_REL_ ECC_LS SG_ 2150408192 EngSpd 1;
BA_REL_ "GenSigSuprvResp" BU_SG_REL_ ECC_LS SG_ 2150408192 EngSpd 1;
BA_REL_ "GenSigVBitResp" BU_SG_REL_ SDM_PR_LS SG_ 2150408192 TrnsShftLvrPos 1;
BA_REL_ "GenSigVDAFailComment" BU_SG_REL_ SDM_PR_LS SG_ 2150408192 TrnsShftLvrPos "Transmission Virtual Device Availability";
BA_REL_ "GenSigVDAFailResp" BU_SG_REL_ SDM_PR_LS SG_ 2150408192 TrnsShftLvrPos 1;
BA_REL_ "GenSigSuprvResp" BU_SG_REL_ SDM_PR_LS SG_ 2150408192 TrnsShftLvrPos 1;
BA_REL_ "GenSigVBitResp" BU_SG_REL_ UPA_LS SG_ 2150408192 TrnsShftLvrPos 1;
BA_REL_ "GenSigVDAFailComment" BU_SG_REL_ UPA_LS SG_ 2150408192 TrnsShftLvrPos "Transmission Virtual Device Availability";
BA_REL_ "GenSigVDAFailResp" BU_SG_REL_ UPA_LS SG_ 2150408192 TrnsShftLvrPos 1;
BA_REL_ "GenSigSuprvResp" BU_SG_REL_ UPA_LS SG_ 2150408192 TrnsShftLvrPos 1;
BA_REL_ "GenSigVBitResp" BU_SG_REL_ SDM_PR_LS SG_ 2150408192 AccActPos 1;
BA_REL_ "GenSigVDAFailComment" BU_SG_REL_ SDM_PR_LS SG_ 2150408192 AccActPos "Engine Virtual Device Availability";
BA_REL_ "GenSigVDAFailResp" BU_SG_REL_ SDM_PR_LS SG_ 2150408192 AccActPos 1;
BA_REL_ "GenSigSuprvResp" BU_SG_REL_ SDM_PR_LS SG_ 2150408192 AccActPos 1;
BA_REL_ "GenSigVDAFailComment" BU_SG_REL_ SDM_PR_LS SG_ 2150408192 ThrPosV "Engine Virtual Device Availability";
BA_REL_ "GenSigVDAFailResp" BU_SG_REL_ SDM_PR_LS SG_ 2150408192 ThrPosV 1;
BA_REL_ "GenSigRxStartValue" BU_SG_REL_ SDM_PR_LS SG_ 2150408192 ThrPosV "0";
BA_REL_ "GenSigVBitResp" BU_SG_REL_ SDM_PR_LS SG_ 2150408192 ThrPos 1;
BA_REL_ "GenSigVDAFailComment" BU_SG_REL_ SDM_PR_LS SG_ 2150408192 ThrPos "Engine Virtual Device Availability";
BA_REL_ "GenSigVDAFailResp" BU_SG_REL_ SDM_PR_LS SG_ 2150408192 ThrPos 1;
BA_REL_ "GenSigSuprvResp" BU_SG_REL_ SDM_PR_LS SG_ 2150408192 ThrPos 1;
BA_REL_ "GenSigSuprvResp" BU_SG_REL_ BCM_LS SG_ 2155954176 ClimCtrlAftBlowModActv 1;
BA_REL_ "GenSigRxStartValue" BU_SG_REL_ DLM_LS SG_ 2155954176 ClmCntFrBlwFnSp "0";
BA_REL_ "GenSigSuprvResp" BU_SG_REL_ BCM_LS SG_ 2155954176 ACHtIdleBstLevReq 1;
BA_REL_ "GenSigSuprvResp" BU_SG_REL_ PEPS_LS SG_ 2153971712 LftglsRelSwAct 1;
BA_REL_ "GenSigSuprvResp" BU_SG_REL_ MCTM_LS SG_ 2153971712 DDAjrSwAtv 1;
BA_REL_ "GenSigSuprvResp" BU_SG_REL_ PEPS_LS SG_ 2153971712 DDAjrSwAtv 1;
BA_REL_ "GenSigSuprvResp" BU_SG_REL_ SDM_PR_LS SG_ 2153971712 DDAjrSwAtv 1;
BA_REL_ "GenSigSuprvResp" BU_SG_REL_ VICM_LS SG_ 2149875712 BattCrntFltrd 1;
BA_REL_ "GenSigSuprvResp" BU_SG_REL_ ECC_LS SG_ 2149875712 BattCrntFltrd 1;
BA_REL_ "GenSigRxStartValue" BU_SG_REL_ SCCM_2_LS SG_ 2149875712 EnrgMgtLdShdRq "No Load Shedding";
BA_REL_ "GenSigSuprvResp" BU_SG_REL_ SCCM_2_LS SG_ 2149875712 EnrgMgtLdShdRq 1;
BA_REL_ "GenSigRxStartValue" BU_SG_REL_ SCCM_1_LS SG_ 2149875712 EnrgMgtLdShdRq "No Load Shedding";
BA_REL_ "GenSigSuprvResp" BU_SG_REL_ SCCM_1_LS SG_ 2149875712 EnrgMgtLdShdRq 1;
BA_REL_ "GenSigSuprvResp" BU_SG_REL_ ECC_LS SG_ 2149875712 EnrgMgtLdShdRq 1;
BA_REL_ "GenSigSuprvResp" BU_SG_REL_ ECC_LS SG_ 2149875712 EnrgMgtLdShdRq 1;
BA_REL_ "GenSigSuprvResp" BU_SG_REL_ ECC_LS SG_ 2149875712 EnrgMgtLdShdRq 1;
BA_REL_ "GenSigSuprvResp" BU_SG_REL_ ECC_LS SG_ 2149875712 EnrgMgtLdShdRq 1;
BA_REL_ "GenSigSuprvResp" BU_SG_REL_ PEPS_LS SG_ 2149875712 BatSOC 1;
BA_REL_ "GenSigRxStartValue" BU_SG_REL_ SCCM_2_LS SG_ 2149875712 BatVltV "Valid";
BA_REL_ "GenSigRxStartValue" BU_SG_REL_ SCCM_1_LS SG_ 2149875712 BatVltV "Valid";
BA_REL_ "GenSigVBitResp" BU_SG_REL_ SCCM_2_LS SG_ 2149875712 BatVlt 1;
BA_REL_ "GenSigRxStartValue" BU_SG_REL_ SCCM_2_LS SG_ 2149875712 BatVlt "3";
BA_REL_ "GenSigSuprvResp" BU_SG_REL_ SCCM_2_LS SG_ 2149875712 BatVlt 1;
BA_REL_ "GenSigVBitResp" BU_SG_REL_ SCCM_1_LS SG_ 2149875712 BatVlt 1;
BA_REL_ "GenSigRxStartValue" BU_SG_REL_ SCCM_1_LS SG_ 2149875712 BatVlt "3";
BA_REL_ "GenSigSuprvResp" BU_SG_REL_ SCCM_1_LS SG_ 2149875712 BatVlt 1;
BA_REL_ "GenSigSuprvResp" BU_SG_REL_ PEPS_LS SG_ 2149875712 BatVlt 1;
BA_REL_ "GenSigVBitResp" BU_SG_REL_ ECC_LS SG_ 2149875712 BatVlt 1;
BA_REL_ "GenSigSuprvResp" BU_SG_REL_ ECC_LS SG_ 2149875712 BatVlt 1;
BA_REL_ "GenSigVBitResp" BU_SG_REL_ ECC_LS SG_ 2149875712 BatVlt 1;
BA_REL_ "GenSigSuprvResp" BU_SG_REL_ ECC_LS SG_ 2149875712 BatVlt 1;
BA_REL_ "GenSigVBitResp" BU_SG_REL_ ECC_LS SG_ 2149875712 BatVlt 1;
BA_REL_ "GenSigSuprvResp" BU_SG_REL_ ECC_LS SG_ 2149875712 BatVlt 1;
BA_REL_ "GenSigVBitResp" BU_SG_REL_ ECC_LS SG_ 2149875712 BatVlt 1;
BA_REL_ "GenSigSuprvResp" BU_SG_REL_ ECC_LS SG_ 2149875712 BatVlt 1;
BA_REL_ "GenSigVBitResp" BU_SG_REL_ ECC_LS SG_ 2149875712 BatVlt 1;
BA_REL_ "GenSigSuprvResp" BU_SG_REL_ ECC_LS SG_ 2149875712 BatVlt 1;
BA_REL_ "GenSigVBitResp" BU_SG_REL_ ECC_LS SG_ 2149875712 BatVlt 1;
BA_REL_ "GenSigSuprvResp" BU_SG_REL_ ECC_LS SG_ 2149875712 BatVlt 1;
BA_REL_ "GenSigVBitResp" BU_SG_REL_ ECC_LS SG_ 2149875712 BatVlt 1;
BA_REL_ "GenSigSuprvResp" BU_SG_REL_ ECC_LS SG_ 2149875712 BatVlt 1;
BA_REL_ "GenSigSuprvResp" BU_SG_REL_ BCM_LS SG_ 2151186432 CtLghtDet 1;
BA_REL_ "GenSigRxStartValue" BU_SG_REL_ BCM_LS SG_ 2151186432 AutoBmSlctStat "0";
BA_REL_ "GenSigSuprvResp" BU_SG_REL_ BCM_LS SG_ 2151186432 AutoBmSlctStat 1;
BA_REL_ "GenSigSuprvResp" BU_SG_REL_ EOCM2cp_K1_LS SG_ 2149629952 FrFogLmpsAct 1;
BA_REL_ "GenSigSuprvResp" BU_SG_REL_ EOCM2cp_K1_LS SG_ 2149629952 HiBmReqd 1;
BA_REL_ "GenSigRxStartValue" BU_SG_REL_ TIM_LS SG_ 2149629952 PrkLtRightOn "0";
BA_REL_ "GenSigSuprvResp" BU_SG_REL_ TIM_LS SG_ 2149629952 PrkLtRightOn 1;
BA_REL_ "GenSigRxStartValue" BU_SG_REL_ TIM_LS SG_ 2149629952 PrkLtLeftOn "0";
BA_REL_ "GenSigSuprvResp" BU_SG_REL_ TIM_LS SG_ 2149629952 PrkLtLeftOn 1;
BA_REL_ "GenSigSuprvResp" BU_SG_REL_ EOCM2cp_K2_LS SG_ 2149629952 TrnSwAct 1;
BA_REL_ "GenSigSuprvResp" BU_SG_REL_ EOCM2cp_K1_LS SG_ 2149629952 TrnSwAct 1;
BA_REL_ "GenSigSuprvResp" BU_SG_REL_ EOCM2cp_K1_LS SG_ 2149629952 MainLghtSw 1;
BA_REL_ "GenSigSuprvResp" BU_SG_REL_ EOCM2cp_K2_LS SG_ 2149629952 LftTrnLmpAtv 1;
BA_REL_ "GenSigSuprvResp" BU_SG_REL_ EOCM2cp_K1_LS SG_ 2149629952 LftTrnLmpAtv 1;
BA_REL_ "GenSigSuprvResp" BU_SG_REL_ UPA_LS SG_ 2149629952 LftTrnLmpAtv 1;
BA_REL_ "GenSigRxStartValue" BU_SG_REL_ TIM_LS SG_ 2149629952 LftTrnLmpAtv "0";
BA_REL_ "GenSigSuprvResp" BU_SG_REL_ TIM_LS SG_ 2149629952 LftTrnLmpAtv 1;
BA_REL_ "GenSigSuprvResp" BU_SG_REL_ EOCM2cp_K2_LS SG_ 2149629952 RtTrnLmpAtv 1;
BA_REL_ "GenSigSuprvResp" BU_SG_REL_ EOCM2cp_K1_LS SG_ 2149629952 RtTrnLmpAtv 1;
BA_REL_ "GenSigSuprvResp" BU_SG_REL_ UPA_LS SG_ 2149629952 RtTrnLmpAtv 1;
BA_REL_ "GenSigRxStartValue" BU_SG_REL_ TIM_LS SG_ 2149629952 RtTrnLmpAtv "0";
BA_REL_ "GenSigSuprvResp" BU_SG_REL_ TIM_LS SG_ 2149629952 RtTrnLmpAtv 1;
BA_REL_ "GenSigSuprvResp" BU_SG_REL_ TIM_LS SG_ 2149629952 RevLmpAtv 1;
BA_REL_ "GenSigRxStartValue" BU_SG_REL_ TIM_LS SG_ 2149629952 RevLmpAtv "0";
BA_REL_ "GenSigSuprvResp" BU_SG_REL_ TIM_LS SG_ 2149629952 RevLmpAtv 1;
BA_REL_ "GenSigSuprvResp" BU_SG_REL_ EOCM2cp_K1_LS SG_ 2149629952 HdlmpBmSelectStat 1;
BA_REL_ "GenSigSuprvResp" BU_SG_REL_ EOCM2cp_K1_LS SG_ 2149629952 SrvlnceMdAct 1;
BA_REL_ "GenSigSuprvResp" BU_SG_REL_ EOCM2cp_K2_LS SG_ 2149629952 OtsdAmbtLtLvlStatV 1;
BA_REL_ "GenSigVBitResp" BU_SG_REL_ EOCM2cp_K2_LS SG_ 2149629952 OtsdAmbtLtLvlStat 1;
BA_REL_ "GenSigSuprvResp" BU_SG_REL_ EOCM2cp_K2_LS SG_ 2149629952 OtsdAmbtLtLvlStat 1;
BA_REL_ "GenSigVBitResp" BU_SG_REL_ EOCM2cp_K1_LS SG_ 2149629952 OtsdAmbtLtLvlStat 1;
BA_REL_ "GenSigSuprvResp" BU_SG_REL_ EOCM2cp_K1_LS SG_ 2149629952 OtsdAmbtLtLvlStat 1;
BA_REL_ "GenSigSuprvResp" BU_SG_REL_ EOCM2cp_K1_LS SG_ 2149629952 RrFogLmpsAct 1;
BA_REL_ "GenSigRxStartValue" BU_SG_REL_ TIM_LS SG_ 2149629952 RrFogLmpsAct "0";
BA_REL_ "GenSigSuprvResp" BU_SG_REL_ TIM_LS SG_ 2149629952 RrFogLmpsAct 1;
BA_REL_ "GenSigRxStartValue" BU_SG_REL_ TIM_LS SG_ 2149629952 PrkngLtsAct "0";
BA_REL_ "GenSigSuprvResp" BU_SG_REL_ TIM_LS SG_ 2149629952 PrkngLtsAct 1;
BA_REL_ "GenSigRxStartValue" BU_SG_REL_ TIM_LS SG_ 2149629952 BrkLtsAtv "0";
BA_REL_ "GenSigSuprvResp" BU_SG_REL_ TIM_LS SG_ 2149629952 BrkLtsAtv 1;
BA_REL_ "GenSigSuprvResp" BU_SG_REL_ EOCM2cp_K1_LS SG_ 2149629952 AutoBmSlctAllwd 1;
BA_REL_ "GenSigSuprvResp" BU_SG_REL_ EOCM2cp_K1_LS SG_ 2149629952 FlToPsSwAtv 1;
BA_REL_ "GenSigSuprvResp" BU_SG_REL_ SDM_PR_LS SG_ 2149646336 VehSpdAvgNDrvn 1;
BA_REL_ "GenSigSuprvResp" BU_SG_REL_ SDM_PR_LS SG_ 2149646336 VehSpdAvgNDrvn 1;
BA_REL_ "GenSigVBitResp" BU_SG_REL_ MCTM_LS SG_ 2149646336 VehSpdAvgNDrvn 1;
BA_REL_ "GenSigSuprvResp" BU_SG_REL_ MCTM_LS SG_ 2149646336 VehSpdAvgNDrvn 1;
BA_REL_ "GenSigVDAFailComment" BU_SG_REL_ UPA_LS SG_ 2149646336 VehSpdAvgNDrvn "EngVDA";
BA_REL_ "GenSigVDAFailResp" BU_SG_REL_ UPA_LS SG_ 2149646336 VehSpdAvgNDrvn 1;
BA_REL_ "GenSigSuprvResp" BU_SG_REL_ UPA_LS SG_ 2149646336 VehSpdAvgNDrvn 1;
BA_REL_ "GenSigVDAFailComment" BU_SG_REL_ SDM_PR_LS SG_ 2149646336 DistRollCntAvgDrvnV "Engine Virtual Device Availability";
BA_REL_ "GenSigVDAFailResp" BU_SG_REL_ SDM_PR_LS SG_ 2149646336 DistRollCntAvgDrvnV 1;
BA_REL_ "GenSigRxStartValue" BU_SG_REL_ SDM_PR_LS SG_ 2149646336 DistRollCntAvgDrvnV "0";
BA_REL_ "GenSigVBitResp" BU_SG_REL_ SDM_PR_LS SG_ 2149646336 DistRollCntAvgDrvn 1;
BA_REL_ "GenSigVDAFailComment" BU_SG_REL_ SDM_PR_LS SG_ 2149646336 DistRollCntAvgDrvn "Engine Virtual Device Availability";
BA_REL_ "GenSigVDAFailResp" BU_SG_REL_ SDM_PR_LS SG_ 2149646336 DistRollCntAvgDrvn 1;
BA_REL_ "GenSigSuprvResp" BU_SG_REL_ SDM_PR_LS SG_ 2149646336 DistRollCntAvgDrvn 1;
BA_REL_ "GenSigRxStartValue" BU_SG_REL_ SCCM_2_LS SG_ 2149646336 VehSpdAvgDrvnV "Valid";
BA_REL_ "GenSigRxStartValue" BU_SG_REL_ SCCM_1_LS SG_ 2149646336 VehSpdAvgDrvnV "Valid";
BA_REL_ "GenSigVDAFailComment" BU_SG_REL_ SDM_PR_LS SG_ 2149646336 VehSpdAvgDrvnV "Engine Virtual Device Availability";
BA_REL_ "GenSigVDAFailResp" BU_SG_REL_ SDM_PR_LS SG_ 2149646336 VehSpdAvgDrvnV 1;
BA_REL_ "GenSigVBitResp" BU_SG_REL_ SCCM_2_LS SG_ 2149646336 VehSpdAvgDrvn 1;
BA_REL_ "GenSigRxStartValue" BU_SG_REL_ SCCM_2_LS SG_ 2149646336 VehSpdAvgDrvn "0";
BA_REL_ "GenSigSuprvResp" BU_SG_REL_ SCCM_2_LS SG_ 2149646336 VehSpdAvgDrvn 1;
BA_REL_ "GenSigVBitResp" BU_SG_REL_ SCCM_1_LS SG_ 2149646336 VehSpdAvgDrvn 1;
BA_REL_ "GenSigRxStartValue" BU_SG_REL_ SCCM_1_LS SG_ 2149646336 VehSpdAvgDrvn "0";
BA_REL_ "GenSigSuprvResp" BU_SG_REL_ SCCM_1_LS SG_ 2149646336 VehSpdAvgDrvn 1;
BA_REL_ "GenSigSuprvResp" BU_SG_REL_ TIM_LS SG_ 2149646336 VehSpdAvgDrvn 1;
BA_REL_ "GenSigVDAFailComment" BU_SG_REL_ UPA_LS SG_ 2149646336 VehSpdAvgDrvn "EngVDA";
BA_REL_ "GenSigVDAFailResp" BU_SG_REL_ UPA_LS SG_ 2149646336 VehSpdAvgDrvn 1;
BA_REL_ "GenSigSuprvResp" BU_SG_REL_ UPA_LS SG_ 2149646336 VehSpdAvgDrvn 1;
BA_REL_ "GenSigVBitResp" BU_SG_REL_ SDM_PR_LS SG_ 2149646336 VehSpdAvgDrvn 1;
BA_REL_ "GenSigVDAFailComment" BU_SG_REL_ SDM_PR_LS SG_ 2149646336 VehSpdAvgDrvn "Engine Virtual Device Availability";
BA_REL_ "GenSigVDAFailResp" BU_SG_REL_ SDM_PR_LS SG_ 2149646336 VehSpdAvgDrvn 1;
BA_REL_ "GenSigSuprvResp" BU_SG_REL_ SDM_PR_LS SG_ 2149646336 VehSpdAvgDrvn 1;
BA_REL_ "GenSigVBitResp" BU_SG_REL_ SDM_PR_LS SG_ 2149646336 VehSpdAvgDrvn 1;
BA_REL_ "GenSigSuprvResp" BU_SG_REL_ SDM_PR_LS SG_ 2149646336 VehSpdAvgDrvn 1;
BA_REL_ "GenSigSuprvResp" BU_SG_REL_ EOCM2cp_K2_LS SG_ 2154053632 CargoLmpActIO 1;
BA_REL_ "GenSigSuprvResp" BU_SG_REL_ EOCM2cp_K2_LS SG_ 2154053632 CargoLmpActIO 1;
BA_REL_ "GenSigSuprvResp" BU_SG_REL_ MCTM_LS SG_ 2154053632 DispNtSchmAtv 1;
BA_REL_ "GenSigSuprvResp" BU_SG_REL_ EOCM2cp_K2_LS SG_ 2154053632 DispNtSchmAtv 1;
BA_REL_ "GenSigSuprvResp" BU_SG_REL_ EOCM2cp_K2_LS SG_ 2154053632 DispNtSchmAtv 1;
BA_REL_ "GenSigSuprvResp" BU_SG_REL_ SDM_PR_LS SG_ 2154053632 DispNtSchmAtv 1;
BA_REL_ "GenSigSuprvResp" BU_SG_REL_ EOCM2cp_K2_LS SG_ 2154053632 IntDimLvl 1;
BA_REL_ "GenSigSuprvResp" BU_SG_REL_ EOCM2cp_K2_LS SG_ 2154053632 IntDimLvl 1;
BA_REL_ "GenSigSuprvResp" BU_SG_REL_ ECC_LS SG_ 2154053632 IntDimLvl 1;
BA_REL_ "GenSigSuprvResp" BU_SG_REL_ EOCM2cp_K2_LS SG_ 2154053632 IntDimDspLvl 1;
BA_REL_ "GenSigSuprvResp" BU_SG_REL_ EOCM2cp_K2_LS SG_ 2154053632 IntDimDspLvl 1;
BA_REL_ "GenSigSuprvResp" BU_SG_REL_ SDM_PR_LS SG_ 2154053632 IntDimDspLvl 1;
BA_REL_ "GenSigSuprvResp" BU_SG_REL_ ECC_LS SG_ 2154053632 IntDimDspLvl 1;
BA_REL_ "GenSigSuprvResp" BU_SG_REL_ EOCM2cp_K2_LS SG_ 2154053632 IntDimNtPnlAtv 1;
BA_REL_ "GenSigSuprvResp" BU_SG_REL_ EOCM2cp_K2_LS SG_ 2154053632 IntDimNtPnlAtv 1;
BA_REL_ "GenSigVBitResp" BU_SG_REL_ SCCM_2_LS SG_ 2149851136 SysPwrMd 1;
BA_REL_ "GenSigRxStartValue" BU_SG_REL_ SCCM_2_LS SG_ 2149851136 SysPwrMd "Off";
BA_REL_ "GenSigSuprvResp" BU_SG_REL_ SCCM_2_LS SG_ 2149851136 SysPwrMd 1;
BA_REL_ "GenSigVBitResp" BU_SG_REL_ SCCM_1_LS SG_ 2149851136 SysPwrMd 1;
BA_REL_ "GenSigRxStartValue" BU_SG_REL_ SCCM_1_LS SG_ 2149851136 SysPwrMd "Off";
BA_REL_ "GenSigSuprvResp" BU_SG_REL_ SCCM_1_LS SG_ 2149851136 SysPwrMd 1;
BA_REL_ "GenSigVBitResp" BU_SG_REL_ TIM_LS SG_ 2149851136 SysPwrMd 1;
BA_REL_ "GenSigSuprvResp" BU_SG_REL_ TIM_LS SG_ 2149851136 SysPwrMd 1;
BA_REL_ "GenSigVBitResp" BU_SG_REL_ ECC_LS SG_ 2149851136 SysPwrMd 1;
BA_REL_ "GenSigSuprvResp" BU_SG_REL_ ECC_LS SG_ 2149851136 SysPwrMd 1;
BA_REL_ "GenSigVBitResp" BU_SG_REL_ PEPS_LS SG_ 2149851136 SysPwrMd 1;
BA_REL_ "GenSigSuprvResp" BU_SG_REL_ PEPS_LS SG_ 2149851136 SysPwrMd 1;
BA_REL_ "GenSigVBitResp" BU_SG_REL_ AOS_LS SG_ 2149851136 SysPwrMd 1;
BA_REL_ "GenSigSuprvResp" BU_SG_REL_ AOS_LS SG_ 2149851136 SysPwrMd 1;
BA_REL_ "GenSigVBitResp" BU_SG_REL_ SDM_PR_LS SG_ 2149851136 SysPwrMd 1;
BA_REL_ "GenSigSuprvResp" BU_SG_REL_ SDM_PR_LS SG_ 2149851136 SysPwrMd 1;
BA_REL_ "GenSigVBitResp" BU_SG_REL_ UPA_LS SG_ 2149851136 SysPwrMd 1;
BA_REL_ "GenSigSuprvResp" BU_SG_REL_ UPA_LS SG_ 2149851136 SysPwrMd 1;
BA_REL_ "GenSigSuprvResp" BU_SG_REL_ MCTM_LS SG_ 2149851136 SysPwrMd 1;
BA_REL_ "GenSigRxStartValue" BU_SG_REL_ SCCM_2_LS SG_ 2149851136 SysPwrMdV "Valid";
BA_REL_ "GenSigRxStartValue" BU_SG_REL_ SCCM_1_LS SG_ 2149851136 SysPwrMdV "Valid";
BA_REL_ "GenSigRxStartValue" BU_SG_REL_ TIM_LS SG_ 2149851136 SysPwrMdV "1";
BA_REL_ "GenSigRxStartValue" BU_SG_REL_ ECC_LS SG_ 2149851136 SysPwrMdV "1";
BA_REL_ "GenSigRxStartValue" BU_SG_REL_ PEPS_LS SG_ 2149851136 SysPwrMdV "1";
BA_REL_ "GenSigRxStartValue" BU_SG_REL_ AOS_LS SG_ 2149851136 SysPwrMdV "1";
BA_REL_ "GenSigRxStartValue" BU_SG_REL_ SDM_PR_LS SG_ 2149851136 SysPwrMdV "1";
BA_REL_ "GenSigRxStartValue" BU_SG_REL_ UPA_LS SG_ 2149851136 SysPwrMdV "1";
BA_REL_ "GenSigSuprvResp" BU_SG_REL_ VICM_LS SG_ 2151530496 OfBrdHVCVhCsChRqRmt1 1;
BA_REL_ "GenSigSuprvResp" BU_SG_REL_ VICM_LS SG_ 2151530496 PrtyChrgRqRmt1 1;
BA_REL_ "GenSigSuprvResp" BU_SG_REL_ VICM_LS SG_ 2151530496 StTODChrgTmpOvrdRmt1 1;
BA_REL_ "GenSigSuprvResp" BU_SG_REL_ VICM_LS SG_ 2151530496 HVChgSyChgLvPfStRmt1 1;
BA_REL_ "GenSigSuprvResp" BU_SG_REL_ VICM_LS SG_ 2151530496 HVBatTmBsChgMdRqRmt1 1;
BA_REL_ "GenSigSuprvResp" BU_SG_REL_ VICM_LS SG_ 2151530496 HVBTBDCSRR1_DChMHSRq 1;
BA_REL_ "GenSigSuprvResp" BU_SG_REL_ VICM_LS SG_ 2151530496 HVBTBDCSRR1_DChSnSRq 1;
BA_REL_ "GenSigSuprvResp" BU_SG_REL_ VICM_LS SG_ 2151530496 HVBTBDCSRR1_DChSlSRq 1;
BA_REL_ "GenSigSuprvResp" BU_SG_REL_ VICM_LS SG_ 2151530496 HVBTBDCSRR1_DChDStRq 1;
BA_REL_ "GenSigSuprvResp" BU_SG_REL_ VICM_LS SG_ 2151530496 HVBTBDCSRR1_DChHStRq 1;
VAL_ 2150760448 NotiFrntLfPasSeatOccSta 5 "OccupiedLarge" 4 "OccupiedSmall" 3 "OccupiedChildseat" 2 "OccupiedUnknown" 1 "Empty" 0 "Unknown" ;
VAL_ 2150760448 NotSndRwRtSeatStat 0 "Unknown" 1 "Unfastened" 2 "Fastened" ;
VAL_ 2150760448 NotSndRwMdlSeatStat 0 "Unknown" 1 "Unfastened" 2 "Fastened" ;
VAL_ 2150760448 NotSndRwLtSeatStat 0 "Unknown" 1 "Unfastened" 2 "Fastened" ;
VAL_ 2150760448 NotPsSeatStat 0 "Unknown" 1 "Unfastened" 2 "Fastened" ;
VAL_ 2150760448 NotDrvSeatStat 0 "Unknown" 1 "Unfastened" 2 "Fastened" ;
VAL_ 2150760448 NotSecRowRtSeaOccStat 2 "Occupied" 1 "Empty" 0 "Unknown" ;
VAL_ 2150760448 NotSecRowLeSeaOccStat 2 "Occupied" 1 "Empty" 0 "Unknown" ;
VAL_ 2150760448 NotSecRowCtSeaOccStat 2 "Occupied" 1 "Empty" 0 "Unknown" ;
VAL_ 2150760448 NotiFrntPasSeatOccSta 5 "OccupiedLarge" 4 "OccupiedSmall" 3 "OccupiedChildseat" 2 "OccupiedUnknown" 1 "Empty" 0 "Unknown" ;
VAL_ 2150760448 NotEventStat 2 "Pretensioner Deployment Event" 1 "Near Deployment Event" 0 "No Event" 3 "Airbag Deployment Event" ;
VAL_ 2150760448 NESSRoSevSt 1 "true" 0 "false" ;
VAL_ 2150760448 NESSRiSiSevSt 1 "true" 0 "false" ;
VAL_ 2150760448 NESSReImpSevSt 1 "true" 0 "false" ;
VAL_ 2150760448 NESSLeSiSevSt 1 "true" 0 "false" ;
VAL_ 2150760448 NESSFrImpSt2SevSt 1 "true" 0 "false" ;
VAL_ 2150760448 NESSFrImpSt1SevSt 1 "true" 0 "false" ;
VAL_ 2150760448 NESSFrImpPreSevSt 1 "true" 0 "false" ;
VAL_ 2150760448 NEDLSRtSdArbgDld 1 "true" 0 "false" ;
VAL_ 2150760448 NEDLSLtSdArbgDld 1 "true" 0 "false" ;
VAL_ 2150760448 NEDLSSdCrtnArbgDpld 1 "true" 0 "false" ;
VAL_ 2150760448 NEDLSPaFrSt2De 1 "true" 0 "false" ;
VAL_ 2150760448 NEDLSPaFrSt1De 1 "true" 0 "false" ;
VAL_ 2150760448 NEDLSDrFrSt2De 1 "true" 0 "false" ;
VAL_ 2150760448 NEDLSDrFrSt1De 1 "true" 0 "false" ;
VAL_ 2150760448 SIRDpl 1 "true" 0 "false" ;
VAL_ 2155872256 FuelFltChgNwIO 1 "true" 0 "false" ;
VAL_ 2155872256 FlLvlPctV 1 "Invalid" 0 "Valid" ;
VAL_ 2155872256 FlInjRlCtRstOcc 1 "true" 0 "false" ;
VAL_ 2156175360 NtVsnSysEnbld 1 "true" 0 "false" ;
VAL_ 2156175360 DispMeasSysExt 2 "Imperial" 1 "US" 0 "Metric" ;
VAL_ 2156175360 DispMeasSys 1 "English" 0 "Metric" ;
VAL_ 2149859328 SysBkUpPwrMdV 1 "Invalid" 0 "Valid" ;
VAL_ 2149859328 SysBkupPwrMdEn 1 "true" 0 "false" ;
VAL_ 2149859328 SysBkUpPwrMd 3 "Crank Request" 2 "Run" 1 "Accessory" 0 "Off" ;
VAL_ 2158854144 ODIAI_DaTy 21 "Bitmap" 20 "DecimalShort" 19 "HoursOfDay" 18 "Character" 17 "Fuel Consumption Inverted" 16 "Fuel Consumption" 15 "Pressure" 14 "Temperature" 13 "Volume" 12 "DistanceShort" 11 "DistanceLong" 10 "BitmapId" 9 "TextId" 8 "Pictogram" 7 "List " 6 "Date" 5 "Time " 4 "Decimal" 3 "EnumerationValue" 2 "Integer" 1 "String" 0 "Speed" ;
VAL_ 2158854144 ODIAI_DspMID 128 "Reserved" 64 "Reserved" 32 "OTIM" 16 "RearDisplayTwo" 8 "RearDisplayOne" 4 "AuxIP" 2 "CenterStack" 1 "IPC" ;
VAL_ 2154561536 VehOdoV 1 "Invalid" 0 "Valid" ;
VAL_ 2149908480 BrkPedTrvlAchvd 1 "true" 0 "false" ;
VAL_ 2149908480 BrkPedTrvlAchvdV 1 "Invalid" 0 "Valid" ;
VAL_ 2149908480 BrkPdlModTrvlV 1 "Invalid" 0 "Valid" ;
VAL_ 2149908480 BrkPdlModTrvl 1 "true" 0 "false" ;
VAL_ 2151268352 ClmnLckTT 2 "Flashing Indication" 1 "Continuous Indication" 0 "No Indication" ;
VAL_ 2150604800 RRDoorAjarSwAct 1 "true" 0 "false" ;
VAL_ 2150588416 PDAjrSwAtv 1 "true" 0 "false" ;
VAL_ 2150596608 RLDoorAjarSwAct 1 "true" 0 "false" ;
VAL_ 2155036672 ACCompModReq 3 "No Action" 2 "Engage" 1 "Disengage" 0 "Disengage Immediately" ;
VAL_ 2155036672 ACCompNormLdV 1 "Invalid" 0 "Valid" ;
VAL_ 2155036672 ACCmEngRunReq 1 "Engine Run Requested" 0 "No Action" ;
VAL_ 2155036672 ACCmpsrFldOn 1 "true" 0 "false" ;
VAL_ 2150424576 EngTrqDrRqdExtRngV 1 "Invalid" 0 "Valid" ;
VAL_ 2150424576 EngAirIntBstPrV 1 "Invalid" 0 "Valid" ;
VAL_ 2150424576 TrnsRngInhbtStat 4 "Diagnostic Inhibit Active" 3 "Driveline Not Engaged" 2 "Transmission Range Re-Selection Req" 1 "Transmission Inhibit Active" 0 "No Range Inhibit Active" ;
VAL_ 2150424576 DrvtShftCntrlTrgtGear 10 "Tenth Gear" 9 "Ninth Gear" 8 "Eighth Gear" 7 "Seventh Gear" 6 "Sixth Gear" 5 "Fifth Gear" 4 "Fourth Gear" 3 "Third Gear" 2 "Second Gear" 1 "First Gear" 0 "Not Supported" ;
VAL_ 2150424576 TrnsEngdStateV 1 "Invalid" 0 "Valid" ;
VAL_ 2150424576 ACRfHiSdFldPrsV 1 "Invalid" 0 "Valid" ;
VAL_ 2150424576 ACCompCmnd 1 "On" 0 "Off" ;
VAL_ 2150424576 TrnsEngdState 3 "Operating State Not Reached" 2 "Transmission Engaged in Reverse" 1 "Transmission Engaged in Forward" 0 "Transmission Not Engaged" ;
VAL_ 2150416384 PTWrmgWtToShftIO 1 "true" 0 "false" ;
VAL_ 2150416384 EngTrqActExtRngV 1 "Invalid" 0 "Valid" ;
VAL_ 2150416384 VehTopSpdLmtMdAct 1 "true" 0 "false" ;
VAL_ 2150416384 EngRunAtv 1 "true" 0 "false" ;
VAL_ 2150416384 EngIdlAtv 1 "true" 0 "false" ;
VAL_ 2150416384 EngSpdStat 3 "Invalid" 1 "Degraded Operation" 0 "Normal Operation" ;
VAL_ 2150416384 VaccBoostFailure 1 "true" 0 "false" ;
VAL_ 2150416384 RmVhStrtEngRng 1 "true" 0 "false" ;
VAL_ 2150416384 TrnsVDA 1 "VirtualDeviceAvailable" 0 "VirtualDeviceUnavailable" ;
VAL_ 2150416384 GenFld 1 "true" 0 "false" ;
VAL_ 2150416384 EngSpdLmtnMdAct 1 "true" 0 "false" ;
VAL_ 2150416384 EngNEmsnsRelMalfAct 1 "true" 0 "false" ;
VAL_ 2150416384 EngCstFlCutAct 1 "true" 0 "false" ;
VAL_ 2150416384 EngCylDeactMd 3 "Reactivation In Progress" 2 "Half of Total Cylinders Active" 1 "Deactivation In Progress" 0 "All Cylinders Active" ;
VAL_ 2150416384 EngBstPrsIndV 1 "Invalid" 0 "Valid" ;
VAL_ 2150416384 TransEstGear 9 "Ninth Gear" 15 "Park Gear" 14 "Reverse Gear" 13 "Neutral Gear" 12 "CVT Forward Gear" 11 "Unused and Reserved" 10 "Tenth Gear" 8 "Eighth Gear" 7 "Seventh Gear" 6 "Sixth Gear" 5 "Fifth Gear" 4 "Fourth Gear" 3 "Third Gear" 2 "Second Gear" 1 "First Gear" 0 "Not Supported" ;
VAL_ 2150416384 TransEstGearV 1 "Invalid" 0 "Valid" ;
VAL_ 2150416384 EngVDA 1 "VirtualDeviceAvailable" 0 "VirtualDeviceUnavailable" ;
VAL_ 2150416384 TrnCrpMdAtv 1 "true" 0 "false" ;
VAL_ 2150408192 ElcRngSelDrvAct 1 "true" 0 "false" ;
VAL_ 2150408192 TmpDrvrShftCtlAct 1 "true" 0 "false" ;
VAL_ 2150408192 EngRunng 1 "true" 0 "false" ;
VAL_ 2150408192 Eng12vStrtrMtrCmmdOn 1 "true" 0 "false" ;
VAL_ 2150408192 AccPdlOvrrdAtv 1 "true" 0 "false" ;
VAL_ 2150408192 TopTrvlCltchSwActV 1 "Invalid" 0 "Valid" ;
VAL_ 2150408192 TopTrvlCltchSwAct 1 "true" 0 "false" ;
VAL_ 2150408192 CltStartSwAtvV 1 "Invalid" 0 "Valid" ;
VAL_ 2150408192 CltStartSwAtv 1 "true" 0 "false" ;
VAL_ 2150408192 CrsCntEnbld 1 "true" 0 "false" ;
VAL_ 2150408192 AccActPosV 1 "Invalid" 0 "Valid" ;
VAL_ 2150408192 TrnsShftLvrPosV 1 "Invalid" 0 "Valid" ;
VAL_ 2150408192 TrnsSftMdStat 3 "Automatic Grade Braking Mode" 2 "Lift-Foot Cornering Mode" 1 "Performance Mode" 0 "No Override Mode" ;
VAL_ 2150408192 AutoTransComndGear 9 "Ninth Gear" 15 "Park Gear" 14 "Reverse Gear" 13 "Neutral Gear" 12 "CVT Forward Gear" 11 "Unused and Reserved" 10 "Tenth Gear" 8 "Eighth Gear" 7 "Seventh Gear" 6 "Sixth Gear" 5 "Fifth Gear" 4 "Fourth Gear" 3 "Third Gear" 2 "Second Gear" 1 "First Gear" 0 "Not Supported" ;
VAL_ 2150408192 TrnShftPtrnActStat 6 "PT Protection Pattern Active" 5 "PT Non-Protection Pattern Active" 4 "Shift Pattern 4 Active" 3 "Shift Pattern 3 Active" 2 "Shift Pattern 2 Active" 1 "Shift Pattern 1 Active" 0 "Default Shift Pattern Active" ;
VAL_ 2150408192 TrnsShftLvrPos 13 "Forward Range J" 12 "Froward Range I" 15 "Lever Position Unknown" 11 "Forward Range H" 10 "Forward Range G" 9 "Forward Range F" 8 "Forward Range E" 7 "Forward Range D" 6 "Forward Range C" 5 "Forward Range B" 4 "Forward Range A" 3 "Neutral Range" 2 "Reverse Range" 1 "Park Range" 0 "Between Ranges" ;
VAL_ 2150408192 ThrPosV 1 "Invalid" 0 "Valid" ;
VAL_ 2150408192 TransTUDMdStat 2 "Electronic Range Select Active" 1 "Driver Shift Control Active" 0 "No Activation" ;
VAL_ 2155954176 ClmCntlExtDefActIO 1 "true" 0 "false" ;
VAL_ 2155954176 ClntCircPmpRq 1 "On" 0 "Off" ;
VAL_ 2155954176 ClimCtrlAftBlowModActv 1 "true" 0 "false" ;
VAL_ 2155954176 ACHtIdleBstLevReq 3 "Boost Level 3" 2 "Boost Level 2" 1 "Boost Level 1" 0 "No Boost Requested" ;
VAL_ 2155954176 AirCndActIO 1 "true" 0 "false" ;
VAL_ 2153971712 LftglsRelSwAct 1 "true" 0 "false" ;
VAL_ 2153971712 LftglsAjrSwAct 1 "true" 0 "false" ;
VAL_ 2153971712 DDAjrSwAtvM 1 "Use Data" 0 "Don't Use Data" ;
VAL_ 2153971712 DDAjrSwAtv 1 "true" 0 "false" ;
VAL_ 2149875712 BattStOfChrgLowIO 1 "true" 0 "false" ;
VAL_ 2149875712 IntlgntBattSnsFldIO 1 "true" 0 "false" ;
VAL_ 2149875712 BatSOCV 1 "Invalid" 0 "Valid" ;
VAL_ 2149875712 EnrgMgtLdShdRq 4 "Load Shed Level 4" 3 "Load Shed Level 3" 2 "Load Shed Level 2" 1 "Load Shed Level 1" 0 "No Load Shedding" ;
VAL_ 2149875712 SrvBattChrgSysIO 1 "true" 0 "false" ;
VAL_ 2149875712 BattStOfChrgCrtyLow 1 "true" 0 "false" ;
VAL_ 2149875712 BatSaverIO 1 "true" 0 "false" ;
VAL_ 2149875712 BattVltIRq 3 "Battery Voltage Very Low" 2 "Battery Voltage High" 1 "Battery Voltage Low" 0 "Battery Voltage OK" ;
VAL_ 2149875712 BatVltV 1 "Invalid" 0 "Valid" ;
VAL_ 2151186432 CtLghtDet 1 "true" 0 "false" ;
VAL_ 2151186432 AutoHgBmCtrlInOn 1 "true" 0 "false" ;
VAL_ 2151186432 AutoBmSlctStat 1 "Low  Beam" 0 "Disabled" 2 "High Beam" ;
VAL_ 2149629952 FrFogLmpsAct 1 "true" 0 "false" ;
VAL_ 2149629952 HiBmReqd 1 "true" 0 "false" ;
VAL_ 2149629952 PrkLtRightOn 1 "true" 0 "false" ;
VAL_ 2149629952 PrkLtLeftOn 1 "true" 0 "false" ;
VAL_ 2149629952 TrnSwAct 2 "Right" 1 "Left" 0 "No Activation" ;
VAL_ 2149629952 PrkLtRightIO 1 "true" 0 "false" ;
VAL_ 2149629952 MainLghtSw 3 "HEADLAMP" 2 "PARKLAMP" 1 "OFF" 0 "AUTO" ;
VAL_ 2149629952 PrkLtLeftIO 1 "true" 0 "false" ;
VAL_ 2149629952 HazSwAtv 1 "true" 0 "false" ;
VAL_ 2149629952 HiBmIO 1 "true" 0 "false" ;
VAL_ 2149629952 FrFgLtIO 1 "true" 0 "false" ;
VAL_ 2149629952 AutoLtsInactIO 1 "true" 0 "false" ;
VAL_ 2149629952 AutoLtsActIO 1 "true" 0 "false" ;
VAL_ 2149629952 LftTrnLmpAtv 2 "On with telltale" 1 "On without telltale" 0 "Off" ;
VAL_ 2149629952 RtTrnLmpAtv 2 "On with telltale" 1 "On without telltale" 0 "Off" ;
VAL_ 2149629952 RevLmpAtv 1 "true" 0 "false" ;
VAL_ 2149629952 HdlmpBmSelectStat 2 "High Beams" 1 "Low Beams" 0 "Unknown" ;
VAL_ 2149629952 SrvlnceMdAct 1 "true" 0 "false" ;
VAL_ 2149629952 RrFgLtIO 1 "true" 0 "false" ;
VAL_ 2149629952 PrkLtIO 1 "true" 0 "false" ;
VAL_ 2149629952 OtsdAmbtLtLvlStatV 1 "Invalid" 0 "Valid" ;
VAL_ 2149629952 OtsdAmbtLtLvlStat 2 "Day" 1 "Night" 0 "Unknown" ;
VAL_ 2149629952 RrFogLmpsAct 1 "true" 0 "false" ;
VAL_ 2149629952 PrkngLtsAct 1 "true" 0 "false" ;
VAL_ 2149629952 BrkLtsAtv 1 "true" 0 "false" ;
VAL_ 2149629952 AutoBmSlctAllwd 1 "true" 0 "false" ;
VAL_ 2149629952 FlToPsSwAtv 1 "true" 0 "false" ;
VAL_ 2149629952 DRLAct 1 "true" 0 "false" ;
VAL_ 2149646336 VehSpdAvgDrvnSrc 1 "Wheel Speed" 0 "Transmission Output Speed" ;
VAL_ 2149646336 VehSpdAvgNDrvnV 1 "Invalid" 0 "Valid" ;
VAL_ 2149646336 DstRolCntAvgNonDrvnV 1 "Invalid" 0 "Valid" ;
VAL_ 2149646336 DstRolCntAvNDrRstOc 1 "true" 0 "false" ;
VAL_ 2149646336 DstRolCntAvgDrnRstOc 1 "true" 0 "false" ;
VAL_ 2149646336 DistRollCntAvgDrvnV 1 "Invalid" 0 "Valid" ;
VAL_ 2149646336 DistRollCntAvgDrvnSrc 1 "Wheel Speed" 0 "Transmission Output Speed" ;
VAL_ 2149646336 VehSpdAvgDrvnV 1 "Invalid" 0 "Valid" ;
VAL_ 2154053632 CargoLmpActIO 1 "true" 0 "false" ;
VAL_ 2154053632 DispNtSchmAtv 1 "true" 0 "false" ;
VAL_ 2154053632 IntDimNtPnlAtv 1 "true" 0 "false" ;
VAL_ 2154217472 CrShrngFbsEnblReq 7 "Unused and Resrved 5" 6 "Unused and Resrved 4" 5 "Unused and Resrved 3" 4 "Unused and Resrved 2" 3 "Return State" 2 "Unused and Resrved 1" 1 "Disable Fobs" 0 "No Action" ;
VAL_ 2154217472 CSRCR_Cmnd 1 "Revoke Certificate" 0 "No Action" 7 "Unused and Resrved 5" 6 "Unused and Resrved 4" 5 "Unused and Resrved 3" 4 "Unused and Resrved 2" 3 "Unused and Resrved 1" 2 "Revoke All Certificate" ;
VAL_ 2149851136 KylsStrtAuthRq 1 "true" 0 "false" ;
VAL_ 2149851136 SysPwrMd 3 "Crank Request" 2 "Run" 1 "Accessory" 0 "Off" ;
VAL_ 2149851136 SysPwrMdV 1 "Invalid" 0 "Valid" ;
VAL_ 2151530496 OfBrdHVCVhCsChRqRmt1 1 "true" 0 "false" ;
VAL_ 2151530496 PrtyChrgRqRmt1 2 "Active" 1 "Inactive" 0 "No Action" ;
VAL_ 2151530496 StTODChrgTmpOvrdRmt1 0 "No Action" 1 "Inactive" 2 "Active" ;
VAL_ 2151530496 HVChgSyChgLvPfStRmt1 4 "Reduced Current Level 3" 3 "Reduced Current Level 2" 2 "Reduced Current Level 1" 1 "No Reduction" 0 "No Action" ;
VAL_ 2151530496 HVBatTmBsChgMdRqRmt1 3 "Rate Based Charge" 2 "Delayed Charge" 1 "Charge Now" 0 "No Action" ;
VAL_ 2151530496 HVBTBDCSRR1_DChSnSRq 3 "Yearly" 2 "Winter" 1 "Summer" 0 "No Action" ;
VAL_ 2151530496 HVBTBDCSRR1_DChSlSRq 8 "Unused and Reserved 4" 7 "Departure Time 2 Invalid" 6 "Unused and Reserved 3" 5 "Departure Time 2" 4 "Unused and Reserved 2" 3 "Departure Time 1 Invalid" 2 "Unused and Reserved 1" 1 "Departure Time 1" 0 "No Action" ;
VAL_ 2151530496 HVBTBDCSRR1_DChDStRq 6 "Friday" 5 "Thursday" 4 "Wednsday" 3 "Tuesday" 2 "Monday" 1 "Sunday" 0 "No Action" 10 "Sat and Sun Same" 9 "Mon To Fri Same" 8 "All Days Same" 7 "Saturday" ;
VAL_ 2151530496 TrPrsMntrTrLdStat 0 "Unknown" 1 "Light Load" 2 "Best Economy Load" 3 "Max Load" ;
VAL_ 2151530496 TrPrsMntrAtLocFld 1 "true" 0 "false" ;
VAL_ 2151530496 TireLocatnWarnEn 1 "true" 0 "false" ;
VAL_ 2151530496 WintTrRecIndOn 1 "true" 0 "false" ;
VAL_ 2151530496 TrPrsMntrFld 1 "true" 0 "false" ;
VAL_ 2151530496 TrRrAxlPresStat 2 "Tire Pressure Imbalance Warning" 1 "Tire Pressure Balanced" 0 "Unknown" ;
VAL_ 2151530496 TrFrntAxlPresStat 2 "Tire Pressure Imbalance Warning" 1 "Tire Pressure Balanced" 0 "Unknown" ;
VAL_ 2151530496 TPMTrLrnMdCmplt 1 "true" 0 "false" ;
SIG_GROUP_ 2150760448 NoEvSevSt 1 : NESSRoSevSt NESSRiSiSevSt NESSReImpSevSt NESSLeSiSevSt NESSFrImpSt2SevSt NESSFrImpSt1SevSt NESSFrImpPreSevSt;
SIG_GROUP_ 2150760448 NoEvDeLoSt 1 : NEDLSRtSdArbgDld NEDLSLtSdArbgDld NEDLSSdCrtnArbgDpld NEDLSPaFrSt2De NEDLSPaFrSt1De NEDLSDrFrSt2De NEDLSDrFrSt1De;
SIG_GROUP_ 2158854144 ODIActn_IPC 1 : ODIAI_DaTy ODIAI_FUCID ODIAI_DspMID ODIAI_ActnVal ODIAI_ActnID;
SIG_GROUP_ 2149908480 BrkPedInitTrvlAchvdStat 1 : BrkPedTrvlAchvd BrkPedTrvlAchvdV;
SIG_GROUP_ 2154217472 CrShrngRvkCertfctRq 1 : CSRCR_CrtfctIdntfcn CSRCR_Cmnd;
SIG_GROUP_ 2151530496 HVBatTmBsDlChStRqRmt1 1 : HVBTBDCSRR1_DChMHSRq HVBTBDCSRR1_DChSnSRq HVBTBDCSRR1_DChSlSRq HVBTBDCSRR1_DChDStRq HVBTBDCSRR1_DChHStRq;
